VERSION ""

NS_ :

BS_:
BU_: AerodynamicControl AuxiliaryHeater1 AuxiliaryHeater2 AuxiliaryValveControl AxleDrive1 AxleDrive2 AxleSteering BodyController BrakesDriveAxle1 BrakesDriveAxle2 BrakesSteerAxle BrakesSystemController CabController1 CabController2 CabDisplay1 ChassisController1 ChassisController2 ClimateControl1 ClimateControl2 ClutchUnit CommunicationUnitCellular CommunicationUnitRadio CommunicationUnitSatellite CruiseControl ElectricalChargingSystem ElectricalSystem EnduranceBrakingSystem Engine1 Engine2 EngineValveControl ExhaustEmissionController FanDriveController FileServer FuelSystem HeadwayController HitchControl HydraulicPumpController IgnitionController1 IgnitionController2 InformationSystem1 InstrumentCluster LightingOperatorControl ManagementComputer Node_0 Node_1 Node_10 Node_11 Node_12 Node_129 Node_13 Node_130 Node_133 Node_14 Node_15 Node_16 Node_17 Node_18 Node_19 Node_2 Node_20 Node_21 Node_22 Node_23 Node_24 Node_248 Node_249 Node_25 Node_250 Node_251 Node_26 Node_27 Node_28 Node_29 Node_3 Node_30 Node_31 Node_32 Node_33 Node_34 Node_35 Node_36 Node_37 Node_38 Node_39 Node_4 Node_40 Node_41 Node_42 Node_43 Node_44 Node_45 Node_46 Node_47 Node_48 Node_49 Node_5 Node_50 Node_51 Node_52 Node_53 Node_54 Node_55 Node_56 Node_57 Node_58 Node_59 Node_6 Node_60 Node_61 Node_62 Node_63 Node_64 Node_65 Node_66 Node_67 Node_68 Node_69 Node_7 Node_70 Node_71 Node_72 Node_73 Node_74 Node_75 Node_76 Node_77 Node_78 Node_79 Node_8 Node_80 Node_9 OffBoardDiagnosticTool1 OffBoardDiagnosticTool2 OffVehicleGateway OilSensor OnBoardDataLogger OnBoardDiagnosticUnit ParkingBrakeController PneumaticSystemController PowerTakeOff PowerTakeOffFront PropulsionBatteryCharger RampControl RearAxleSteeringController RetarderDriveline RetarderEngine RetarderExhaustEngine1 RetarderExhaustEngine2 SeatControl2 SeatController1 ShiftConsolePrimary ShiftConsoleSecondary StarterSystem SteeringColumnUnit SteeringController SuspensionDriveAxle1 SuspensionDriveAxle2 SuspensionSteerAxle SuspensionSystemController1 SuspensionSystemController2 TirePressureController TractorTrailerBridge1 Transmission1 Transmission2 TransmissionDisplay1 TransmissionDisplay2 TripRecorder Turbocharger VehicleDynamicStability VehicleNavigation VehicleSecurity VirtualTerminal WaterPumpController

BO_ 2565865982 EBC1: 8 Vector__XXX
   SG_ EngAuxShutdownSwitch : 28|2@1+ (1,0) [0|3] "" Vector__XXX
   SG_ SrcAddrssOfCtrllngDvcFrBrkCntrl : 48|8@1+ (1,0) [0|255] "" Vector__XXX
   SG_ BrakePedalPos : 8|8@1+ (0.4,0) [0|100] "%" Vector__XXX
   SG_ TrctrMntdTrilerABSWarningSignal : 62|2@1+ (1,0) [0|3] "" Vector__XXX
   SG_ TrailerABSStatus : 60|2@1+ (1,0) [0|3] "" Vector__XXX
   SG_ HaltBrakeSwitch : 58|2@1+ (1,0) [0|3] "" Vector__XXX
   SG_ ATC_ASRInformationSignal : 46|2@1+ (1,0) [0|3] "" Vector__XXX
   SG_ ABS_EBSAmberWarningSignal : 44|2@1+ (1,0) [0|3] "" Vector__XXX
   SG_ EBSRedWarningSignal : 42|2@1+ (1,0) [0|3] "" Vector__XXX
   SG_ ABSFullyOperational : 40|2@1+ (1,0) [0|3] "" Vector__XXX
   SG_ EngRetarderSelection : 32|8@1+ (0.4,0) [0|100] "%" Vector__XXX
   SG_ RemoteAccelEnableSwitch : 30|2@1+ (1,0) [0|3] "" Vector__XXX
   SG_ EngDerateSwitch : 26|2@1+ (1,0) [0|3] "" Vector__XXX
   SG_ AccelInterlockSwitch : 24|2@1+ (1,0) [0|3] "" Vector__XXX
   SG_ TractionCtrlOverrideSwitch : 22|2@1+ (1,0) [0|3] "" Vector__XXX
   SG_ ASRHillHolderSwitch : 20|2@1+ (1,0) [0|3] "" Vector__XXX
   SG_ ASROffroadSwitch : 18|2@1+ (1,0) [0|3] "" Vector__XXX
   SG_ ABSOffroadSwitch : 16|2@1+ (1,0) [0|3] "" Vector__XXX
   SG_ EBSBrakeSwitch : 6|2@1+ (1,0) [0|3] "" Vector__XXX
   SG_ AntiLockBrakingActive : 4|2@1+ (1,0) [0|3] "" Vector__XXX
   SG_ ASRBrakeCtrlActive : 2|2@1+ (1,0) [0|3] "" Vector__XXX
   SG_ ASREngCtrlActive : 0|2@1+ (1,0) [0|3] "" Vector__XXX

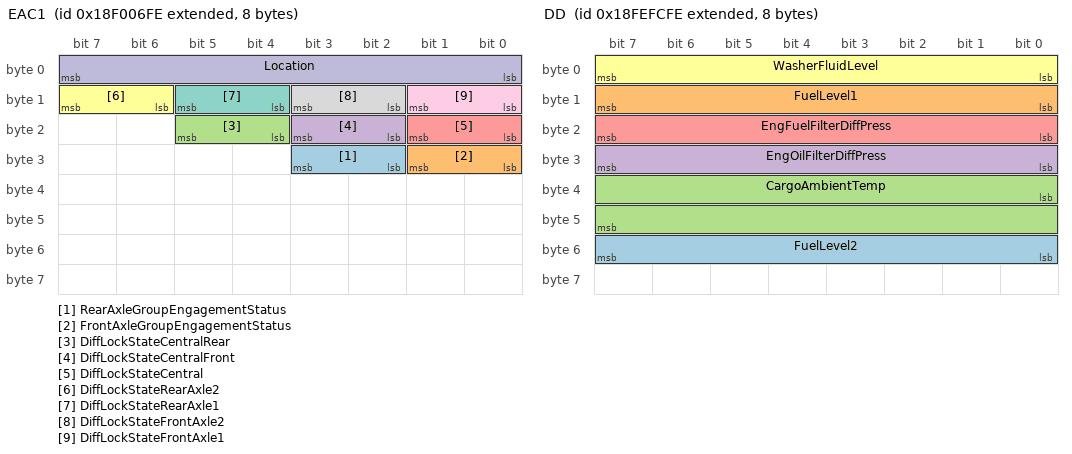
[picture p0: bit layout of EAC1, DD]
BO_ 2565867262 EAC1: 8 Vector__XXX
   SG_ RearAxleGroupEngagementStatus : 26|2@1+ (1,0) [0|3] "" Vector__XXX
   SG_ FrontAxleGroupEngagementStatus : 24|2@1+ (1,0) [0|3] "" Vector__XXX
   SG_ DiffLockStateCentralRear : 20|2@1+ (1,0) [0|3] "" Vector__XXX
   SG_ DiffLockStateCentralFront : 18|2@1+ (1,0) [0|3] "" Vector__XXX
   SG_ DiffLockStateCentral : 16|2@1+ (1,0) [0|3] "" Vector__XXX
   SG_ DiffLockStateRearAxle2 : 14|2@1+ (1,0) [0|3] "" Vector__XXX
   SG_ DiffLockStateRearAxle1 : 12|2@1+ (1,0) [0|3] "" Vector__XXX
   SG_ DiffLockStateFrontAxle2 : 10|2@1+ (1,0) [0|3] "" Vector__XXX
   SG_ DiffLockStateFrontAxle1 : 8|2@1+ (1,0) [0|3] "" Vector__XXX
   SG_ Location : 0|8@1+ (1,0) [0|255] "" Vector__XXX

BO_ 2566821118 EAC: 8 Vector__XXX
   SG_ SeaWaterPumpOutletPress : 16|8@1+ (2,0) [0|500] "kPa" Vector__XXX
   SG_ EngAuxCoolantTemp : 8|8@1+ (1,-40) [-40|210] "deg C" Vector__XXX
   SG_ EngAuxCoolantPress : 0|8@1+ (4,0) [0|1000] "kPa" Vector__XXX

BO_ 2566810622 DI: 8 Vector__XXX
   SG_ Driver2 : 8|8@1+ (1,0) [0|255] "" Vector__XXX
   SG_ Driver1 : 0|8@1+ (1,0) [0|255] "" Vector__XXX

BO_ 2566847742 DD: 8 Vector__XXX
   SG_ FuelLevel2 : 48|8@1+ (0.4,0) [0|100] "%" Vector__XXX
   SG_ FuelLevel1 : 8|8@1+ (0.4,0) [0|100] "%" Vector__XXX
   SG_ CargoAmbientTemp : 32|16@1+ (0.03125,-273) [-273|1734.97] "deg C" Vector__XXX
   SG_ EngOilFilterDiffPress : 24|8@1+ (0.5,0) [0|125] "kPa" Vector__XXX
   SG_ EngFuelFilterDiffPress : 16|8@1+ (2,0) [0|500] "kPa" Vector__XXX
   SG_ WasherFluidLevel : 0|8@1+ (0.4,0) [0|100] "%" Vector__XXX

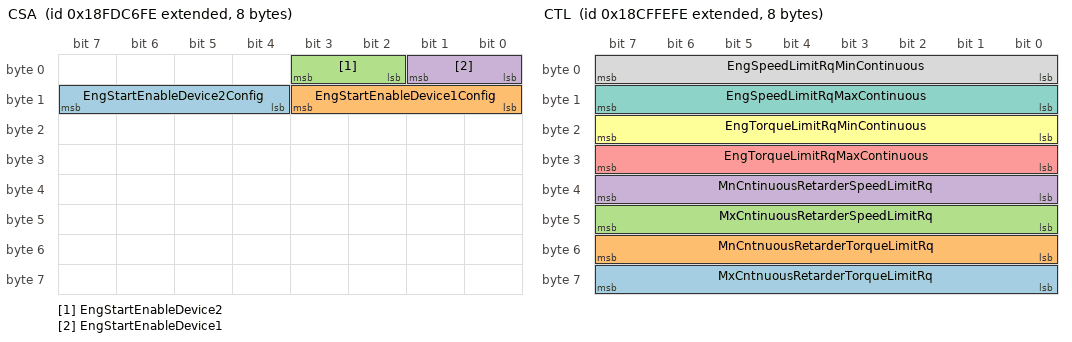
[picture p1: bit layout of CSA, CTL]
BO_ 2566768382 CSA: 8 Vector__XXX
   SG_ EngStartEnableDevice2Config : 12|4@1+ (1,0) [0|15] "" Vector__XXX
   SG_ EngStartEnableDevice1Config : 8|4@1+ (1,0) [0|15] "" Vector__XXX
   SG_ EngStartEnableDevice2 : 2|2@1+ (1,0) [0|3] "" Vector__XXX
   SG_ EngStartEnableDevice1 : 0|2@1+ (1,0) [0|3] "" Vector__XXX

BO_ 2566811902 CVW: 8 Vector__XXX
   SG_ PoweredVehicleWeight : 0|16@1+ (10,0) [0|642550] "kg" Vector__XXX
   SG_ GrossCombinationVehicleWeight : 16|16@1+ (10,0) [0|642550] "kg" Vector__XXX

BO_ 2563768062 CTL: 8 Vector__XXX
   SG_ MxCntnuousRetarderTorqueLimitRq : 56|8@1+ (1,-125) [-125|125] "%" Vector__XXX
   SG_ MnCntnuousRetarderTorqueLimitRq : 48|8@1+ (1,-125) [-125|125] "%" Vector__XXX
   SG_ MxCntinuousRetarderSpeedLimitRq : 40|8@1+ (32,0) [0|8000] "rpm" Vector__XXX
   SG_ MnCntinuousRetarderSpeedLimitRq : 32|8@1+ (32,0) [0|8000] "rpm" Vector__XXX
   SG_ EngTorqueLimitRqMaxContinuous : 24|8@1+ (1,-125) [-125|125] "%" Vector__XXX
   SG_ EngTorqueLimitRqMinContinuous : 16|8@1+ (1,-125) [-125|125] "%" Vector__XXX
   SG_ EngSpeedLimitRqMaxContinuous : 8|8@1+ (32,0) [0|8000] "rpm" Vector__XXX
   SG_ EngSpeedLimitRqMinContinuous : 0|8@1+ (32,0) [0|8000] "rpm" Vector__XXX

BO_ 2633924862 CT6: 8 Vector__XXX
   SG_ EngAverageCombustionTime : 16|16@1+ (0.01,0) [0|642.55] "ms" Vector__XXX
   SG_ EngDesiredCombustionTime : 0|16@1+ (0.01,0) [0|642.55] "ms" Vector__XXX

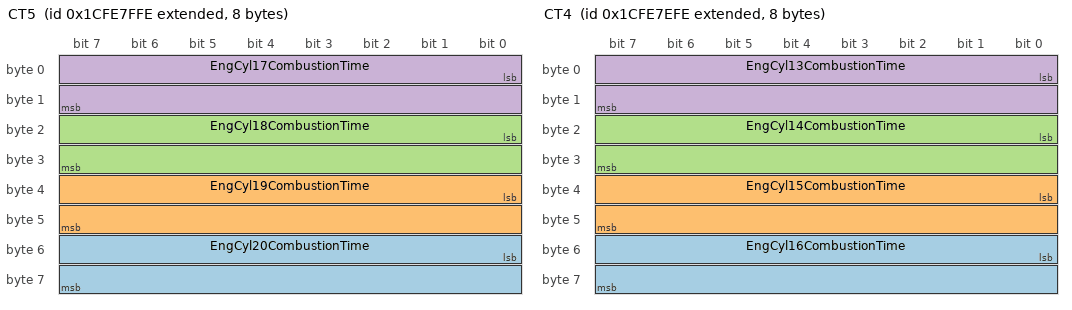
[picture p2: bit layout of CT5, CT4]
BO_ 2633924606 CT5: 8 Vector__XXX
   SG_ EngCyl20CombustionTime : 48|16@1+ (0.01,0) [0|642.55] "ms" Vector__XXX
   SG_ EngCyl19CombustionTime : 32|16@1+ (0.01,0) [0|642.55] "ms" Vector__XXX
   SG_ EngCyl18CombustionTime : 16|16@1+ (0.01,0) [0|642.55] "ms" Vector__XXX
   SG_ EngCyl17CombustionTime : 0|16@1+ (0.01,0) [0|642.55] "ms" Vector__XXX

BO_ 2633924350 CT4: 8 Vector__XXX
   SG_ EngCyl16CombustionTime : 48|16@1+ (0.01,0) [0|642.55] "ms" Vector__XXX
   SG_ EngCyl15CombustionTime : 32|16@1+ (0.01,0) [0|642.55] "ms" Vector__XXX
   SG_ EngCyl14CombustionTime : 16|16@1+ (0.01,0) [0|642.55] "ms" Vector__XXX
   SG_ EngCyl13CombustionTime : 0|16@1+ (0.01,0) [0|642.55] "ms" Vector__XXX

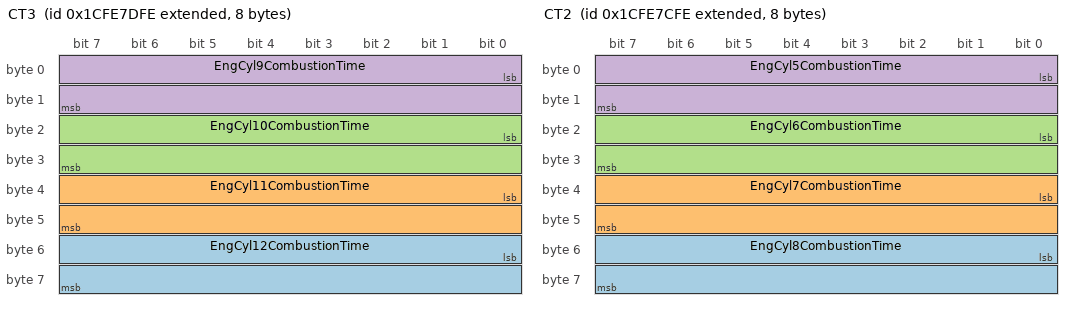
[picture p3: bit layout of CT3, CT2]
BO_ 2633924094 CT3: 8 Vector__XXX
   SG_ EngCyl12CombustionTime : 48|16@1+ (0.01,0) [0|642.55] "ms" Vector__XXX
   SG_ EngCyl11CombustionTime : 32|16@1+ (0.01,0) [0|642.55] "ms" Vector__XXX
   SG_ EngCyl10CombustionTime : 16|16@1+ (0.01,0) [0|642.55] "ms" Vector__XXX
   SG_ EngCyl9CombustionTime : 0|16@1+ (0.01,0) [0|642.55] "ms" Vector__XXX

BO_ 2633923838 CT2: 8 Vector__XXX
   SG_ EngCyl8CombustionTime : 48|16@1+ (0.01,0) [0|642.55] "ms" Vector__XXX
   SG_ EngCyl7CombustionTime : 32|16@1+ (0.01,0) [0|642.55] "ms" Vector__XXX
   SG_ EngCyl6CombustionTime : 16|16@1+ (0.01,0) [0|642.55] "ms" Vector__XXX
   SG_ EngCyl5CombustionTime : 0|16@1+ (0.01,0) [0|642.55] "ms" Vector__XXX

BO_ 2633923582 CT1: 8 Vector__XXX
   SG_ EngCyl4CombustionTime : 48|16@1+ (0.01,0) [0|642.55] "ms" Vector__XXX
   SG_ EngCyl3CombustionTime : 32|16@1+ (0.01,0) [0|642.55] "ms" Vector__XXX
   SG_ EngCyl2CombustionTime : 16|16@1+ (0.01,0) [0|642.55] "ms" Vector__XXX
   SG_ EngCyl1CombustionTime : 0|16@1+ (0.01,0) [0|642.55] "ms" Vector__XXX

BO_ 2633878014 CMI: 8 Vector__XXX
   SG_ TotalCountOfConfigChangesMade : 0|16@1+ (1,0) [0|64255] "counts" Vector__XXX

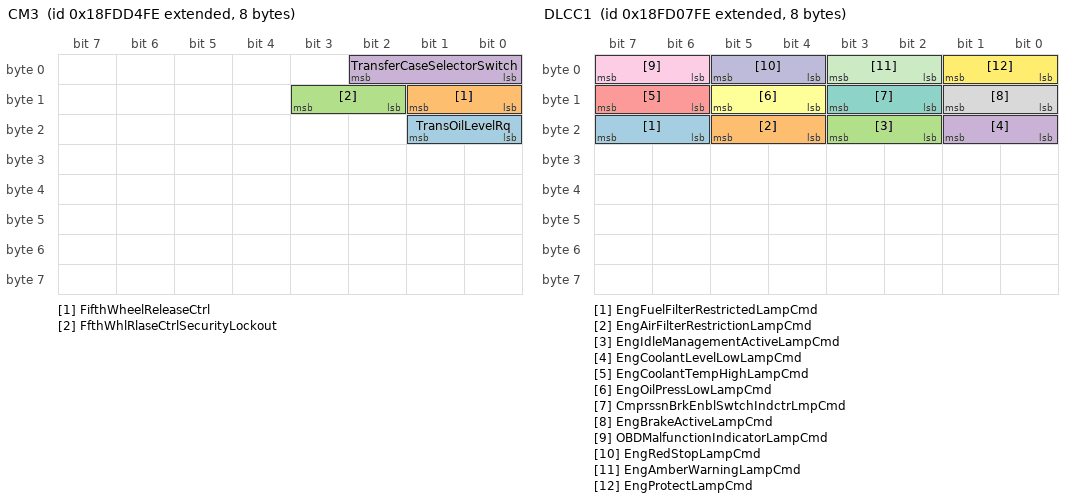
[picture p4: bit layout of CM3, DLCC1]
BO_ 2566771966 CM3: 8 Vector__XXX
   SG_ TransOilLevelRq : 16|2@1+ (1,0) [0|3] "" Vector__XXX
   SG_ FifthWheelReleaseCtrl : 8|2@1+ (1,0) [0|3] "" Vector__XXX
   SG_ FfthWhlRlaseCtrlSecurityLockout : 10|2@1+ (1,0) [0|3] "" Vector__XXX
   SG_ TransferCaseSelectorSwitch : 0|3@1+ (1,0) [0|7] "" Vector__XXX

BO_ 2564882174 CM1: 8 Vector__XXX
   SG_ DslPrtcltFltrRgnrtonForceSwitch : 42|2@1+ (1,0) [0|3] "" Vector__XXX
   SG_ DslPrtcltFltrRgnrtnInhbitSwitch : 40|2@1+ (1,0) [0|3] "" Vector__XXX
   SG_ SelectedMaxVehicleSpeedLimit : 56|8@1+ (1,0) [0|250] "" Vector__XXX
   SG_ RqCabZoneHeating : 54|2@1+ (1,0) [0|3] "" Vector__XXX
   SG_ RqEngZoneHeating : 52|2@1+ (1,0) [0|3] "" Vector__XXX
   SG_ AuxHeaterModeRq : 48|4@1+ (1,0) [0|15] "" Vector__XXX
   SG_ EngAutomaticStartEnableSwitch : 46|2@1+ (1,0) [0|3] "" Vector__XXX
   SG_ AtmaticGearShiftingEnableSwitch : 44|2@1+ (1,0) [0|3] "" Vector__XXX
   SG_ VhclLmtngSpdGvernorEnableSwitch : 38|2@1+ (1,0) [0|3] "" Vector__XXX
   SG_ VhclLmtngSpdGvrnrIncrmentSwitch : 36|2@1+ (1,0) [0|3] "" Vector__XXX
   SG_ VhclLmtngSpdGvrnrDcrementSwitch : 34|2@1+ (1,0) [0|3] "" Vector__XXX
   SG_ SeatBeltSwitch : 30|2@1+ (1,0) [0|3] "" Vector__XXX
   SG_ OperatorSeatDirectionSwitch : 28|2@1+ (1,0) [0|3] "" Vector__XXX
   SG_ BatteryMainSwitchHoldRq : 26|2@1+ (1,0) [0|3] "" Vector__XXX
   SG_ AuxHeaterCoolantPumpRq : 24|2@1+ (1,0) [0|3] "" Vector__XXX
   SG_ CabInteriorTempCmd : 8|16@1+ (0.03125,-273) [-273|1734.97] "deg C" Vector__XXX
   SG_ RqedPercentFanSpeed : 0|8@1+ (0.4,0) [0|100] "%" Vector__XXX

BO_ 2563833598 CL: 8 Vector__XXX
   SG_ IlluminationBrightnessPercent : 0|8@1+ (0.4,0) [0|100] "%" Vector__XXX

BO_ 2566843390 CI: 8 Vector__XXX
   SG_ UnitNumber : 24|8@1+ (1,0) [0|255] "" Vector__XXX
   SG_ SerialNumber : 16|8@1+ (1,0) [0|255] "" Vector__XXX
   SG_ Model : 8|8@1+ (1,0) [0|255] "" Vector__XXX
   SG_ Make : 0|8@1+ (1,0) [0|255] "" Vector__XXX

BO_ 2566844926 CCVS: 8 Vector__XXX
   SG_ ParkBrakeReleaseInhibitRq : 6|2@1+ (1,0) [0|3] "" Vector__XXX
   SG_ PTOGovernorState : 48|5@1+ (1,0) [0|31] "" Vector__XXX
   SG_ EngShutdownOverrideSwitch : 62|2@1+ (1,0) [0|3] "" Vector__XXX
   SG_ EngTestModeSwitch : 60|2@1+ (1,0) [0|3] "" Vector__XXX
   SG_ EngIdleDecrementSwitch : 58|2@1+ (1,0) [0|3] "" Vector__XXX
   SG_ EngIdleIncrementSwitch : 56|2@1+ (1,0) [0|3] "" Vector__XXX
   SG_ CruiseCtrlStates : 53|3@1+ (1,0) [0|7] "" Vector__XXX
   SG_ CruiseCtrlSetSpeed : 40|8@1+ (1,0) [0|250] "km/h" Vector__XXX
   SG_ CruiseCtrlAccelerateSwitch : 38|2@1+ (1,0) [0|3] "" Vector__XXX
   SG_ CruiseCtrlResumeSwitch : 36|2@1+ (1,0) [0|3] "" Vector__XXX
   SG_ CruiseCtrlCoastSwitch : 34|2@1+ (1,0) [0|3] "" Vector__XXX
   SG_ CruiseCtrlSetSwitch : 32|2@1+ (1,0) [0|3] "" Vector__XXX
   SG_ ClutchSwitch : 30|2@1+ (1,0) [0|3] "" Vector__XXX
   SG_ BrakeSwitch : 28|2@1+ (1,0) [0|3] "" Vector__XXX
   SG_ CruiseCtrlEnableSwitch : 26|2@1+ (1,0) [0|3] "" Vector__XXX
   SG_ CruiseCtrlActive : 24|2@1+ (1,0) [0|3] "" Vector__XXX
   SG_ WheelBasedVehicleSpeed : 8|16@1+ (0.00390625,0) [0|250.996] "km/h" Vector__XXX
   SG_ CruiseCtrlPauseSwitch : 4|2@1+ (1,0) [0|3] "" Vector__XXX
   SG_ ParkingBrakeSwitch : 2|2@1+ (1,0) [0|3] "" Vector__XXX
   SG_ TwoSpeedAxleSwitch : 0|2@1+ (1,0) [0|3] "" Vector__XXX

BO_ 2566843902 CCSS: 8 Vector__XXX
   SG_ CruiseCtrlLowSetLimitSpeed : 16|8@1+ (1,0) [0|250] "km/h" Vector__XXX
   SG_ CruiseCtrlHighSetLimitSpeed : 8|8@1+ (1,0) [0|250] "km/h" Vector__XXX
   SG_ MaxVehicleSpeedLimit : 0|8@1+ (1,0) [0|250] "km/h" Vector__XXX

BO_ 2566809598 CCC: 8 Vector__XXX
   SG_ AuxHeaterMaxOutputPower : 0|16@1+ (2,0) [0|128510] "W" Vector__XXX

BO_ 2633940222 CBI: 16 Vector__XXX
   SG_ TripServiceBrakeApps : 96|32@1+ (1,0) [0|4.22786e+09] "appl" Vector__XXX
   SG_ TripServiceBrakeDistance : 64|32@1+ (0.125,0) [0|5.26385e+08] "km" Vector__XXX
   SG_ TripCompressionBrakeDistance : 32|32@1+ (0.125,0) [0|5.26385e+08] "km" Vector__XXX
   SG_ TotalCompressionBrakeDistance : 0|32@1+ (0.125,0) [0|5.26385e+08] "km" Vector__XXX

BO_ 2566775294 CACI: 8 Vector__XXX
   SG_ CbA_CRfrgrntCmprssorOutletPress : 0|8@1+ (16,0) [0|4000] "kPa" Vector__XXX

BO_ 2566803710 BT1: 8 Vector__XXX
   SG_ Battery2Temp : 8|8@1+ (1,-40) [-40|210] "deg C" Vector__XXX
   SG_ Battery1Temp : 0|8@1+ (1,-40) [-40|210] "deg C" Vector__XXX

BO_ 2566719486 DLCC1: 8 Vector__XXX
   SG_ EngFuelFilterRestrictedLampCmd : 22|2@1+ (1,0) [0|3] "" Vector__XXX
   SG_ EngAirFilterRestrictionLampCmd : 20|2@1+ (1,0) [0|3] "" Vector__XXX
   SG_ EngIdleManagementActiveLampCmd : 18|2@1+ (1,0) [0|3] "" Vector__XXX
   SG_ EngCoolantLevelLowLampCmd : 16|2@1+ (1,0) [0|3] "" Vector__XXX
   SG_ EngCoolantTempHighLampCmd : 14|2@1+ (1,0) [0|3] "" Vector__XXX
   SG_ EngOilPressLowLampCmd : 12|2@1+ (1,0) [0|3] "" Vector__XXX
   SG_ CmprssnBrkEnblSwtchIndctrLmpCmd : 10|2@1+ (1,0) [0|3] "" Vector__XXX
   SG_ EngBrakeActiveLampCmd : 8|2@1+ (1,0) [0|3] "" Vector__XXX
   SG_ OBDMalfunctionIndicatorLampCmd : 6|2@1+ (1,0) [0|3] "" Vector__XXX
   SG_ EngRedStopLampCmd : 4|2@1+ (1,0) [0|3] "" Vector__XXX
   SG_ EngAmberWarningLampCmd : 2|2@1+ (1,0) [0|3] "" Vector__XXX
   SG_ EngProtectLampCmd : 0|2@1+ (1,0) [0|3] "" Vector__XXX

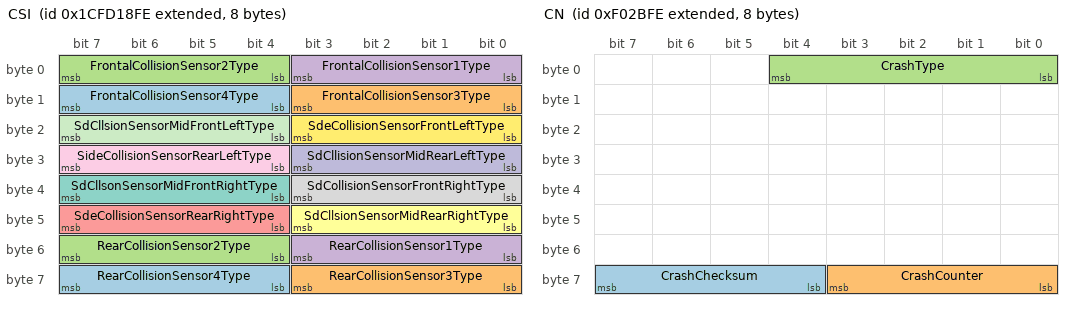
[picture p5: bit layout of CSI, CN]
BO_ 2633832702 CSI: 8 Vector__XXX
   SG_ RearCollisionSensor4Type : 60|4@1+ (1,0) [0|15] "" Vector__XXX
   SG_ RearCollisionSensor3Type : 56|4@1+ (1,0) [0|15] "" Vector__XXX
   SG_ RearCollisionSensor2Type : 52|4@1+ (1,0) [0|15] "" Vector__XXX
   SG_ RearCollisionSensor1Type : 48|4@1+ (1,0) [0|15] "" Vector__XXX
   SG_ SdeCollisionSensorRearRightType : 44|4@1+ (1,0) [0|15] "" Vector__XXX
   SG_ SdCllsionSensorMidRearRightType : 40|4@1+ (1,0) [0|15] "" Vector__XXX
   SG_ SdCllsonSensorMidFrontRightType : 36|4@1+ (1,0) [0|15] "" Vector__XXX
   SG_ SdCollisionSensorFrontRightType : 32|4@1+ (1,0) [0|15] "" Vector__XXX
   SG_ SideCollisionSensorRearLeftType : 28|4@1+ (1,0) [0|15] "" Vector__XXX
   SG_ SdCllisionSensorMidRearLeftType : 24|4@1+ (1,0) [0|15] "" Vector__XXX
   SG_ SdCllsionSensorMidFrontLeftType : 20|4@1+ (1,0) [0|15] "" Vector__XXX
   SG_ SdeCollisionSensorFrontLeftType : 16|4@1+ (1,0) [0|15] "" Vector__XXX
   SG_ FrontalCollisionSensor4Type : 12|4@1+ (1,0) [0|15] "" Vector__XXX
   SG_ FrontalCollisionSensor3Type : 8|4@1+ (1,0) [0|15] "" Vector__XXX
   SG_ FrontalCollisionSensor2Type : 4|4@1+ (1,0) [0|15] "" Vector__XXX
   SG_ FrontalCollisionSensor1Type : 0|4@1+ (1,0) [0|15] "" Vector__XXX

BO_ 2163223550 CN: 8 Vector__XXX
   SG_ CrashChecksum : 60|4@1+ (1,0) [0|15] "" Vector__XXX
   SG_ CrashCounter : 56|4@1+ (1,0) [0|15] "" Vector__XXX
   SG_ CrashType : 0|5@1+ (5,0) [0|0] "" Vector__XXX

BO_ 2566714878 CAC2P: 8 Vector__XXX
   SG_ EngChrgArClr2PrcoolerEfficiency : 32|8@1+ (0.4,0) [0|100] "%" Vector__XXX
   SG_ EngChrgArClr2PrcoolerOutletTemp : 16|16@1+ (0.03125,-273) [-273|1734.97] "deg C" Vector__XXX
   SG_ EngChrgArClr2PrcoolerIntakeTemp : 0|16@1+ (0.03125,-273) [-273|1734.97] "deg C" Vector__XXX

BO_ 2566714622 CAC2: 8 Vector__XXX
   SG_ EngChargeAirCooler2Efficiency : 48|8@1+ (0.4,0) [0|100] "%" Vector__XXX
   SG_ EngChrgAirCooler2AmbientAirTemp : 32|16@1+ (0.03125,-273) [-273|1734.97] "deg C" Vector__XXX
   SG_ EngChargeAirCooler2OutletTemp : 16|16@1+ (0.03125,-273) [-273|1734.97] "deg C" Vector__XXX
   SG_ EngChargeAirCooler2IntakeTemp : 0|16@1+ (0.03125,-273) [-273|1734.97] "deg C" Vector__XXX

BO_ 2566715390 CAC1P: 8 Vector__XXX
   SG_ EngChrgArClr1PrcoolerEfficiency : 32|8@1+ (0.4,0) [0|100] "%" Vector__XXX
   SG_ EngChrgArClr1PrcoolerOutletTemp : 16|16@1+ (0.03125,-273) [-273|1734.97] "deg C" Vector__XXX
   SG_ EngChrgArClr1PrcoolerIntakeTemp : 0|16@1+ (0.03125,-273) [-273|1734.97] "deg C" Vector__XXX

BO_ 2566715134 CAC1: 8 Vector__XXX
   SG_ EngChargeAirCooler1Efficiency : 32|8@1+ (0.4,0) [0|100] "%" Vector__XXX
   SG_ EngChrgAirCooler1AmbientAirTemp : 16|16@1+ (0.03125,-273) [-273|1734.97] "deg C" Vector__XXX
   SG_ EngChargeAirCooler1IntakeTemp : 0|16@1+ (0.03125,-273) [-273|1734.97] "deg C" Vector__XXX

BO_ 2365400830 BJM9: 8 Vector__XXX
   SG_ Joystick9Button9PressedStatus : 62|2@1+ (1,0) [0|3] "" Vector__XXX
   SG_ Joystick9Button10PressedStatus : 60|2@1+ (1,0) [0|3] "" Vector__XXX
   SG_ Joystick9Button11PressedStatus : 58|2@1+ (1,0) [0|3] "" Vector__XXX
   SG_ Joystick9Button12PressedStatus : 56|2@1+ (1,0) [0|3] "" Vector__XXX
   SG_ Joystick9Button5PressedStatus : 54|2@1+ (1,0) [0|3] "" Vector__XXX
   SG_ Joystick9Button6PressedStatus : 52|2@1+ (1,0) [0|3] "" Vector__XXX
   SG_ Joystick9Button7PressedStatus : 50|2@1+ (1,0) [0|3] "" Vector__XXX
   SG_ Joystick9Button8PressedStatus : 48|2@1+ (1,0) [0|3] "" Vector__XXX
   SG_ Joystick9Button1PressedStatus : 46|2@1+ (1,0) [0|3] "" Vector__XXX
   SG_ Joystick9Button2PressedStatus : 44|2@1+ (1,0) [0|3] "" Vector__XXX
   SG_ Joystick9Button3PressedStatus : 42|2@1+ (1,0) [0|3] "" Vector__XXX
   SG_ Joystick9Button4PressedStatus : 40|2@1+ (1,0) [0|3] "" Vector__XXX
   SG_ Joystick9XAxisDetentPosStatus : 38|2@1+ (1,0) [0|3] "" Vector__XXX
   SG_ Joystick9YAxisDetentPosStatus : 36|2@1+ (1,0) [0|3] "" Vector__XXX
   SG_ Joystick9YAxisPos : 22|10@1+ (0.1,0) [0|102] "%" Vector__XXX
   SG_ Jystck9YAxsLvrFrwrdPstvPsStatus : 20|2@1+ (1,0) [0|3] "" Vector__XXX
   SG_ Jystck9YAxsLvrBckNgtvePosStatus : 18|2@1+ (1,0) [0|3] "" Vector__XXX
   SG_ Joystick9YAxisNeutralPosStatus : 16|2@1+ (1,0) [0|3] "" Vector__XXX
   SG_ Joystick9XAxisPos : 6|10@1+ (0.1,0) [0|102] "%" Vector__XXX
   SG_ Jystck9XAxsLvrRghtPstvPosStatus : 4|2@1+ (1,0) [0|3] "" Vector__XXX
   SG_ Jystck9XAxsLvrLftNgtvePosStatus : 2|2@1+ (1,0) [0|3] "" Vector__XXX
   SG_ Joystick9XAxisNeutralPosStatus : 0|2@1+ (1,0) [0|3] "" Vector__XXX

BO_ 2365401342 BJM8: 8 Vector__XXX
   SG_ Joystick8Button9PressedStatus : 62|2@1+ (1,0) [0|3] "" Vector__XXX
   SG_ Joystick8Button10PressedStatus : 60|2@1+ (1,0) [0|3] "" Vector__XXX
   SG_ Joystick8Button11PressedStatus : 58|2@1+ (1,0) [0|3] "" Vector__XXX
   SG_ Joystick8Button12PressedStatus : 56|2@1+ (1,0) [0|3] "" Vector__XXX
   SG_ Joystick8Button5PressedStatus : 54|2@1+ (1,0) [0|3] "" Vector__XXX
   SG_ Joystick8Button6PressedStatus : 52|2@1+ (1,0) [0|3] "" Vector__XXX
   SG_ Joystick8Button7PressedStatus : 50|2@1+ (1,0) [0|3] "" Vector__XXX
   SG_ Joystick8Button8PressedStatus : 48|2@1+ (1,0) [0|3] "" Vector__XXX
   SG_ Joystick8Button1PressedStatus : 46|2@1+ (1,0) [0|3] "" Vector__XXX
   SG_ Joystick8Button2PressedStatus : 44|2@1+ (1,0) [0|3] "" Vector__XXX
   SG_ Joystick8Button3PressedStatus : 42|2@1+ (1,0) [0|3] "" Vector__XXX
   SG_ Joystick8Button4PressedStatus : 40|2@1+ (1,0) [0|3] "" Vector__XXX
   SG_ Joystick8XAxisDetentPosStatus : 38|2@1+ (1,0) [0|3] "" Vector__XXX
   SG_ Joystick8YAxisDetentPosStatus : 36|2@1+ (1,0) [0|3] "" Vector__XXX
   SG_ Joystick8YAxisPos : 22|10@1+ (0.1,0) [0|102] "%" Vector__XXX
   SG_ Jystck8YAxsLvrFrwrdPstvPsStatus : 20|2@1+ (1,0) [0|3] "" Vector__XXX
   SG_ Jystck8YAxsLvrBckNgtvePosStatus : 18|2@1+ (1,0) [0|3] "" Vector__XXX
   SG_ Joystick8YAxisNeutralPosStatus : 16|2@1+ (1,0) [0|3] "" Vector__XXX
   SG_ Joystick8XAxisPos : 6|10@1+ (0.1,0) [0|102] "%" Vector__XXX
   SG_ Jystck8XAxsLvrRghtPstvPosStatus : 4|2@1+ (1,0) [0|3] "" Vector__XXX
   SG_ Jystck8XAxsLvrLftNgtvePosStatus : 2|2@1+ (1,0) [0|3] "" Vector__XXX
   SG_ Joystick8XAxisNeutralPosStatus : 0|2@1+ (1,0) [0|3] "" Vector__XXX

BO_ 2365401854 BJM7: 8 Vector__XXX
   SG_ Joystick7Button9PressedStatus : 62|2@1+ (1,0) [0|3] "" Vector__XXX
   SG_ Joystick7Button10PressedStatus : 60|2@1+ (1,0) [0|3] "" Vector__XXX
   SG_ Joystick7Button11PressedStatus : 58|2@1+ (1,0) [0|3] "" Vector__XXX
   SG_ Joystick7Button12PressedStatus : 56|2@1+ (1,0) [0|3] "" Vector__XXX
   SG_ Joystick7Button5PressedStatus : 54|2@1+ (1,0) [0|3] "" Vector__XXX
   SG_ Joystick7Button6PressedStatus : 52|2@1+ (1,0) [0|3] "" Vector__XXX
   SG_ Joystick7Button7PressedStatus : 50|2@1+ (1,0) [0|3] "" Vector__XXX
   SG_ Joystick7Button8PressedStatus : 48|2@1+ (1,0) [0|3] "" Vector__XXX
   SG_ Joystick7Button1PressedStatus : 46|2@1+ (1,0) [0|3] "" Vector__XXX
   SG_ Joystick7Button2PressedStatus : 44|2@1+ (1,0) [0|3] "" Vector__XXX
   SG_ Joystick7Button3PressedStatus : 42|2@1+ (1,0) [0|3] "" Vector__XXX
   SG_ Joystick7Button4PressedStatus : 40|2@1+ (1,0) [0|3] "" Vector__XXX
   SG_ Joystick7XAxisDetentPosStatus : 38|2@1+ (1,0) [0|3] "" Vector__XXX
   SG_ Joystick7YAxisDetentPosStatus : 36|2@1+ (1,0) [0|3] "" Vector__XXX
   SG_ Joystick7YAxisPos : 22|10@1+ (0.1,0) [0|102] "%" Vector__XXX
   SG_ Jystck7YAxsLvrFrwrdPstvPsStatus : 20|2@1+ (1,0) [0|3] "" Vector__XXX
   SG_ Jystck7YAxsLvrBckNgtvePosStatus : 18|2@1+ (1,0) [0|3] "" Vector__XXX
   SG_ Joystick7YAxisNeutralPosStatus : 16|2@1+ (1,0) [0|3] "" Vector__XXX
   SG_ Joystick7XAxisPos : 6|10@1+ (0.1,0) [0|102] "%" Vector__XXX
   SG_ Jystck7XAxsLvrRghtPstvPosStatus : 4|2@1+ (1,0) [0|3] "" Vector__XXX
   SG_ Jystck7XAxsLvrLftNgtvePosStatus : 2|2@1+ (1,0) [0|3] "" Vector__XXX
   SG_ Joystick7XAxisNeutralPosStatus : 0|2@1+ (1,0) [0|3] "" Vector__XXX

BO_ 2365402366 BJM6: 8 Vector__XXX
   SG_ Joystick6Button9PressedStatus : 62|2@1+ (1,0) [0|3] "" Vector__XXX
   SG_ Joystick6Button10PressedStatus : 60|2@1+ (1,0) [0|3] "" Vector__XXX
   SG_ Joystick6Button11PressedStatus : 58|2@1+ (1,0) [0|3] "" Vector__XXX
   SG_ Joystick6Button12PressedStatus : 56|2@1+ (1,0) [0|3] "" Vector__XXX
   SG_ Joystick6Button5PressedStatus : 54|2@1+ (1,0) [0|3] "" Vector__XXX
   SG_ Joystick6Button6PressedStatus : 52|2@1+ (1,0) [0|3] "" Vector__XXX
   SG_ Joystick6Button7PressedStatus : 50|2@1+ (1,0) [0|3] "" Vector__XXX
   SG_ Joystick6Button8PressedStatus : 48|2@1+ (1,0) [0|3] "" Vector__XXX
   SG_ Joystick6Button1PressedStatus : 46|2@1+ (1,0) [0|3] "" Vector__XXX
   SG_ Joystick6Button2PressedStatus : 44|2@1+ (1,0) [0|3] "" Vector__XXX
   SG_ Joystick6Button3PressedStatus : 42|2@1+ (1,0) [0|3] "" Vector__XXX
   SG_ Joystick6Button4PressedStatus : 40|2@1+ (1,0) [0|3] "" Vector__XXX
   SG_ Joystick6XAxisDetentPosStatus : 38|2@1+ (1,0) [0|3] "" Vector__XXX
   SG_ Joystick6YAxisDetentPosStatus : 36|2@1+ (1,0) [0|3] "" Vector__XXX
   SG_ Joystick6YAxisPos : 22|10@1+ (0.1,0) [0|102] "%" Vector__XXX
   SG_ Jystck6YAxsLvrFrwrdPstvPsStatus : 20|2@1+ (1,0) [0|3] "" Vector__XXX
   SG_ Jystck6YAxsLvrBckNgtvePosStatus : 18|2@1+ (1,0) [0|3] "" Vector__XXX
   SG_ Joystick6YAxisNeutralPosStatus : 16|2@1+ (1,0) [0|3] "" Vector__XXX
   SG_ Joystick6XAxisPos : 6|10@1+ (0.1,0) [0|102] "%" Vector__XXX
   SG_ Jystck6XAxsLvrRghtPstvPosStatus : 4|2@1+ (1,0) [0|3] "" Vector__XXX
   SG_ Jystck6XAxsLvrLftNgtvePosStatus : 2|2@1+ (1,0) [0|3] "" Vector__XXX
   SG_ Joystick6XAxisNeutralPosStatus : 0|2@1+ (1,0) [0|3] "" Vector__XXX

BO_ 2365402878 BJM5: 8 Vector__XXX
   SG_ Joystick5Button9PressedStatus : 62|2@1+ (1,0) [0|3] "" Vector__XXX
   SG_ Joystick5Button10PressedStatus : 60|2@1+ (1,0) [0|3] "" Vector__XXX
   SG_ Joystick5Button11PressedStatus : 58|2@1+ (1,0) [0|3] "" Vector__XXX
   SG_ Joystick5Button12PressedStatus : 56|2@1+ (1,0) [0|3] "" Vector__XXX
   SG_ Joystick5Button5PressedStatus : 54|2@1+ (1,0) [0|3] "" Vector__XXX
   SG_ Joystick5Button6PressedStatus : 52|2@1+ (1,0) [0|3] "" Vector__XXX
   SG_ Joystick5Button7PressedStatus : 50|2@1+ (1,0) [0|3] "" Vector__XXX
   SG_ Joystick5Button8PressedStatus : 48|2@1+ (1,0) [0|3] "" Vector__XXX
   SG_ Joystick5Button1PressedStatus : 46|2@1+ (1,0) [0|3] "" Vector__XXX
   SG_ Joystick5Button2PressedStatus : 44|2@1+ (1,0) [0|3] "" Vector__XXX
   SG_ Joystick5Button3PressedStatus : 42|2@1+ (1,0) [0|3] "" Vector__XXX
   SG_ Joystick5Button4PressedStatus : 40|2@1+ (1,0) [0|3] "" Vector__XXX
   SG_ Joystick5XAxisDetentPosStatus : 38|2@1+ (1,0) [0|3] "" Vector__XXX
   SG_ Joystick5YAxisDetentPosStatus : 36|2@1+ (1,0) [0|3] "" Vector__XXX
   SG_ Joystick5YAxisPos : 22|10@1+ (0.1,0) [0|102] "%" Vector__XXX
   SG_ Jystck5YAxsLvrFrwrdPstvPsStatus : 20|2@1+ (1,0) [0|3] "" Vector__XXX
   SG_ Jystck5YAxsLvrBckNgtvePosStatus : 18|2@1+ (1,0) [0|3] "" Vector__XXX
   SG_ Joystick5YAxisNeutralPosStatus : 16|2@1+ (1,0) [0|3] "" Vector__XXX
   SG_ Joystick5XAxisPos : 6|10@1+ (0.1,0) [0|102] "%" Vector__XXX
   SG_ Jystck5XAxsLvrRghtPstvPosStatus : 4|2@1+ (1,0) [0|3] "" Vector__XXX
   SG_ Jystck5XAxsLvrLftNgtvePosStatus : 2|2@1+ (1,0) [0|3] "" Vector__XXX
   SG_ Joystick5XAxisNeutralPosStatus : 0|2@1+ (1,0) [0|3] "" Vector__XXX

BO_ 2365403390 BJM4: 8 Vector__XXX
   SG_ Joystick4Button9PressedStatus : 62|2@1+ (1,0) [0|3] "" Vector__XXX
   SG_ Joystick4Button10PressedStatus : 60|2@1+ (1,0) [0|3] "" Vector__XXX
   SG_ Joystick4Button11PressedStatus : 58|2@1+ (1,0) [0|3] "" Vector__XXX
   SG_ Joystick4Button12PressedStatus : 56|2@1+ (1,0) [0|3] "" Vector__XXX
   SG_ Joystick4Button5PressedStatus : 54|2@1+ (1,0) [0|3] "" Vector__XXX
   SG_ Joystick4Button6PressedStatus : 52|2@1+ (1,0) [0|3] "" Vector__XXX
   SG_ Joystick4Button7PressedStatus : 50|2@1+ (1,0) [0|3] "" Vector__XXX
   SG_ Joystick4Button8PressedStatus : 48|2@1+ (1,0) [0|3] "" Vector__XXX
   SG_ Joystick4Button1PressedStatus : 46|2@1+ (1,0) [0|3] "" Vector__XXX
   SG_ Joystick4Button2PressedStatus : 44|2@1+ (1,0) [0|3] "" Vector__XXX
   SG_ Joystick4Button3PressedStatus : 42|2@1+ (1,0) [0|3] "" Vector__XXX
   SG_ Joystick4Button4PressedStatus : 40|2@1+ (1,0) [0|3] "" Vector__XXX
   SG_ Joystick4XAxisDetentPosStatus : 38|2@1+ (1,0) [0|3] "" Vector__XXX
   SG_ Joystick4YAxisDetentPosStatus : 36|2@1+ (1,0) [0|3] "" Vector__XXX
   SG_ Joystick4YAxisPos : 22|10@1+ (0.1,0) [0|102] "%" Vector__XXX
   SG_ Jystck4YAxsLvrFrwrdPstvPsStatus : 20|2@1+ (1,0) [0|3] "" Vector__XXX
   SG_ Jystck4YAxsLvrBckNgtvePosStatus : 18|2@1+ (1,0) [0|3] "" Vector__XXX
   SG_ Joystick4YAxisNeutralPosStatus : 16|2@1+ (1,0) [0|3] "" Vector__XXX
   SG_ Joystick4XAxisPos : 6|10@1+ (0.1,0) [0|102] "%" Vector__XXX
   SG_ Jystck4XAxsLvrRghtPstvPosStatus : 4|2@1+ (1,0) [0|3] "" Vector__XXX
   SG_ Jystck4XAxsLvrLftNgtvePosStatus : 2|2@1+ (1,0) [0|3] "" Vector__XXX
   SG_ Joystick4XAxisNeutralPosStatus : 0|2@1+ (1,0) [0|3] "" Vector__XXX

BO_ 2365400318 BJM10: 8 Vector__XXX
   SG_ Joystick10Button9PressedStatus : 62|2@1+ (1,0) [0|3] "" Vector__XXX
   SG_ Joystick10Button10PressedStatus : 60|2@1+ (1,0) [0|3] "" Vector__XXX
   SG_ Joystick10Button11PressedStatus : 58|2@1+ (1,0) [0|3] "" Vector__XXX
   SG_ Joystick10Button12PressedStatus : 56|2@1+ (1,0) [0|3] "" Vector__XXX
   SG_ Joystick10Button5PressedStatus : 54|2@1+ (1,0) [0|3] "" Vector__XXX
   SG_ Joystick10Button6PressedStatus : 52|2@1+ (1,0) [0|3] "" Vector__XXX
   SG_ Joystick10Button7PressedStatus : 50|2@1+ (1,0) [0|3] "" Vector__XXX
   SG_ Joystick10Button8PressedStatus : 48|2@1+ (1,0) [0|3] "" Vector__XXX
   SG_ Joystick10Button1PressedStatus : 46|2@1+ (1,0) [0|3] "" Vector__XXX
   SG_ Joystick10Button2PressedStatus : 44|2@1+ (1,0) [0|3] "" Vector__XXX
   SG_ Joystick10Button3PressedStatus : 42|2@1+ (1,0) [0|3] "" Vector__XXX
   SG_ Joystick10Button4PressedStatus : 40|2@1+ (1,0) [0|3] "" Vector__XXX
   SG_ Joystick10XAxisDetentPosStatus : 38|2@1+ (1,0) [0|3] "" Vector__XXX
   SG_ Joystick10YAxisDetentPosStatus : 36|2@1+ (1,0) [0|3] "" Vector__XXX
   SG_ Joystick10YAxisPos : 22|10@1+ (0.1,0) [0|102] "%" Vector__XXX
   SG_ Jystck10YAxsLvrFrwrdPstvPsSttus : 20|2@1+ (1,0) [0|3] "" Vector__XXX
   SG_ Jystck10YAxsLvrBckNgtvPosStatus : 18|2@1+ (1,0) [0|3] "" Vector__XXX
   SG_ Joystick10YAxisNeutralPosStatus : 16|2@1+ (1,0) [0|3] "" Vector__XXX
   SG_ Joystick10XAxisPos : 6|10@1+ (0.1,0) [0|102] "%" Vector__XXX
   SG_ Jystck10XAxsLvrRghtPstvPsStatus : 4|2@1+ (1,0) [0|3] "" Vector__XXX
   SG_ Jystck10XAxsLvrLftNgtvPosStatus : 2|2@1+ (1,0) [0|3] "" Vector__XXX
   SG_ Joystick10XAxisNeutralPosStatus : 0|2@1+ (1,0) [0|3] "" Vector__XXX

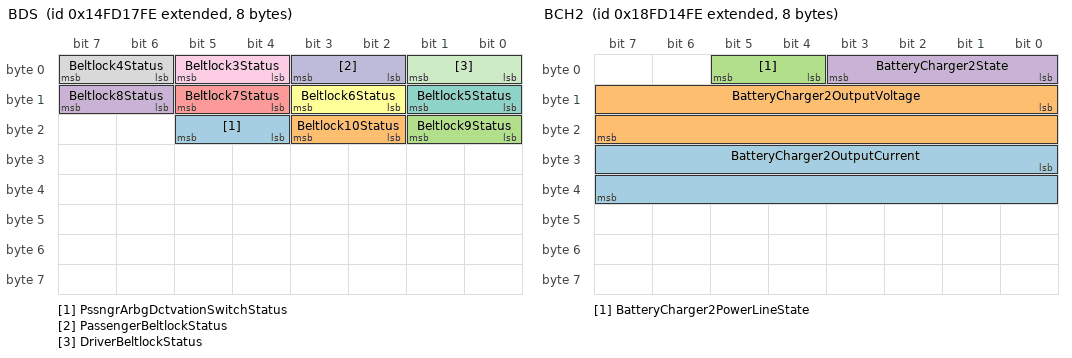
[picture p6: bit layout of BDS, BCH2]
BO_ 2499614718 BDS: 8 Vector__XXX
   SG_ PssngrArbgDctvationSwitchStatus : 20|2@1+ (1,0) [0|3] "" Vector__XXX
   SG_ Beltlock10Status : 18|2@1+ (1,0) [0|3] "" Vector__XXX
   SG_ Beltlock9Status : 16|2@1+ (1,0) [0|3] "" Vector__XXX
   SG_ Beltlock8Status : 14|2@1+ (1,0) [0|3] "" Vector__XXX
   SG_ Beltlock7Status : 12|2@1+ (1,0) [0|3] "" Vector__XXX
   SG_ Beltlock6Status : 10|2@1+ (1,0) [0|3] "" Vector__XXX
   SG_ Beltlock5Status : 8|2@1+ (1,0) [0|3] "" Vector__XXX
   SG_ Beltlock4Status : 6|2@1+ (1,0) [0|3] "" Vector__XXX
   SG_ Beltlock3Status : 4|2@1+ (1,0) [0|3] "" Vector__XXX
   SG_ PassengerBeltlockStatus : 2|2@1+ (1,0) [0|3] "" Vector__XXX
   SG_ DriverBeltlockStatus : 0|2@1+ (1,0) [0|3] "" Vector__XXX

BO_ 2566722814 BCH2: 8 Vector__XXX
   SG_ BatteryCharger2OutputCurrent : 24|16@1+ (0.05,-1600) [-1600|1612.75] "A" Vector__XXX
   SG_ BatteryCharger2OutputVoltage : 8|16@1+ (0.05,0) [0|3212.75] "V" Vector__XXX
   SG_ BatteryCharger2PowerLineState : 4|2@1+ (1,0) [0|3] "" Vector__XXX
   SG_ BatteryCharger2State : 0|4@1+ (1,0) [0|15] "" Vector__XXX

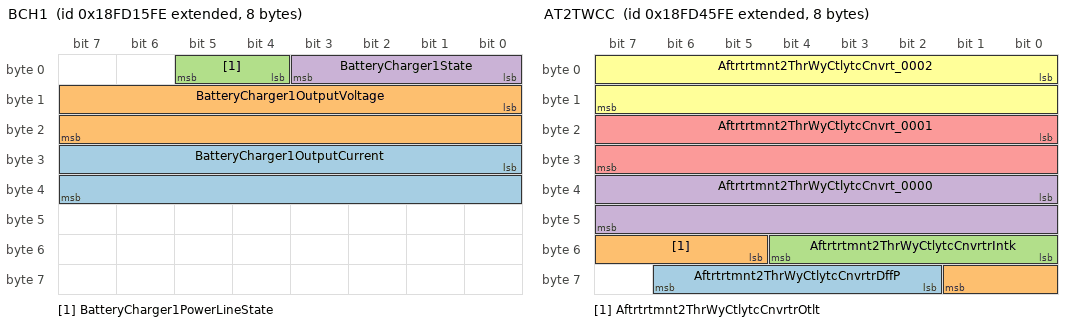
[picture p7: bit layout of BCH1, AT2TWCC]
BO_ 2566723070 BCH1: 8 Vector__XXX
   SG_ BatteryCharger1OutputCurrent : 24|16@1+ (0.05,-1600) [-1600|1612.75] "A" Vector__XXX
   SG_ BatteryCharger1OutputVoltage : 8|16@1+ (0.05,0) [0|3212.75] "V" Vector__XXX
   SG_ BatteryCharger1PowerLineState : 4|2@1+ (1,0) [0|3] "" Vector__XXX
   SG_ BatteryCharger1State : 0|4@1+ (1,0) [0|15] "" Vector__XXX

BO_ 2566725118 ATDT2: 8 Vector__XXX
   SG_ Aftrtrtmnt2ThrWyCtlystDffGsTemp : 16|16@1+ (0.03125,-273) [-273|1734.97] "deg C" Vector__XXX
   SG_ Aftrtrtmnt1ThrWyCtlystDffGsTemp : 0|16@1+ (0.03125,-273) [-273|1734.97] "deg C" Vector__XXX

BO_ 2566725374 ATDT1: 8 Vector__XXX
   SG_ Aftrtrtmnt2GsOxdtnCtlystDffGsTmp : 16|16@1+ (0.03125,-273) [-273|1734.97] "deg C" Vector__XXX
   SG_ Aftrtrtmnt1GsOxdtnCtlystDffGsTmp : 0|16@1+ (0.03125,-273) [-273|1734.97] "deg C" Vector__XXX

BO_ 2566712830 AT2WUDOC: 8 Vector__XXX
   SG_ Aftrtrtmnt2WrmUpDslOxdtnCtlystOt : 16|16@1+ (0.03125,-273) [-273|1734.97] "deg C" Vector__XXX
   SG_ Aftrtrtmnt2WrmUpDslOxdtnCtlystIn : 0|16@1+ (0.03125,-273) [-273|1734.97] "deg C" Vector__XXX

BO_ 2566735358 AT2TWCC: 8 Vector__XXX
   SG_ Aftrtrtmnt2ThrWyCtlytcCnvrtrDffP : 58|5@1+ (1,0) [0|31] "" Vector__XXX
   SG_ Aftrtrtmnt2ThrWyCtlytcCnvrtrOtlt : 53|5@1+ (1,0) [0|31] "" Vector__XXX
   SG_ Aftrtrtmnt2ThrWyCtlytcCnvrtrIntk : 48|5@1+ (1,0) [0|31] "" Vector__XXX
   SG_ Aftrtrtmnt2ThrWyCtlytcCnvrt_0000 : 32|16@1+ (0.1,0) [0|6425.5] "kPa" Vector__XXX
   SG_ Aftrtrtmnt2ThrWyCtlytcCnvrt_0001 : 16|16@1+ (0.03125,-273) [-273|1734.97] "deg C" Vector__XXX
   SG_ Aftrtrtmnt2ThrWyCtlytcCnvrt_0002 : 0|16@1+ (0.03125,-273) [-273|1734.97] "deg C" Vector__XXX

BO_ 2365393662 AT2OGC2: 8 Vector__XXX
   SG_ Aftrtrtmnt2OtltGsNOxSnsrNH3Crrct : 24|8@1+ (0.5,0) [0|125] "%" Vector__XXX
   SG_ Aftrtrtmnt2OtltGsNOxSnsrNO2Crrct : 16|8@1+ (0.5,0) [0|125] "%" Vector__XXX
   SG_ Aftrtrtmnt2OtltGsNOxSnsrCrrctnOf : 8|8@1+ (0.5,0) [0|125] "%/bar" Vector__XXX
   SG_ Aftrtrtmnt2OtltGsNOxSnsrCrr_0000 : 0|8@1+ (0.5,0) [0|125] "%/bar" Vector__XXX

BO_ 2365393918 AT2OGC1: 8 Vector__XXX
   SG_ Aftrtrtmnt2OtltGsNOxSnsrNwPrtDvt : 32|8@1+ (1,-125) [-125|125] "ppm" Vector__XXX
   SG_ Aftrtrtmnt2OtltGsNOxSnsrNwP_0000 : 16|16@1+ (0.1,-100) [-100|100] "%" Vector__XXX
   SG_ Aftrtrtmnt2OtltGsNOxSnsrHtrRtio : 0|16@1+ (0.001,0) [0|64.255] "" Vector__XXX

BO_ 2365394174 AT2IGC2: 8 Vector__XXX
   SG_ Aftrtrtmnt2IntkGsNOxSnsrNH3Crrct : 24|8@1+ (0.5,0) [0|125] "%" Vector__XXX
   SG_ Aftrtrtmnt2IntkGsNOxSnsrNO2Crrct : 16|8@1+ (0.5,0) [0|125] "%" Vector__XXX
   SG_ Aftrtrtmnt2IntkGsNOxSnsrCrrctnOf : 8|8@1+ (0.5,0) [0|125] "%/bar" Vector__XXX
   SG_ Aftrtrtmnt2IntkGsNOxSnsrCrr_0000 : 0|8@1+ (0.5,0) [0|125] "%/bar" Vector__XXX

BO_ 2365394430 AT2IGC1: 8 Vector__XXX
   SG_ Aftrtrtmnt2IntkGsNOxSnsrNwPrtDvt : 32|8@1+ (1,-125) [-125|125] "ppm" Vector__XXX
   SG_ Aftrtrtmnt2IntkGsNOxSnsrNwP_0000 : 16|16@1+ (0.1,-100) [-100|100] "%" Vector__XXX
   SG_ Aftrtrtmnt2IntkGsNOxSnsrHtrRtio : 0|16@1+ (0.001,0) [0|64.255] "" Vector__XXX

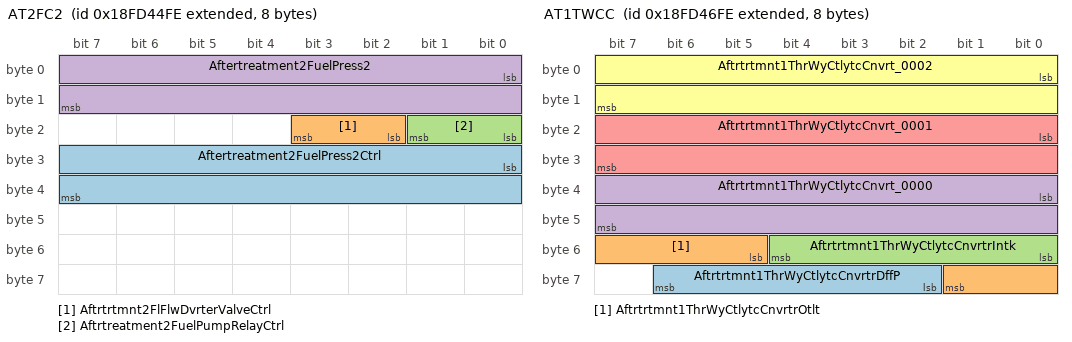
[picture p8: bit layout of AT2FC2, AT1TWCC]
BO_ 2566735102 AT2FC2: 8 Vector__XXX
   SG_ Aftertreatment2FuelPress2Ctrl : 24|16@1+ (0.0025,0) [0|160.637] "%" Vector__XXX
   SG_ Aftrtrtmnt2FlFlwDvrterValveCtrl : 18|2@1+ (1,0) [0|3] "" Vector__XXX
   SG_ Aftrtreatment2FuelPumpRelayCtrl : 16|2@1+ (1,0) [0|3] "" Vector__XXX
   SG_ Aftertreatment2FuelPress2 : 0|16@1+ (0.1,0) [0|6425.5] "kPa" Vector__XXX

BO_ 2157313790 AT2DPFSSC: 8 Vector__XXX
   SG_ Aftrtrtmnt2DslPrtcltFltrStStndrd : 16|16@1+ (0.0025,0) [0|160.637] "%" Vector__XXX
   SG_ Aftrtrtmnt2DslPrtcltFltrStMnClbO : 0|16@1+ (0.0025,0) [0|160.637] "%" Vector__XXX

BO_ 2566724350 AT1WUDOC: 8 Vector__XXX
   SG_ Aftrtrtmnt1WrmUpDslOxdtnCtlystOt : 16|16@1+ (0.03125,-273) [-273|1734.97] "deg C" Vector__XXX
   SG_ Aftrtrtmnt1WrmUpDslOxdtnCtlystIn : 0|16@1+ (0.03125,-273) [-273|1734.97] "deg C" Vector__XXX

BO_ 2566735614 AT1TWCC: 8 Vector__XXX
   SG_ Aftrtrtmnt1ThrWyCtlytcCnvrtrDffP : 58|5@1+ (1,0) [0|31] "" Vector__XXX
   SG_ Aftrtrtmnt1ThrWyCtlytcCnvrtrOtlt : 53|5@1+ (1,0) [0|31] "" Vector__XXX
   SG_ Aftrtrtmnt1ThrWyCtlytcCnvrtrIntk : 48|5@1+ (1,0) [0|31] "" Vector__XXX
   SG_ Aftrtrtmnt1ThrWyCtlytcCnvrt_0000 : 32|16@1+ (0.1,0) [0|6425.5] "kPa" Vector__XXX
   SG_ Aftrtrtmnt1ThrWyCtlytcCnvrt_0001 : 16|16@1+ (0.03125,-273) [-273|1734.97] "deg C" Vector__XXX
   SG_ Aftrtrtmnt1ThrWyCtlytcCnvrt_0002 : 0|16@1+ (0.03125,-273) [-273|1734.97] "deg C" Vector__XXX

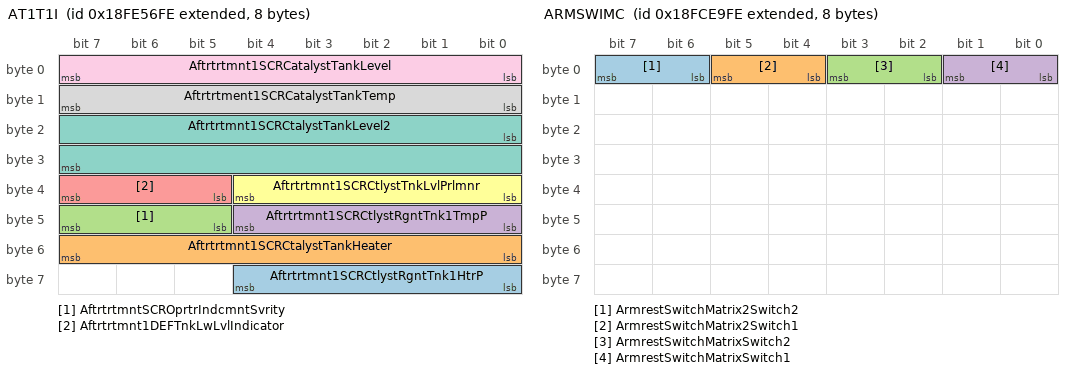
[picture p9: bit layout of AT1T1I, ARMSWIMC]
BO_ 2566805246 AT1T1I: 8 Vector__XXX
   SG_ Aftrtrtmnt1SCRCtlystRgntTnk1HtrP : 56|5@1+ (1,0) [0|31] "" Vector__XXX
   SG_ Aftrtrtmnt1SCRCtalystTankHeater : 48|8@1+ (0.4,0) [0|100] "%" Vector__XXX
   SG_ AftrtrtmntSCROprtrIndcmntSvrity : 45|3@1+ (1,0) [0|7] "" Vector__XXX
   SG_ Aftrtrtmnt1SCRCtlystRgntTnk1TmpP : 40|5@1+ (1,0) [0|31] "" Vector__XXX
   SG_ Aftrtrtmnt1DEFTnkLwLvlIndicator : 37|3@1+ (1,0) [0|7] "" Vector__XXX
   SG_ Aftrtrtmnt1SCRCtlystTnkLvlPrlmnr : 32|5@1+ (1,0) [0|31] "" Vector__XXX
   SG_ Aftrtrtmnt1SCRCtalystTankLevel2 : 16|16@1+ (0.1,0) [0|6425.5] "mm" Vector__XXX
   SG_ Aftrtrtment1SCRCatalystTankTemp : 8|8@1+ (1,-40) [-40|210] "deg C" Vector__XXX
   SG_ Aftrtrtmnt1SCRCatalystTankLevel : 0|8@1+ (0.4,0) [0|100] "%" Vector__XXX

BO_ 2365394686 AT1OGC2: 8 Vector__XXX
   SG_ Aftrtrtmnt1OtltGsNOxSnsrNH3Crrct : 24|8@1+ (0.5,0) [0|125] "%" Vector__XXX
   SG_ Aftrtrtmnt1OtltGsNOxSnsrNO2Crrct : 16|8@1+ (0.5,0) [0|125] "%" Vector__XXX
   SG_ Aftrtrtmnt1OtltGsNOxSnsrCrrctnOf : 8|8@1+ (0.5,0) [0|125] "%/bar" Vector__XXX
   SG_ Aftrtrtmnt1OtltGsNOxSnsrCrr_0000 : 0|8@1+ (0.5,0) [0|125] "%/bar" Vector__XXX

BO_ 2365394942 AT1OGC1: 8 Vector__XXX
   SG_ Aftrtrtmnt1OtltGsNOxSnsrNwPrtDvt : 32|8@1+ (1,-125) [-125|125] "ppm" Vector__XXX
   SG_ Aftrtrtmnt1OtltGsNOxSnsrNwP_0000 : 16|16@1+ (0.1,-100) [-100|100] "%" Vector__XXX
   SG_ Aftrtrtmnt1OtltGsNOxSnsrHtrRtio : 0|16@1+ (0.001,0) [0|64.255] "" Vector__XXX

BO_ 2365395198 AT1IGC2: 8 Vector__XXX
   SG_ Aftrtrtmnt1IntkGsNOxSnsrNH3Crrct : 24|8@1+ (0.5,0) [0|125] "%" Vector__XXX
   SG_ Aftrtrtmnt1IntkGsNOxSnsrNO2Crrct : 16|8@1+ (0.5,0) [0|125] "%" Vector__XXX
   SG_ Aftrtrtmnt1IntkGsNOxSnsrCrrctnOf : 8|8@1+ (0.5,0) [0|125] "%/bar" Vector__XXX
   SG_ Aftrtrtmnt1IntkGsNOxSnsrCrr_0000 : 0|8@1+ (0.5,0) [0|125] "%/bar" Vector__XXX

BO_ 2365395454 AT1IGC1: 8 Vector__XXX
   SG_ Aftrtrtmnt1IntkGsNOxSnsrNwPrtDvt : 32|8@1+ (1,-125) [-125|125] "ppm" Vector__XXX
   SG_ Aftrtrtmnt1IntkGsNOxSnsrNwP_0000 : 16|16@1+ (0.1,-100) [-100|100] "%" Vector__XXX
   SG_ Aftrtrtmnt1IntkGsNOxSnsrHtrRtio : 0|16@1+ (0.001,0) [0|64.255] "" Vector__XXX

BO_ 2157248254 AT1DPFSSC: 8 Vector__XXX
   SG_ Aftrtrtmnt1DslPrtcltFltrStStndrd : 16|16@1+ (0.0025,0) [0|160.637] "%" Vector__XXX
   SG_ Aftrtrtmnt1DslPrtcltFltrStMnClbO : 0|16@1+ (0.0025,0) [0|160.637] "%" Vector__XXX

BO_ 2566711806 ARMSWIMC: 8 Vector__XXX
   SG_ ArmrestSwitchMatrix2Switch2 : 6|2@1+ (1,0) [0|3] "" Vector__XXX
   SG_ ArmrestSwitchMatrix2Switch1 : 4|2@1+ (1,0) [0|3] "" Vector__XXX
   SG_ ArmrestSwitchMatrixSwitch2 : 2|2@1+ (1,0) [0|3] "" Vector__XXX
   SG_ ArmrestSwitchMatrixSwitch1 : 0|2@1+ (1,0) [0|3] "" Vector__XXX

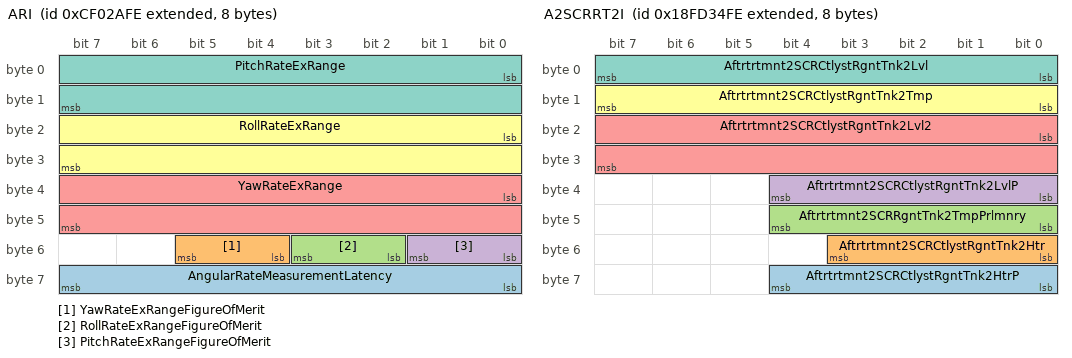
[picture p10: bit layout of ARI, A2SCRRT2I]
BO_ 2364549886 ARI: 8 Vector__XXX
   SG_ AngularRateMeasurementLatency : 56|8@1+ (0.5,0) [0|125] "ms" Vector__XXX
   SG_ YawRateExRangeFigureOfMerit : 52|2@1+ (1,0) [0|3] "" Vector__XXX
   SG_ RollRateExRangeFigureOfMerit : 50|2@1+ (1,0) [0|3] "" Vector__XXX
   SG_ PitchRateExRangeFigureOfMerit : 48|2@1+ (1,0) [0|3] "" Vector__XXX
   SG_ YawRateExRange : 32|16@1+ (0.0078125,-250) [-250|250.992] "deg/sec" Vector__XXX
   SG_ RollRateExRange : 16|16@1+ (0.0078125,-250) [-250|250.992] "deg/sec" Vector__XXX
   SG_ PitchRateExRange : 0|16@1+ (0.0078125,-250) [-250|250.992] "deg/sec" Vector__XXX

BO_ 2566712318 AFT2NAI: 8 Vector__XXX
   SG_ Aftrtrtmnt2NOxAdsrbrDSOxRgnrtnSt : 2|2@1+ (1,0) [0|3] "" Vector__XXX
   SG_ Aftrtrtmnt2NOxAdsrbrDNOxRgnrtnSt : 0|2@1+ (1,0) [0|3] "" Vector__XXX

BO_ 2566712574 AFT1NAI: 8 Vector__XXX
   SG_ Aftrtrtmnt1NOxAdsrbrDSOxRgnrtnSt : 2|2@1+ (1,0) [0|3] "" Vector__XXX
   SG_ Aftrtrtmnt1NOxAdsrbrDNOxRgnrtnSt : 0|2@1+ (1,0) [0|3] "" Vector__XXX

BO_ 2164078590 A2SCRSI: 8 Vector__XXX
   SG_ Aftrtrtmnt2SCRCtlystCnvrsnEffcnc : 32|8@1+ (0.4,0) [0|100] "%" Vector__XXX
   SG_ Aftrtrtmnt2SCRCmddCtlystRgntCnsm : 16|16@1+ (0.05,0) [0|3212.75] "L/h" Vector__XXX
   SG_ Aftrtrtmnt2SCRAvrgCtlystRgntCnsm : 0|16@1+ (0.05,0) [0|3212.75] "L/h" Vector__XXX

BO_ 2566731006 A2SCRRT2I: 8 Vector__XXX
   SG_ Aftrtrtmnt2SCRCtlystRgntTnk2HtrP : 56|5@1+ (1,0) [0|31] "" Vector__XXX
   SG_ Aftrtrtmnt2SCRCtlystRgntTnk2Htr : 48|4@1+ (1,0) [0|15] "" Vector__XXX
   SG_ Aftrtrtmnt2SCRRgntTnk2TmpPrlmnry : 40|5@1+ (1,0) [0|31] "" Vector__XXX
   SG_ Aftrtrtmnt2SCRCtlystRgntTnk2LvlP : 32|5@1+ (1,0) [0|31] "" Vector__XXX
   SG_ Aftrtrtmnt2SCRCtlystRgntTnk2Lvl2 : 16|16@1+ (0.1,0) [0|6425.5] "mm" Vector__XXX
   SG_ Aftrtrtmnt2SCRCtlystRgntTnk2Tmp : 8|8@1+ (1,-40) [-40|210] "deg C" Vector__XXX
   SG_ Aftrtrtmnt2SCRCtlystRgntTnk2Lvl : 0|8@1+ (0.4,0) [0|100] "%" Vector__XXX

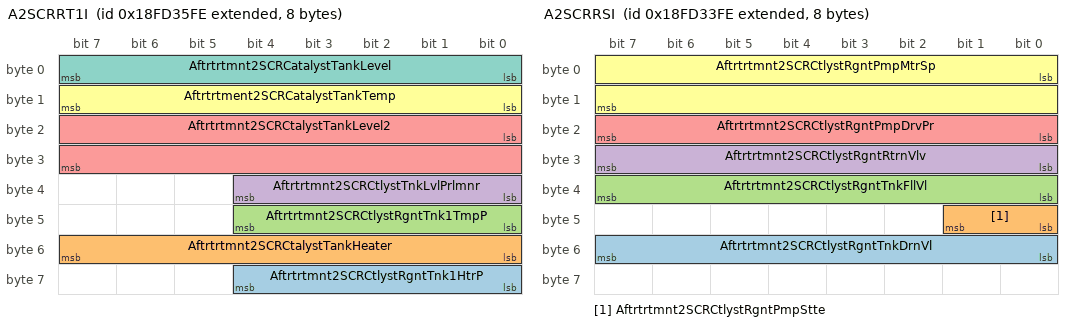
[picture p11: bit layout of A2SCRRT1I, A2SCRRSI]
BO_ 2566731262 A2SCRRT1I: 8 Vector__XXX
   SG_ Aftrtrtmnt2SCRCtlystRgntTnk1HtrP : 56|5@1+ (1,0) [0|31] "" Vector__XXX
   SG_ Aftrtrtmnt2SCRCtalystTankHeater : 48|8@1+ (0.4,0) [0|100] "%" Vector__XXX
   SG_ Aftrtrtmnt2SCRCtlystRgntTnk1TmpP : 40|5@1+ (1,0) [0|31] "" Vector__XXX
   SG_ Aftrtrtmnt2SCRCtlystTnkLvlPrlmnr : 32|5@1+ (1,0) [0|31] "" Vector__XXX
   SG_ Aftrtrtmnt2SCRCtalystTankLevel2 : 16|16@1+ (0.1,0) [0|6425.5] "mm" Vector__XXX
   SG_ Aftrtrtment2SCRCatalystTankTemp : 8|8@1+ (1,-40) [-40|210] "deg C" Vector__XXX
   SG_ Aftrtrtmnt2SCRCatalystTankLevel : 0|8@1+ (0.4,0) [0|100] "%" Vector__XXX

BO_ 2566730750 A2SCRRSI: 8 Vector__XXX
   SG_ Aftrtrtmnt2SCRCtlystRgntTnkDrnVl : 48|8@1+ (0.4,0) [0|100] "%" Vector__XXX
   SG_ Aftrtrtmnt2SCRCtlystRgntPmpStte : 40|2@1+ (1,0) [0|3] "" Vector__XXX
   SG_ Aftrtrtmnt2SCRCtlystRgntTnkFllVl : 32|8@1+ (0.4,0) [0|100] "%" Vector__XXX
   SG_ Aftrtrtmnt2SCRCtlystRgntRtrnVlv : 24|8@1+ (0.4,0) [0|100] "%" Vector__XXX
   SG_ Aftrtrtmnt2SCRCtlystRgntPmpDrvPr : 16|8@1+ (0.4,0) [0|100] "%" Vector__XXX
   SG_ Aftrtrtmnt2SCRCtlystRgntPmpMtrSp : 0|16@1+ (0.5,0) [0|32127.5] "rpm" Vector__XXX

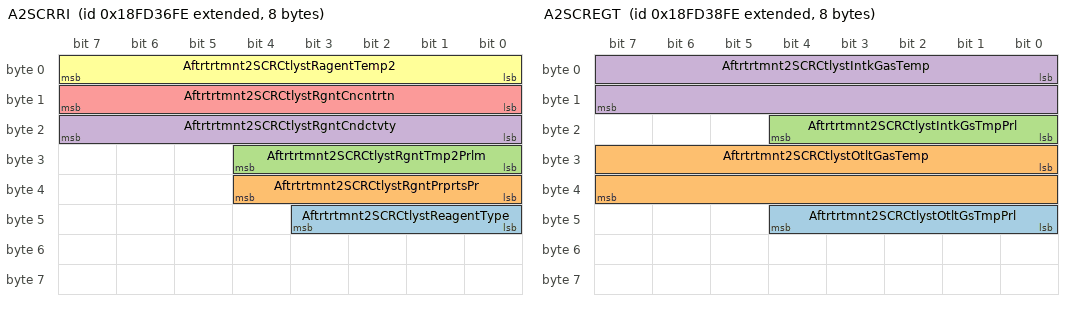
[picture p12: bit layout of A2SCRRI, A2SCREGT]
BO_ 2566731518 A2SCRRI: 8 Vector__XXX
   SG_ Aftrtrtmnt2SCRCtlystReagentType : 40|4@1+ (1,0) [0|15] "" Vector__XXX
   SG_ Aftrtrtmnt2SCRCtlystRgntPrprtsPr : 32|5@1+ (1,0) [0|31] "" Vector__XXX
   SG_ Aftrtrtmnt2SCRCtlystRgntTmp2Prlm : 24|5@1+ (1,0) [0|31] "" Vector__XXX
   SG_ Aftrtrtmnt2SCRCtlystRgntCndctvty : 16|8@1+ (5,0) [0|1250] "microSiemens/mm" Vector__XXX
   SG_ Aftrtrtmnt2SCRCtlystRgntCncntrtn : 8|8@1+ (0.25,0) [0|62.5] "%" Vector__XXX
   SG_ Aftrtrtmnt2SCRCtlystRagentTemp2 : 0|8@1+ (1,-40) [-40|210] "deg C" Vector__XXX

BO_ 2566732030 A2SCREGT: 8 Vector__XXX
   SG_ Aftrtrtmnt2SCRCtlystOtltGsTmpPrl : 40|5@1+ (1,0) [0|31] "" Vector__XXX
   SG_ Aftrtrtmnt2SCRCtlystOtltGasTemp : 24|16@1+ (0.03125,-273) [-273|1734.97] "deg C" Vector__XXX
   SG_ Aftrtrtmnt2SCRCtlystIntkGsTmpPrl : 16|5@1+ (1,0) [0|31] "" Vector__XXX
   SG_ Aftrtrtmnt2SCRCtlystIntkGasTemp : 0|16@1+ (0.03125,-273) [-273|1734.97] "deg C" Vector__XXX

BO_ 2566732286 A2SCREGP: 8 Vector__XXX
   SG_ Aftrtrtmnt2SCRCtlystExhstGsDffPr : 16|5@1+ (1,0) [0|31] "" Vector__XXX
   SG_ Aftrtrtmnt2SCRCtlystExhstGs_0000 : 0|16@1+ (0.1,0) [0|6425.5] "kPa" Vector__XXX

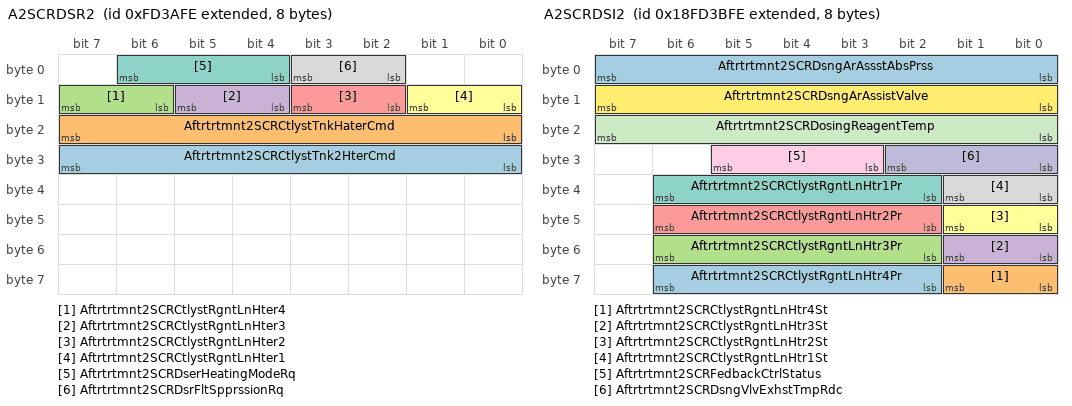
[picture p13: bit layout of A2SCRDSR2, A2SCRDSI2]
BO_ 2164079358 A2SCRDSR2: 8 Vector__XXX
   SG_ Aftrtrtmnt2SCRCtlystTnk2HterCmd : 24|8@1+ (0.4,0) [0|100] "%" Vector__XXX
   SG_ Aftrtrtmnt2SCRCtlystTnkHaterCmd : 16|8@1+ (0.4,0) [0|100] "%" Vector__XXX
   SG_ Aftrtrtmnt2SCRCtlystRgntLnHter4 : 14|2@1+ (1,0) [0|3] "" Vector__XXX
   SG_ Aftrtrtmnt2SCRCtlystRgntLnHter3 : 12|2@1+ (1,0) [0|3] "" Vector__XXX
   SG_ Aftrtrtmnt2SCRCtlystRgntLnHter2 : 10|2@1+ (1,0) [0|3] "" Vector__XXX
   SG_ Aftrtrtmnt2SCRCtlystRgntLnHter1 : 8|2@1+ (1,0) [0|3] "" Vector__XXX
   SG_ Aftrtrtmnt2SCRDserHeatingModeRq : 4|3@1+ (1,0) [0|7] "" Vector__XXX
   SG_ Aftrtrtmnt2SCRDsrFltSpprssionRq : 2|2@1+ (1,0) [0|3] "" Vector__XXX

BO_ 2364549118 A2SCRDSR1: 8 Vector__XXX
   SG_ Aftrtrtmnt2SCRRqdRgntQnttyFrIntg : 24|16@1+ (0.1,0) [0|6425.5] "g" Vector__XXX
   SG_ Aftrtratment2SCRSystemRqedState : 16|4@1+ (1,0) [0|15] "" Vector__XXX
   SG_ Aftrtrtmnt2SCRRqdDsngRgntQntity : 0|16@1+ (0.3,0) [0|19276.5] "g/h" Vector__XXX

BO_ 2566732798 A2SCRDSI2: 8 Vector__XXX
   SG_ Aftrtrtmnt2SCRCtlystRgntLnHtr4Pr : 58|5@1+ (1,0) [0|31] "" Vector__XXX
   SG_ Aftrtrtmnt2SCRCtlystRgntLnHtr4St : 56|2@1+ (1,0) [0|3] "" Vector__XXX
   SG_ Aftrtrtmnt2SCRCtlystRgntLnHtr3Pr : 50|5@1+ (1,0) [0|31] "" Vector__XXX
   SG_ Aftrtrtmnt2SCRCtlystRgntLnHtr3St : 48|2@1+ (1,0) [0|3] "" Vector__XXX
   SG_ Aftrtrtmnt2SCRCtlystRgntLnHtr2Pr : 42|5@1+ (1,0) [0|31] "" Vector__XXX
   SG_ Aftrtrtmnt2SCRCtlystRgntLnHtr2St : 40|2@1+ (1,0) [0|3] "" Vector__XXX
   SG_ Aftrtrtmnt2SCRCtlystRgntLnHtr1Pr : 34|5@1+ (1,0) [0|31] "" Vector__XXX
   SG_ Aftrtrtmnt2SCRCtlystRgntLnHtr1St : 32|2@1+ (1,0) [0|3] "" Vector__XXX
   SG_ Aftrtrtmnt2SCRFedbackCtrlStatus : 27|3@1+ (1,0) [0|7] "" Vector__XXX
   SG_ Aftrtrtmnt2SCRDsngVlvExhstTmpRdc : 24|3@1+ (1,0) [0|7] "" Vector__XXX
   SG_ Aftrtrtmnt2SCRDosingReagentTemp : 16|8@1+ (1,-40) [-40|210] "deg C" Vector__XXX
   SG_ Aftrtrtmnt2SCRDsngArAssistValve : 8|8@1+ (0.4,0) [0|100] "%" Vector__XXX
   SG_ Aftrtrtmnt2SCRDsngArAssstAbsPrss : 0|8@1+ (8,0) [0|2000] "kPa" Vector__XXX

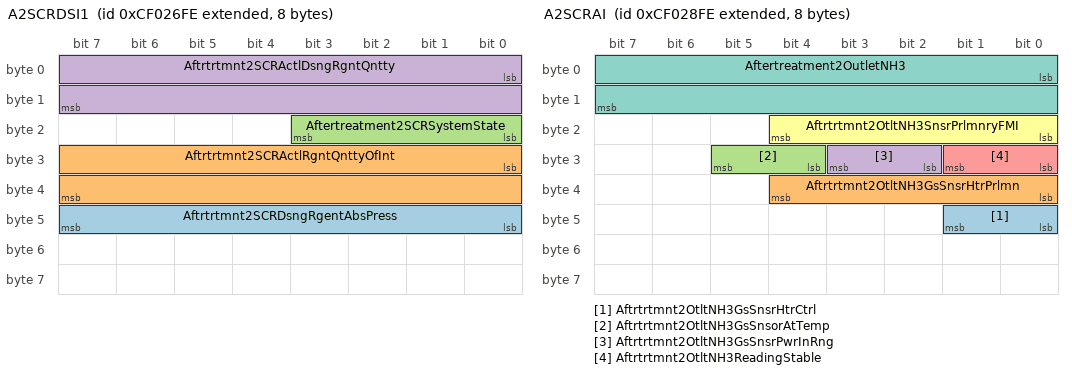
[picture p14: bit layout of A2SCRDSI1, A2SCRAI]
BO_ 2364548862 A2SCRDSI1: 8 Vector__XXX
   SG_ Aftrtrtmnt2SCRDsngRgentAbsPress : 40|8@1+ (8,0) [0|2000] "kPa" Vector__XXX
   SG_ Aftrtrtmnt2SCRActlRgntQnttyOfInt : 24|16@1+ (0.1,0) [0|6425.5] "g" Vector__XXX
   SG_ Aftertreatment2SCRSystemState : 16|4@1+ (1,0) [0|15] "" Vector__XXX
   SG_ Aftrtrtmnt2SCRActlDsngRgntQntty : 0|16@1+ (0.3,0) [0|19276.5] "g/h" Vector__XXX

BO_ 2364549374 A2SCRAI: 8 Vector__XXX
   SG_ Aftrtrtmnt2OtltNH3GsSnsrHtrCtrl : 40|2@1+ (1,0) [0|3] "" Vector__XXX
   SG_ Aftrtrtmnt2OtltNH3GsSnsrHtrPrlmn : 32|5@1+ (1,0) [0|31] "" Vector__XXX
   SG_ Aftrtrtmnt2OtltNH3GsSnsorAtTemp : 28|2@1+ (1,0) [0|3] "" Vector__XXX
   SG_ Aftrtrtmnt2OtltNH3GsSnsrPwrInRng : 26|2@1+ (1,0) [0|3] "" Vector__XXX
   SG_ Aftrtrtmnt2OtltNH3ReadingStable : 24|2@1+ (1,0) [0|3] "" Vector__XXX
   SG_ Aftrtrtmnt2OtltNH3SnsrPrlmnryFMI : 16|5@1+ (1,0) [0|31] "" Vector__XXX
   SG_ Aftertreatment2OutletNH3 : 0|16@1+ (0.3,0) [0|19276.5] "g/h" Vector__XXX

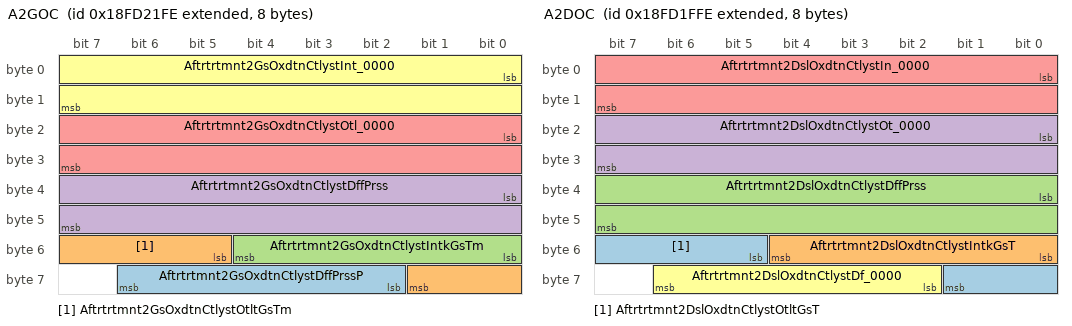
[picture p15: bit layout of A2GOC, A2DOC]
BO_ 2566726142 A2GOC: 8 Vector__XXX
   SG_ Aftrtrtmnt2GsOxdtnCtlystDffPrssP : 58|5@1+ (1,0) [0|31] "" Vector__XXX
   SG_ Aftrtrtmnt2GsOxdtnCtlystOtltGsTm : 53|5@1+ (1,0) [0|31] "" Vector__XXX
   SG_ Aftrtrtmnt2GsOxdtnCtlystIntkGsTm : 48|5@1+ (1,0) [0|31] "" Vector__XXX
   SG_ Aftrtrtmnt2GsOxdtnCtlystDffPrss : 32|16@1+ (0.1,0) [0|6425.5] "kPa" Vector__XXX
   SG_ Aftrtrtmnt2GsOxdtnCtlystOtl_0000 : 16|16@1+ (0.03125,-273) [-273|1734.97] "deg C" Vector__XXX
   SG_ Aftrtrtmnt2GsOxdtnCtlystInt_0000 : 0|16@1+ (0.03125,-273) [-273|1734.97] "deg C" Vector__XXX

BO_ 2566725630 A2DOC: 8 Vector__XXX
   SG_ Aftrtrtmnt2DslOxdtnCtlystOtltGsT : 53|5@1+ (1,0) [0|31] "" Vector__XXX
   SG_ Aftrtrtmnt2DslOxdtnCtlystIntkGsT : 48|5@1+ (1,0) [0|31] "" Vector__XXX
   SG_ Aftrtrtmnt2DslOxdtnCtlystDffPrss : 32|16@1+ (0.5,0) [0|32127.5] "kPa" Vector__XXX
   SG_ Aftrtrtmnt2DslOxdtnCtlystOt_0000 : 16|16@1+ (0.03125,-273) [-273|1734.97] "deg C" Vector__XXX
   SG_ Aftrtrtmnt2DslOxdtnCtlystIn_0000 : 0|16@1+ (0.03125,-273) [-273|1734.97] "deg C" Vector__XXX
   SG_ Aftrtrtmnt2DslOxdtnCtlystDf_0000 : 58|5@1+ (1,0) [0|31] "" Vector__XXX

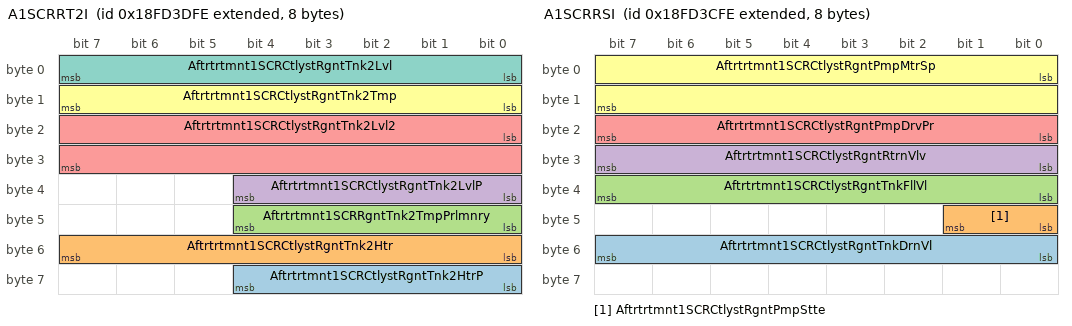
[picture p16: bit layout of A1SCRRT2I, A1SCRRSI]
BO_ 2566733310 A1SCRRT2I: 8 Vector__XXX
   SG_ Aftrtrtmnt1SCRCtlystRgntTnk2HtrP : 56|5@1+ (1,0) [0|31] "" Vector__XXX
   SG_ Aftrtrtmnt1SCRCtlystRgntTnk2Htr : 48|8@1+ (0.4,0) [0|100] "%" Vector__XXX
   SG_ Aftrtrtmnt1SCRRgntTnk2TmpPrlmnry : 40|5@1+ (1,0) [0|31] "" Vector__XXX
   SG_ Aftrtrtmnt1SCRCtlystRgntTnk2LvlP : 32|5@1+ (1,0) [0|31] "" Vector__XXX
   SG_ Aftrtrtmnt1SCRCtlystRgntTnk2Lvl2 : 16|16@1+ (0.1,0) [0|6425.5] "mm" Vector__XXX
   SG_ Aftrtrtmnt1SCRCtlystRgntTnk2Tmp : 8|8@1+ (1,-40) [-40|210] "deg C" Vector__XXX
   SG_ Aftrtrtmnt1SCRCtlystRgntTnk2Lvl : 0|8@1+ (0.4,0) [0|100] "%" Vector__XXX

BO_ 2566733054 A1SCRRSI: 8 Vector__XXX
   SG_ Aftrtrtmnt1SCRCtlystRgntTnkDrnVl : 48|8@1+ (0.4,0) [0|100] "%" Vector__XXX
   SG_ Aftrtrtmnt1SCRCtlystRgntPmpStte : 40|2@1+ (1,0) [0|3] "" Vector__XXX
   SG_ Aftrtrtmnt1SCRCtlystRgntTnkFllVl : 32|8@1+ (0.4,0) [0|100] "%" Vector__XXX
   SG_ Aftrtrtmnt1SCRCtlystRgntRtrnVlv : 24|8@1+ (0.4,0) [0|100] "%" Vector__XXX
   SG_ Aftrtrtmnt1SCRCtlystRgntPmpDrvPr : 16|8@1+ (0.4,0) [0|100] "%" Vector__XXX
   SG_ Aftrtrtmnt1SCRCtlystRgntPmpMtrSp : 0|16@1+ (0.5,0) [0|32127.5] "rpm" Vector__XXX

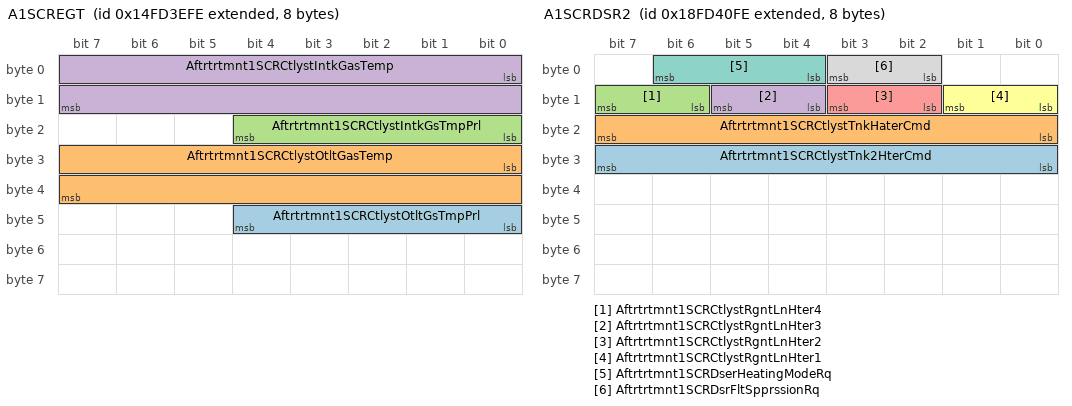
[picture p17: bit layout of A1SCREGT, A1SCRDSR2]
BO_ 2499624702 A1SCREGT: 8 Vector__XXX
   SG_ Aftrtrtmnt1SCRCtlystOtltGsTmpPrl : 40|5@1+ (1,0) [0|31] "" Vector__XXX
   SG_ Aftrtrtmnt1SCRCtlystOtltGasTemp : 24|16@1+ (0.03125,-273) [-273|1734.97] "deg C" Vector__XXX
   SG_ Aftrtrtmnt1SCRCtlystIntkGsTmpPrl : 16|5@1+ (1,0) [0|31] "" Vector__XXX
   SG_ Aftrtrtmnt1SCRCtlystIntkGasTemp : 0|16@1+ (0.03125,-273) [-273|1734.97] "deg C" Vector__XXX

BO_ 2566733822 A1SCREGP: 8 Vector__XXX
   SG_ Aftrtrtmnt1SCRCtlystExhstGsDffPr : 16|5@1+ (1,0) [0|31] "" Vector__XXX
   SG_ Aftrtrtmnt1SCRCtlystExhstGs_0000 : 0|16@1+ (0.1,0) [0|6425.5] "kPa" Vector__XXX

BO_ 2566734078 A1SCRDSR2: 8 Vector__XXX
   SG_ Aftrtrtmnt1SCRCtlystTnk2HterCmd : 24|8@1+ (0.4,0) [0|100] "%" Vector__XXX
   SG_ Aftrtrtmnt1SCRCtlystTnkHaterCmd : 16|8@1+ (0.4,0) [0|100] "%" Vector__XXX
   SG_ Aftrtrtmnt1SCRCtlystRgntLnHter4 : 14|2@1+ (1,0) [0|3] "" Vector__XXX
   SG_ Aftrtrtmnt1SCRCtlystRgntLnHter3 : 12|2@1+ (1,0) [0|3] "" Vector__XXX
   SG_ Aftrtrtmnt1SCRCtlystRgntLnHter2 : 10|2@1+ (1,0) [0|3] "" Vector__XXX
   SG_ Aftrtrtmnt1SCRCtlystRgntLnHter1 : 8|2@1+ (1,0) [0|3] "" Vector__XXX
   SG_ Aftrtrtmnt1SCRDserHeatingModeRq : 4|3@1+ (1,0) [0|7] "" Vector__XXX
   SG_ Aftrtrtmnt1SCRDsrFltSpprssionRq : 2|2@1+ (1,0) [0|3] "" Vector__XXX

BO_ 2364548350 A1SCRDSR1: 8 Vector__XXX
   SG_ Aftrtrtmnt1SCRRqdRgntQnttyFrIntg : 24|16@1+ (0.1,0) [0|6425.5] "g" Vector__XXX
   SG_ Aftrtratment1SCRSystemRqedState : 16|4@1+ (1,0) [0|15] "" Vector__XXX
   SG_ Aftrtrtmnt1SCRRqdDsngRgntQntity : 0|16@1+ (0.3,0) [0|19276.5] "g/h" Vector__XXX

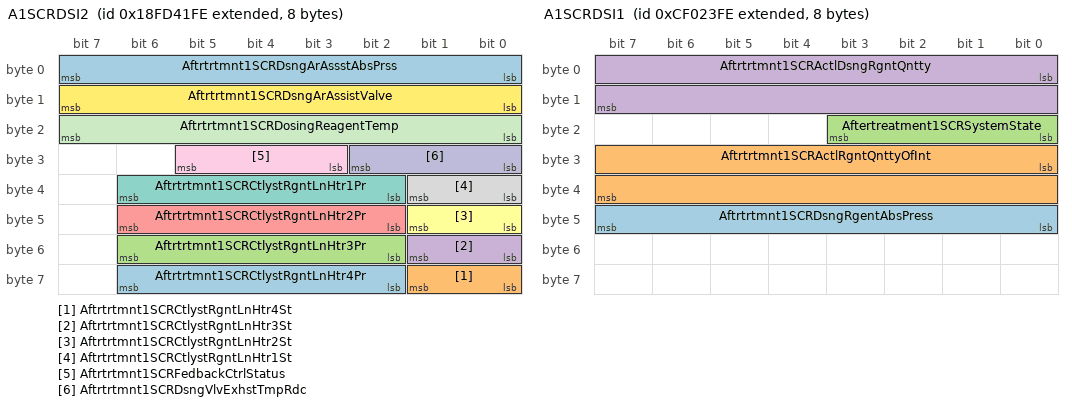
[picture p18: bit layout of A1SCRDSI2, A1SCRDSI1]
BO_ 2566734334 A1SCRDSI2: 8 Vector__XXX
   SG_ Aftrtrtmnt1SCRCtlystRgntLnHtr4Pr : 58|5@1+ (1,0) [0|31] "" Vector__XXX
   SG_ Aftrtrtmnt1SCRCtlystRgntLnHtr4St : 56|2@1+ (1,0) [0|3] "" Vector__XXX
   SG_ Aftrtrtmnt1SCRCtlystRgntLnHtr3Pr : 50|5@1+ (1,0) [0|31] "" Vector__XXX
   SG_ Aftrtrtmnt1SCRCtlystRgntLnHtr3St : 48|2@1+ (1,0) [0|3] "" Vector__XXX
   SG_ Aftrtrtmnt1SCRCtlystRgntLnHtr2Pr : 42|5@1+ (1,0) [0|31] "" Vector__XXX
   SG_ Aftrtrtmnt1SCRCtlystRgntLnHtr2St : 40|2@1+ (1,0) [0|3] "" Vector__XXX
   SG_ Aftrtrtmnt1SCRCtlystRgntLnHtr1Pr : 34|5@1+ (1,0) [0|31] "" Vector__XXX
   SG_ Aftrtrtmnt1SCRCtlystRgntLnHtr1St : 32|2@1+ (1,0) [0|3] "" Vector__XXX
   SG_ Aftrtrtmnt1SCRFedbackCtrlStatus : 27|3@1+ (1,0) [0|7] "" Vector__XXX
   SG_ Aftrtrtmnt1SCRDsngVlvExhstTmpRdc : 24|3@1+ (1,0) [0|7] "" Vector__XXX
   SG_ Aftrtrtmnt1SCRDosingReagentTemp : 16|8@1+ (1,-40) [-40|210] "deg C" Vector__XXX
   SG_ Aftrtrtmnt1SCRDsngArAssistValve : 8|8@1+ (0.4,0) [0|100] "%" Vector__XXX
   SG_ Aftrtrtmnt1SCRDsngArAssstAbsPrss : 0|8@1+ (8,0) [0|2000] "kPa" Vector__XXX

BO_ 2364548094 A1SCRDSI1: 8 Vector__XXX
   SG_ Aftrtrtmnt1SCRDsngRgentAbsPress : 40|8@1+ (8,0) [0|2000] "kPa" Vector__XXX
   SG_ Aftrtrtmnt1SCRActlRgntQnttyOfInt : 24|16@1+ (0.1,0) [0|6425.5] "g" Vector__XXX
   SG_ Aftertreatment1SCRSystemState : 16|4@1+ (1,0) [0|15] "" Vector__XXX
   SG_ Aftrtrtmnt1SCRActlDsngRgntQntty : 0|16@1+ (0.3,0) [0|19276.5] "g/h" Vector__XXX

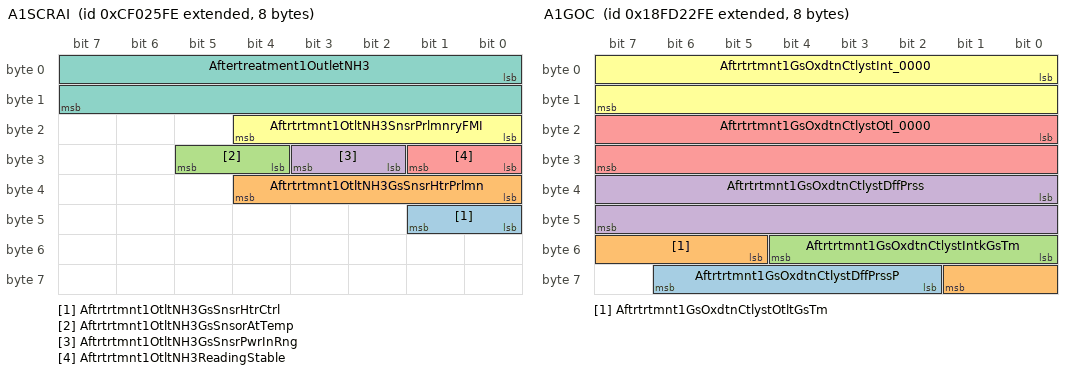
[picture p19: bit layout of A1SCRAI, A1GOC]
BO_ 2364548606 A1SCRAI: 8 Vector__XXX
   SG_ Aftrtrtmnt1OtltNH3GsSnsrHtrCtrl : 40|2@1+ (1,0) [0|3] "" Vector__XXX
   SG_ Aftrtrtmnt1OtltNH3GsSnsrHtrPrlmn : 32|5@1+ (1,0) [0|31] "" Vector__XXX
   SG_ Aftrtrtmnt1OtltNH3GsSnsorAtTemp : 28|2@1+ (1,0) [0|3] "" Vector__XXX
   SG_ Aftrtrtmnt1OtltNH3GsSnsrPwrInRng : 26|2@1+ (1,0) [0|3] "" Vector__XXX
   SG_ Aftrtrtmnt1OtltNH3ReadingStable : 24|2@1+ (1,0) [0|3] "" Vector__XXX
   SG_ Aftrtrtmnt1OtltNH3SnsrPrlmnryFMI : 16|5@1+ (1,0) [0|31] "" Vector__XXX
   SG_ Aftertreatment1OutletNH3 : 0|16@1+ (0.3,0) [0|19276.5] "g/h" Vector__XXX

BO_ 2566726398 A1GOC: 8 Vector__XXX
   SG_ Aftrtrtmnt1GsOxdtnCtlystDffPrssP : 58|5@1+ (1,0) [0|31] "" Vector__XXX
   SG_ Aftrtrtmnt1GsOxdtnCtlystOtltGsTm : 53|5@1+ (1,0) [0|31] "" Vector__XXX
   SG_ Aftrtrtmnt1GsOxdtnCtlystIntkGsTm : 48|5@1+ (1,0) [0|31] "" Vector__XXX
   SG_ Aftrtrtmnt1GsOxdtnCtlystDffPrss : 32|16@1+ (0.1,0) [0|6425.5] "kPa" Vector__XXX
   SG_ Aftrtrtmnt1GsOxdtnCtlystOtl_0000 : 16|16@1+ (0.03125,-273) [-273|1734.97] "deg C" Vector__XXX
   SG_ Aftrtrtmnt1GsOxdtnCtlystInt_0000 : 0|16@1+ (0.03125,-273) [-273|1734.97] "deg C" Vector__XXX

CM_ BO_ 2565865982 "Electronic Brake Controller 1";
CM_ SG_ 2565865982 EngAuxShutdownSwitch "Switch signal which requests that all engine fueling stop.";
CM_ SG_ 2565865982 SrcAddrssOfCtrllngDvcFrBrkCntrl "The source address of the SAE J1939 device currently controlling the brake system.";
CM_ SG_ 2565865982 BrakePedalPos "Ratio of brake pedal position to maximum pedal position.";
CM_ SG_ 2565865982 TrctrMntdTrilerABSWarningSignal "This parameter commands the tractor-mounted trailer ABS optical warning signal.";
CM_ SG_ 2565865982 TrailerABSStatus "State signal which indicates that ABS in the trailer is actively controlling the brakes.";
CM_ SG_ 2565865982 HaltBrakeSwitch "Switch signal which indicates the position of the halt brake switch.";
CM_ SG_ 2565865982 ATC_ASRInformationSignal "This parameter commands the ATC/ASR driver information signal, for example a dash lamp.";
CM_ SG_ 2565865982 ABS_EBSAmberWarningSignal "This parameter commands the ABS/EBS amber/yellow optical warning signal";
CM_ SG_ 2565865982 EBSRedWarningSignal "This parameter commands the EBS red optical warning signal";
CM_ SG_ 2565865982 ABSFullyOperational "Signal which indicates whether an ABS system is fully operational or whether its functionality is reduced by a defect or by";
CM_ SG_ 2565865982 EngRetarderSelection "The position of the operator controlled selector, expressed as a percentage and determined by the ratio of the current";
CM_ SG_ 2565865982 RemoteAccelEnableSwitch "Switch signal which indicates that the remote accelerator has been enabled and controls the engine.";
CM_ SG_ 2565865982 EngDerateSwitch "Switch signal used to activate the torque limiting feature of the engine.";
CM_ SG_ 2565865982 AccelInterlockSwitch "Switch signal used to disable the accelerator and remote accelerator inputs, causing the engine to return to idle.";
CM_ SG_ 2565865982 TractionCtrlOverrideSwitch "Switch signal which indicates the position of the traction control override switch.";
CM_ SG_ 2565865982 ASRHillHolderSwitch "Switch signal which indicates the position of the ASR [hill holder] switch.";
CM_ SG_ 2565865982 ASROffroadSwitch "Switch signal which indicates the position of the ASR off-road switch.";
CM_ SG_ 2565865982 ABSOffroadSwitch "Switch signal which indicates the position of the ABS off-road switch.";
CM_ SG_ 2565865982 EBSBrakeSwitch "Switch signal which indicates that the brake pedal is being pressed.";
CM_ SG_ 2565865982 AntiLockBrakingActive "State signal which indicates that the ABS is active.";
CM_ SG_ 2565865982 ASRBrakeCtrlActive "State signal which indicates that ASR brake control is active.";
CM_ SG_ 2565865982 ASREngCtrlActive "State signal which indicates that ASR engine control has been commanded to be active.";
CM_ BO_ 2565867262 "Electronic Axle Controller 1";
CM_ SG_ 2565867262 RearAxleGroupEngagementStatus "Rear axle group engagement status";
CM_ SG_ 2565867262 FrontAxleGroupEngagementStatus "Front axle group engagement status";
CM_ SG_ 2565867262 DiffLockStateCentralRear "State used which indicates the condition of the central rear differential lock.";
CM_ SG_ 2565867262 DiffLockStateCentralFront "State used which indicates the condition of the central front differential lock.";
CM_ SG_ 2565867262 DiffLockStateCentral "State used which indicates the condition of the central differential lock.";
CM_ SG_ 2565867262 DiffLockStateRearAxle2 "State used which indicates the condition of the rear axle 2 differential lock.";
CM_ SG_ 2565867262 DiffLockStateRearAxle1 "State used which indicates the condition of the rear axle 1 differential lock.";
CM_ SG_ 2565867262 DiffLockStateFrontAxle2 "State used which indicates the condition of the front axle 2 differential lock.";
CM_ SG_ 2565867262 DiffLockStateFrontAxle1 "State used which indicates the condition of the front axle 1 differential lock.";
CM_ SG_ 2565867262 Location "To identify to which of several similar devices (such as tires or fuel tanks) the information applies.";
CM_ BO_ 2566821118 "Engine Auxiliary Coolant";
CM_ SG_ 2566821118 SeaWaterPumpOutletPress "Gauge pressure of liquid found at outlet of sea water pump in sea water cooling system.";
CM_ SG_ 2566821118 EngAuxCoolantTemp "Temperature of coolant found in the intercooler which is located after the turbocharger.";
CM_ SG_ 2566821118 EngAuxCoolantPress "Gage pressure of coolant found in the intercooler which is located after the turbocharger.";
CM_ BO_ 2566810622 "Driver's Identification";
CM_ BO_ 2566847742 "Dash Display";
CM_ SG_ 2566847742 FuelLevel2 "Ratio of volume of fuel to the total volume of fuel in the second or right-side storage container.";
CM_ SG_ 2566847742 FuelLevel1 "Ratio of volume of fuel to the total volume of fuel storage container.";
CM_ SG_ 2566847742 CargoAmbientTemp "Temperature of air inside vehicle container used to accommodate cargo.";
CM_ SG_ 2566847742 EngOilFilterDiffPress "Change in engine oil pressure, measured across the filter, due to the filter and any accumulation of solid or semisolid";
CM_ SG_ 2566847742 EngFuelFilterDiffPress "Differential pressure measured across the fuel filter located between the fuel tank and the supply pump.";
CM_ SG_ 2566847742 WasherFluidLevel "Ratio of volume of liquid to total container volume of fluid reservoir in windshield wash system.";
CM_ BO_ 2566768382 "Cold Start Aids";
CM_ SG_ 2566768382 EngStartEnableDevice2Config "The start enable device installed for start enable device 2.";
CM_ SG_ 2566768382 EngStartEnableDevice1Config "The start enable device installed for start enable device 1.";
CM_ SG_ 2566768382 EngStartEnableDevice2 "Devices that assist an engine in starting, e.";
CM_ SG_ 2566768382 EngStartEnableDevice1 "Devices that assist an Engine in starting, e.";
CM_ BO_ 2566811902 "Combination Vehicle Weight";
CM_ SG_ 2566811902 PoweredVehicleWeight "Total mass imposed by the tires of the powered vehicle on the road surface.";
CM_ SG_ 2566811902 GrossCombinationVehicleWeight "The total weight of the truck and all attached trailers.";
CM_ BO_ 2563768062 "Continuous Torque & Speed Limit Request";
CM_ SG_ 2563768062 MxCntnuousRetarderTorqueLimitRq "Requested maximum continuous retarder torque (operating range: -125 to 0%)";
CM_ SG_ 2563768062 MnCntnuousRetarderTorqueLimitRq "Requested minimum continuous retarder torque (operating range: -125 to 0%)";
CM_ SG_ 2563768062 MxCntinuousRetarderSpeedLimitRq "Requested maximum continuous retarder speed";
CM_ SG_ 2563768062 MnCntinuousRetarderSpeedLimitRq "Requested minimum continuous retarder speed";
CM_ SG_ 2563768062 EngTorqueLimitRqMaxContinuous "Requested maximum continuous engine torque (operating range: 0 to 125%)";
CM_ SG_ 2563768062 EngTorqueLimitRqMinContinuous "Requested minimum continuous engine torque (operating range: 0 to 125%)";
CM_ SG_ 2563768062 EngSpeedLimitRqMaxContinuous "Requested maximum continuous engine speed";
CM_ SG_ 2563768062 EngSpeedLimitRqMinContinuous "Requested minimum continuous engine speed";
CM_ BO_ 2633924862 "Combustion Time 6";
CM_ SG_ 2633924862 EngAverageCombustionTime "The average combustion time of all cylinders of an engine.";
CM_ SG_ 2633924862 EngDesiredCombustionTime "The desired combustion time based upon engine load and speed lookup maps.";
CM_ BO_ 2633924606 "Combustion Time 5";
CM_ SG_ 2633924606 EngCyl20CombustionTime "The amount of time from when the ignition of the fuel is initiated to when the fuel is completely ignited (i.";
CM_ SG_ 2633924606 EngCyl19CombustionTime "The amount of time from when the ignition of the fuel is initiated to when the fuel is completely ignited (i.";
CM_ SG_ 2633924606 EngCyl18CombustionTime "The amount of time from when the ignition of the fuel is initiated to when the fuel is completely ignited (i.";
CM_ SG_ 2633924606 EngCyl17CombustionTime "The amount of time from when the ignition of the fuel is initiated to when the fuel is completely ignited (i.";
CM_ BO_ 2633924350 "Combustion Time 4";
CM_ SG_ 2633924350 EngCyl16CombustionTime "The amount of time from when the ignition of the fuel is initiated to when the fuel is completely ignited (i.";
CM_ SG_ 2633924350 EngCyl15CombustionTime "The amount of time from when the ignition of the fuel is initiated to when the fuel is completely ignited (i.";
CM_ SG_ 2633924350 EngCyl14CombustionTime "The amount of time from when the ignition of the fuel is initiated to when the fuel is completely ignited (i.";
CM_ SG_ 2633924350 EngCyl13CombustionTime "The amount of time from when the ignition of the fuel is initiated to when the fuel is completely ignited (i.";
CM_ BO_ 2633924094 "Combustion Time 3";
CM_ SG_ 2633924094 EngCyl12CombustionTime "The amount of time from when the ignition of the fuel is initiated to when the fuel is completely ignited (i.";
CM_ SG_ 2633924094 EngCyl11CombustionTime "The amount of time from when the ignition of the fuel is initiated to when the fuel is completely ignited (i.";
CM_ SG_ 2633924094 EngCyl10CombustionTime "The amount of time from when the ignition of the fuel is initiated to when the fuel is completely ignited (i.";
CM_ SG_ 2633924094 EngCyl9CombustionTime "The amount of time from when the ignition of the fuel is initiated to when the fuel is completely ignited (i.";
CM_ BO_ 2633923838 "Combustion Time 2";
CM_ SG_ 2633923838 EngCyl8CombustionTime "The amount of time from when the ignition of the fuel is initiated to when the fuel is completely ignited (i.";
CM_ SG_ 2633923838 EngCyl7CombustionTime "The amount of time from when the ignition of the fuel is initiated to when the fuel is completely ignited (i.";
CM_ SG_ 2633923838 EngCyl6CombustionTime "The amount of time from when the ignition of the fuel is initiated to when the fuel is completely ignited (i.";
CM_ SG_ 2633923838 EngCyl5CombustionTime "The amount of time from when the ignition of the fuel is initiated to when the fuel is completely ignited (i.";
CM_ BO_ 2633923582 "Combustion Time 1";
CM_ SG_ 2633923582 EngCyl4CombustionTime "The amount of time from when the ignition of the fuel is initiated to when the fuel is completely ignited (i.";
CM_ SG_ 2633923582 EngCyl3CombustionTime "The amount of time from when the ignition of the fuel is initiated to when the fuel is completely ignited (i.";
CM_ SG_ 2633923582 EngCyl2CombustionTime "The amount of time from when the ignition of the fuel is initiated to when the fuel is completely ignited (i.";
CM_ SG_ 2633923582 EngCyl1CombustionTime "The amount of time from when the ignition of the fuel is initiated to when the fuel is completely ignited (i.";
CM_ BO_ 2633878014 "Electronic Control Module Information";
CM_ SG_ 2633878014 TotalCountOfConfigChangesMade "Total number of times changes have been made to any of the configurable parameters.";
CM_ BO_ 2566771966 "Cab Message 3";
CM_ SG_ 2566771966 TransOilLevelRq "Conveys operator or vehicle system desire for a transmission oil level reading to be taken.";
CM_ SG_ 2566771966 FifthWheelReleaseCtrl "Operator input used to release the fifth wheel.";
CM_ SG_ 2566771966 FfthWhlRlaseCtrlSecurityLockout "Operator's fifth wheel release control interlock.";
CM_ SG_ 2566771966 TransferCaseSelectorSwitch "Operator switch to select the condition of the transfer case.";
CM_ BO_ 2564882174 "Cab Message 1";
CM_ SG_ 2564882174 DslPrtcltFltrRgnrtonForceSwitch "Indicates the state of a switch available to the operator that forces diesel particulate filter regeneration.";
CM_ SG_ 2564882174 DslPrtcltFltrRgnrtnInhbitSwitch "Indicates the state of a switch available to the operator that inhibits diesel particulate filter regeneration.";
CM_ SG_ 2564882174 SelectedMaxVehicleSpeedLimit "User selected maximum vehicle speed.";
CM_ SG_ 2564882174 RqCabZoneHeating "Request to activate cab zone heating.";
CM_ SG_ 2564882174 RqEngZoneHeating "Request to activate engine zone heating.";
CM_ SG_ 2564882174 AuxHeaterModeRq "Request to activate the auxiliary heater.";
CM_ SG_ 2564882174 EngAutomaticStartEnableSwitch "Switch signal which enables the idle management system to be enabled.";
CM_ SG_ 2564882174 AtmaticGearShiftingEnableSwitch "Indicates that automated gear shifting is enabled via a switch";
CM_ SG_ 2564882174 VhclLmtngSpdGvernorEnableSwitch "Switch signal which enables the Vehicle Limiting Speed Governor (VLSG) such that the vehicle speed may be either";
CM_ SG_ 2564882174 VhclLmtngSpdGvrnrIncrmentSwitch "Switch signal which increases the Vehicle Limiting Speed Governor (VLSG).";
CM_ SG_ 2564882174 VhclLmtngSpdGvrnrDcrementSwitch "Switch signal which decreases the Vehicle Limiting Speed Governor (VLSG).";
CM_ SG_ 2564882174 SeatBeltSwitch "State of switch used to determine if Seat Belt is buckled";
CM_ SG_ 2564882174 OperatorSeatDirectionSwitch "Senses whether the operator seat is in the forward driving position";
CM_ SG_ 2564882174 BatteryMainSwitchHoldRq "Request to hold the battery main switch.";
CM_ SG_ 2564882174 AuxHeaterCoolantPumpRq "Indicates whether to activate the auxiliary heater coolant water pump.";
CM_ SG_ 2564882174 CabInteriorTempCmd "Parameter used to command a certain cab interior temperature.";
CM_ SG_ 2564882174 RqedPercentFanSpeed "Fan speed as a ratio of the actual fan drive (current speed) to the fully engaged fan drive (maximum fan speed).";
CM_ BO_ 2563833598 "Cab Illumination Message";
CM_ SG_ 2563833598 IlluminationBrightnessPercent "Commanded backlight brightness level for all cab displays";
CM_ BO_ 2566843390 "Component Identification";
CM_ BO_ 2566844926 "Cruise Control/Vehicle Speed";
CM_ SG_ 2566844926 ParkBrakeReleaseInhibitRq "Park Brake Release Inhibit Request signals the desire that an applied park brake remain applied and limit the ability of the";
CM_ SG_ 2566844926 PTOGovernorState "This parameter is used to indicate the current state or mode of operation by the power takeoff (PTO) governor.";
CM_ SG_ 2566844926 EngShutdownOverrideSwitch "Switch signal which indicates the position of the engine shutdown override switch.";
CM_ SG_ 2566844926 EngTestModeSwitch "Switch signal which indicates the position of the engine test mode switch.";
CM_ SG_ 2566844926 EngIdleDecrementSwitch "Switch signal which indicates the position of the idle decrement switch.";
CM_ SG_ 2566844926 EngIdleIncrementSwitch "Switch signal which indicates the position of the idle increment switch.";
CM_ SG_ 2566844926 CruiseCtrlStates "This parameter is used to indicate the current state, or mode, of operation by the cruise control device.";
CM_ SG_ 2566844926 CruiseCtrlSetSpeed "Value of set (chosen) velocity of velocity control system.";
CM_ SG_ 2566844926 CruiseCtrlAccelerateSwitch "Switch signal of the cruise control activator which indicates that the activator is in the position [accelerate.";
CM_ SG_ 2566844926 CruiseCtrlResumeSwitch "Switch signal of the cruise control activator which indicates that the activator is in the position [resume.";
CM_ SG_ 2566844926 CruiseCtrlCoastSwitch "Switch signal of the cruise control activator which indicates that the activator is in the position [coast (decelerate).";
CM_ SG_ 2566844926 CruiseCtrlSetSwitch "Switch signal of the cruise control activator which indicates that the activator is in the position [set.";
CM_ SG_ 2566844926 ClutchSwitch "Switch signal which indicates that the clutch pedal is being pressed.";
CM_ SG_ 2566844926 BrakeSwitch "Switch signal which indicates that the driver operated brake foot pedal is being pressed.";
CM_ SG_ 2566844926 CruiseCtrlEnableSwitch "Switch signal which indicates that it is possible to manage the cruise control function.";
CM_ SG_ 2566844926 CruiseCtrlActive "Cruise control is switched on.";
CM_ SG_ 2566844926 WheelBasedVehicleSpeed "Speed of the vehicle as calculated from wheel or tailshaft speed.";
CM_ SG_ 2566844926 CruiseCtrlPauseSwitch "Switch signal which indicates the position of the Cruise Control Pause Switch used on Remote Cruise Control applications.";
CM_ SG_ 2566844926 ParkingBrakeSwitch "Switch signal which indicates when the parking brake is set.";
CM_ SG_ 2566844926 TwoSpeedAxleSwitch "Switch signal which indicates the current axle range.";
CM_ BO_ 2566843902 "Cruise Control/Vehicle Speed Setup";
CM_ SG_ 2566843902 CruiseCtrlLowSetLimitSpeed "Minimum vehicle velocity at which cruise can be set or minimum vehicle velocity for cruise operation before it will exit";
CM_ SG_ 2566843902 CruiseCtrlHighSetLimitSpeed "Maximum vehicle velocity at which cruise can be set.";
CM_ SG_ 2566843902 MaxVehicleSpeedLimit "Maximum vehicle velocity allowed.";
CM_ BO_ 2566809598 "Climate Control Configuration";
CM_ SG_ 2566809598 AuxHeaterMaxOutputPower "The maximum output power of the auxiliary heater.";
CM_ BO_ 2633940222 "Compression/Service Brake Information";
CM_ SG_ 2633940222 TripServiceBrakeApps "Total number of times the service brakes have been activated since the last trip reset.";
CM_ SG_ 2633940222 TripServiceBrakeDistance "Total distance over which the service brakes have been active since the last trip reset.";
CM_ SG_ 2633940222 TripCompressionBrakeDistance "Total distance over which the compression brakes have been active since the last trip reset.";
CM_ SG_ 2633940222 TotalCompressionBrakeDistance "Total distance over which the compression brakes have been active for the life of the engine.";
CM_ BO_ 2566775294 "Cab A/C Climate System Information";
CM_ SG_ 2566775294 CbA_CRfrgrntCmprssorOutletPress "This is the gage pressure at the compressor outlet in the cab air conditioning system.";
CM_ BO_ 2566803710 "Battery Temperature";
CM_ SG_ 2566803710 Battery2Temp "Temperature of the battery 2.";
CM_ SG_ 2566803710 Battery1Temp "Temperature of the battery 1.";
CM_ BO_ 2566719486 "Direct Lamp Control Command 1";
CM_ SG_ 2566719486 EngFuelFilterRestrictedLampCmd "Command signal directly controlling the Vehicle Fuel Filter Restricted Lamp.";
CM_ SG_ 2566719486 EngAirFilterRestrictionLampCmd "Command signal directly controlling the Engine Air Filter Restriction Lamp.";
CM_ SG_ 2566719486 EngIdleManagementActiveLampCmd "Command signal directly controlling the Engine Idle Management Active Lamp";
CM_ SG_ 2566719486 EngCoolantLevelLowLampCmd "Command signal directly controlling the Engine Coolant Level Low Lamp";
CM_ SG_ 2566719486 EngCoolantTempHighLampCmd "Command signal directly controlling the Engine Coolant Temperature High Lamp";
CM_ SG_ 2566719486 EngOilPressLowLampCmd "Command signal directly controlling the Engine Oil Pressure Low Lamp";
CM_ SG_ 2566719486 CmprssnBrkEnblSwtchIndctrLmpCmd "Command signal directly controlling Compression Brake Enable Switch Indicator Lamp.";
CM_ SG_ 2566719486 EngBrakeActiveLampCmd "Command signal directly controlling the Engine Brake Active Lamp";
CM_ SG_ 2566719486 OBDMalfunctionIndicatorLampCmd "Command signal directly controlling the OBD Malfunction Indicator Lamp";
CM_ SG_ 2566719486 EngRedStopLampCmd "Command signal directly controlling the Engine Red Stop Lamp";
CM_ SG_ 2566719486 EngAmberWarningLampCmd "Command signal directly controlling the Engine Amber Warning Lamp";
CM_ SG_ 2566719486 EngProtectLampCmd "Command signal directly controlling the Engine Protect Lamp";
CM_ BO_ 2633832702 "Collision Sensor Information";
CM_ SG_ 2633832702 RearCollisionSensor4Type "Type of Rear Collision Sensor 4.";
CM_ SG_ 2633832702 RearCollisionSensor3Type "Type of Rear Collision Sensor 3.";
CM_ SG_ 2633832702 RearCollisionSensor2Type "Type of Rear Collision Sensor 2.";
CM_ SG_ 2633832702 RearCollisionSensor1Type "Type of Rear Collision Sensor 1.";
CM_ SG_ 2633832702 SdeCollisionSensorRearRightType "Type of Side Collision Sensor Rear - Right.";
CM_ SG_ 2633832702 SdCllsionSensorMidRearRightType "Type of Side Collision Sensor Mid Rear - Right.";
CM_ SG_ 2633832702 SdCllsonSensorMidFrontRightType "Type of Side Collision Sensor Mid Front - Right.";
CM_ SG_ 2633832702 SdCollisionSensorFrontRightType "Type of Side Collision Sensor Front - Right.";
CM_ SG_ 2633832702 SideCollisionSensorRearLeftType "Type of Side Collision Sensor Rear - Left.";
CM_ SG_ 2633832702 SdCllisionSensorMidRearLeftType "Type of Side Collision Sensor Mid Rear - Left.";
CM_ SG_ 2633832702 SdCllsionSensorMidFrontLeftType "Type of Side Collision Sensor Mid Front - Left.";
CM_ SG_ 2633832702 SdeCollisionSensorFrontLeftType "Type of Side Collision Sensor Front - Left.";
CM_ SG_ 2633832702 FrontalCollisionSensor4Type "Type of Frontal Collision Sensor 4.";
CM_ SG_ 2633832702 FrontalCollisionSensor3Type "Type of Frontal Collision Sensor 3.";
CM_ SG_ 2633832702 FrontalCollisionSensor2Type "Type of Frontal Collision Sensor 2.";
CM_ SG_ 2633832702 FrontalCollisionSensor1Type "Type of Frontal Collision Sensor 1.";
CM_ BO_ 2163223550 "Crash Notification";
CM_ SG_ 2163223550 CrashChecksum "The Crash Checksum is used to verify the signal path from the airbag ECU to other devices in case of a crash.";
CM_ SG_ 2163223550 CrashCounter "The Crash Counter prevents other ECUs from reacting to a faulty transmission of the Crash Notification PGN and serves";
CM_ SG_ 2163223550 CrashType "Type of crash event.";
CM_ BO_ 2566714878 "Charge Air Cooler 2 Precooler";
CM_ SG_ 2566714878 EngChrgArClr2PrcoolerEfficiency "Engine charge air cooler 2 (CAC2) precooler efficiency is an indication of the precooler's ability to reduce the temperature";
CM_ SG_ 2566714878 EngChrgArClr2PrcoolerOutletTemp "Temperature of the combustion air measured at the charge air cooler 2 precooler outlet.";
CM_ SG_ 2566714878 EngChrgArClr2PrcoolerIntakeTemp "Temperature of the combustion air measured at the charge air cooler 2 precooler Intake.";
CM_ BO_ 2566714622 "Charge Air Cooler 2";
CM_ SG_ 2566714622 EngChargeAirCooler2Efficiency "Engine charge air cooler 2 (CAC2) is an indication of the CAC's ability to reduce the temperature of the combustion air";
CM_ SG_ 2566714622 EngChrgAirCooler2AmbientAirTemp "Temperature of the air surrounding charge air cooler 2.";
CM_ SG_ 2566714622 EngChargeAirCooler2OutletTemp "Temperature of combustion air after it exits from the Charge Air Cooler 2 but before any mixing of recirculated exhaust";
CM_ SG_ 2566714622 EngChargeAirCooler2IntakeTemp "Temperature of the combustion air measured at the charge air cooler 2 Intake.";
CM_ BO_ 2566715390 "Charge Air Cooler 1 Precooler";
CM_ SG_ 2566715390 EngChrgArClr1PrcoolerEfficiency "Engine charge air cooler 1 (CAC1) precooler efficiency is an indication of the precooler's ability to reduce the temperature";
CM_ SG_ 2566715390 EngChrgArClr1PrcoolerOutletTemp "Temperature of the combustion air measured at the charge air cooler 1 precooler outlet.";
CM_ SG_ 2566715390 EngChrgArClr1PrcoolerIntakeTemp "Temperature of the combustion air measured at the charge air cooler 1 precooler intake.";
CM_ BO_ 2566715134 "Charge Air Cooler 1";
CM_ SG_ 2566715134 EngChargeAirCooler1Efficiency "Engine charge air cooler 1(CAC1) efficiency is an indication of the CAC's ability to reduce the temperature of the";
CM_ SG_ 2566715134 EngChrgAirCooler1AmbientAirTemp "Temperature of the air surrounding charge air cooler 1.";
CM_ SG_ 2566715134 EngChargeAirCooler1IntakeTemp "Temperature of the combustion air measured at the CAC 1 Intake.";
CM_ BO_ 2365400830 "Basic Joystick Message 9";
CM_ SG_ 2365400830 Joystick9Button9PressedStatus "Reports when the joystick button has been pressed.";
CM_ SG_ 2365400830 Joystick9Button10PressedStatus "Reports when the joystick button has been pressed.";
CM_ SG_ 2365400830 Joystick9Button11PressedStatus "Reports when the joystick button has been pressed.";
CM_ SG_ 2365400830 Joystick9Button12PressedStatus "Reports when the joystick button has been pressed.";
CM_ SG_ 2365400830 Joystick9Button5PressedStatus "Reports when the joystick button has been pressed.";
CM_ SG_ 2365400830 Joystick9Button6PressedStatus "Reports when the joystick button has been pressed.";
CM_ SG_ 2365400830 Joystick9Button7PressedStatus "Reports when the joystick button has been pressed.";
CM_ SG_ 2365400830 Joystick9Button8PressedStatus "Reports when the joystick button has been pressed.";
CM_ SG_ 2365400830 Joystick9Button1PressedStatus "Reports when the joystick button has been pressed.";
CM_ SG_ 2365400830 Joystick9Button2PressedStatus "Reports when the joystick button has been pressed.";
CM_ SG_ 2365400830 Joystick9Button3PressedStatus "Reports when the joystick button has been pressed.";
CM_ SG_ 2365400830 Joystick9Button4PressedStatus "Reports when the joystick button has been pressed.";
CM_ SG_ 2365400830 Joystick9XAxisDetentPosStatus "Reports when the current joystick position is in the detent position for that axis of travel.";
CM_ SG_ 2365400830 Joystick9YAxisDetentPosStatus "Reports when the current joystick position is in the detent position for that axis of travel.";
CM_ SG_ 2365400830 Joystick9YAxisPos "The position of the joystick in the relative motion of travel from the neutral position.";
CM_ SG_ 2365400830 Jystck9YAxsLvrFrwrdPstvPsStatus "Reports when the current joystick position is on the positive travel side (forward, right, clockwise, up) relative to the";
CM_ SG_ 2365400830 Jystck9YAxsLvrBckNgtvePosStatus "Reports when the current joystick position is on the negative travel side (back, left, counterclockwise, down) relative to the";
CM_ SG_ 2365400830 Joystick9YAxisNeutralPosStatus "Reports when the current joystick position is in the neutral position for that axis of travel.";
CM_ SG_ 2365400830 Joystick9XAxisPos "The position of the joystick in the relative motion of travel from the neutral position.";
CM_ SG_ 2365400830 Jystck9XAxsLvrRghtPstvPosStatus "Reports when the current joystick position is on the positive travel side (forward, right, clockwise, up) relative to the";
CM_ SG_ 2365400830 Jystck9XAxsLvrLftNgtvePosStatus "Reports when the current joystick position is on the negative travel side (back, left, counterclockwise, down) relative to the";
CM_ SG_ 2365400830 Joystick9XAxisNeutralPosStatus "Reports when the current joystick position is in the neutral position for that axis of travel.";
CM_ BO_ 2365401342 "Basic Joystick Message 8";
CM_ SG_ 2365401342 Joystick8Button9PressedStatus "Reports when the joystick button has been pressed.";
CM_ SG_ 2365401342 Joystick8Button10PressedStatus "Reports when the joystick button has been pressed.";
CM_ SG_ 2365401342 Joystick8Button11PressedStatus "Reports when the joystick button has been pressed.";
CM_ SG_ 2365401342 Joystick8Button12PressedStatus "Reports when the joystick button has been pressed.";
CM_ SG_ 2365401342 Joystick8Button5PressedStatus "Reports when the joystick button has been pressed.";
CM_ SG_ 2365401342 Joystick8Button6PressedStatus "Reports when the joystick button has been pressed.";
CM_ SG_ 2365401342 Joystick8Button7PressedStatus "Reports when the joystick button has been pressed.";
CM_ SG_ 2365401342 Joystick8Button8PressedStatus "Reports when the joystick button has been pressed.";
CM_ SG_ 2365401342 Joystick8Button1PressedStatus "Reports when the joystick button has been pressed.";
CM_ SG_ 2365401342 Joystick8Button2PressedStatus "Reports when the joystick button has been pressed.";
CM_ SG_ 2365401342 Joystick8Button3PressedStatus "Reports when the joystick button has been pressed.";
CM_ SG_ 2365401342 Joystick8Button4PressedStatus "Reports when the joystick button has been pressed.";
CM_ SG_ 2365401342 Joystick8XAxisDetentPosStatus "Reports when the current joystick position is in the detent position for that axis of travel.";
CM_ SG_ 2365401342 Joystick8YAxisDetentPosStatus "Reports when the current joystick position is in the detent position for that axis of travel.";
CM_ SG_ 2365401342 Joystick8YAxisPos "The position of the joystick in the relative motion of travel from the neutral position.";
CM_ SG_ 2365401342 Jystck8YAxsLvrFrwrdPstvPsStatus "Reports when the current joystick position is on the positive travel side (forward, right, clockwise, up) relative to the";
CM_ SG_ 2365401342 Jystck8YAxsLvrBckNgtvePosStatus "Reports when the current joystick position is on the negative travel side (back, left, counterclockwise, down) relative to the";
CM_ SG_ 2365401342 Joystick8YAxisNeutralPosStatus "Reports when the current joystick position is in the neutral position for that axis of travel.";
CM_ SG_ 2365401342 Joystick8XAxisPos "The position of the joystick in the relative motion of travel from the neutral position.";
CM_ SG_ 2365401342 Jystck8XAxsLvrRghtPstvPosStatus "Reports when the current joystick position is on the positive travel side (forward, right, clockwise, up) relative to the";
CM_ SG_ 2365401342 Jystck8XAxsLvrLftNgtvePosStatus "Reports when the current joystick position is on the negative travel side (back, left, counterclockwise, down) relative to the";
CM_ SG_ 2365401342 Joystick8XAxisNeutralPosStatus "Reports when the current joystick position is in the neutral position for that axis of travel.";
CM_ BO_ 2365401854 "Basic Joystick Message 7";
CM_ SG_ 2365401854 Joystick7Button9PressedStatus "Reports when the joystick button has been pressed.";
CM_ SG_ 2365401854 Joystick7Button10PressedStatus "Reports when the joystick button has been pressed.";
CM_ SG_ 2365401854 Joystick7Button11PressedStatus "Reports when the joystick button has been pressed.";
CM_ SG_ 2365401854 Joystick7Button12PressedStatus "Reports when the joystick button has been pressed.";
CM_ SG_ 2365401854 Joystick7Button5PressedStatus "Reports when the joystick button has been pressed.";
CM_ SG_ 2365401854 Joystick7Button6PressedStatus "Reports when the joystick button has been pressed.";
CM_ SG_ 2365401854 Joystick7Button7PressedStatus "Reports when the joystick button has been pressed.";
CM_ SG_ 2365401854 Joystick7Button8PressedStatus "Reports when the joystick button has been pressed.";
CM_ SG_ 2365401854 Joystick7Button1PressedStatus "Reports when the joystick button has been pressed.";
CM_ SG_ 2365401854 Joystick7Button2PressedStatus "Reports when the joystick button has been pressed.";
CM_ SG_ 2365401854 Joystick7Button3PressedStatus "Reports when the joystick button has been pressed.";
CM_ SG_ 2365401854 Joystick7Button4PressedStatus "Reports when the joystick button has been pressed.";
CM_ SG_ 2365401854 Joystick7XAxisDetentPosStatus "Reports when the current joystick position is in the detent position for that axis of travel.";
CM_ SG_ 2365401854 Joystick7YAxisDetentPosStatus "Reports when the current joystick position is in the detent position for that axis of travel.";
CM_ SG_ 2365401854 Joystick7YAxisPos "The position of the joystick in the relative motion of travel from the neutral position.";
CM_ SG_ 2365401854 Jystck7YAxsLvrFrwrdPstvPsStatus "Reports when the current joystick position is on the positive travel side (forward, right, clockwise, up) relative to the";
CM_ SG_ 2365401854 Jystck7YAxsLvrBckNgtvePosStatus "Reports when the current joystick position is on the negative travel side (back, left, counterclockwise, down) relative to the";
CM_ SG_ 2365401854 Joystick7YAxisNeutralPosStatus "Reports when the current joystick position is in the neutral position for that axis of travel.";
CM_ SG_ 2365401854 Joystick7XAxisPos "The position of the joystick in the relative motion of travel from the neutral position.";
CM_ SG_ 2365401854 Jystck7XAxsLvrRghtPstvPosStatus "Reports when the current joystick position is on the positive travel side (forward, right, clockwise, up) relative to the";
CM_ SG_ 2365401854 Jystck7XAxsLvrLftNgtvePosStatus "Reports when the current joystick position is on the negative travel side (back, left, counterclockwise, down) relative to the";
CM_ SG_ 2365401854 Joystick7XAxisNeutralPosStatus "Reports when the current joystick position is in the neutral position for that axis of travel.";
CM_ BO_ 2365402366 "Basic Joystick Message 6";
CM_ SG_ 2365402366 Joystick6Button9PressedStatus "Reports when the joystick button has been pressed.";
CM_ SG_ 2365402366 Joystick6Button10PressedStatus "Reports when the joystick button has been pressed.";
CM_ SG_ 2365402366 Joystick6Button11PressedStatus "Reports when the joystick button has been pressed.";
CM_ SG_ 2365402366 Joystick6Button12PressedStatus "Reports when the joystick button has been pressed.";
CM_ SG_ 2365402366 Joystick6Button5PressedStatus "Reports when the joystick button has been pressed.";
CM_ SG_ 2365402366 Joystick6Button6PressedStatus "Reports when the joystick button has been pressed.";
CM_ SG_ 2365402366 Joystick6Button7PressedStatus "Reports when the joystick button has been pressed.";
CM_ SG_ 2365402366 Joystick6Button8PressedStatus "Reports when the joystick button has been pressed.";
CM_ SG_ 2365402366 Joystick6Button1PressedStatus "Reports when the joystick button has been pressed.";
CM_ SG_ 2365402366 Joystick6Button2PressedStatus "Reports when the joystick button has been pressed.";
CM_ SG_ 2365402366 Joystick6Button3PressedStatus "Reports when the joystick button has been pressed.";
CM_ SG_ 2365402366 Joystick6Button4PressedStatus "Reports when the joystick button has been pressed.";
CM_ SG_ 2365402366 Joystick6XAxisDetentPosStatus "Reports when the current joystick position is in the detent position for that axis of travel.";
CM_ SG_ 2365402366 Joystick6YAxisDetentPosStatus "Reports when the current joystick position is in the detent position for that axis of travel.";
CM_ SG_ 2365402366 Joystick6YAxisPos "The position of the joystick in the relative motion of travel from the neutral position.";
CM_ SG_ 2365402366 Jystck6YAxsLvrFrwrdPstvPsStatus "Reports when the current joystick position is on the positive travel side (forward, right, clockwise, up) relative to the";
CM_ SG_ 2365402366 Jystck6YAxsLvrBckNgtvePosStatus "Reports when the current joystick position is on the negative travel side (back, left, counterclockwise, down) relative to the";
CM_ SG_ 2365402366 Joystick6YAxisNeutralPosStatus "Reports when the current joystick position is in the neutral position for that axis of travel.";
CM_ SG_ 2365402366 Joystick6XAxisPos "The position of the joystick in the relative motion of travel from the neutral position.";
CM_ SG_ 2365402366 Jystck6XAxsLvrRghtPstvPosStatus "Reports when the current joystick position is on the positive travel side (forward, right, clockwise, up) relative to the";
CM_ SG_ 2365402366 Jystck6XAxsLvrLftNgtvePosStatus "Reports when the current joystick position is on the negative travel side (back, left, counterclockwise, down) relative to the";
CM_ SG_ 2365402366 Joystick6XAxisNeutralPosStatus "Reports when the current joystick position is in the neutral position for that axis of travel.";
CM_ BO_ 2365402878 "Basic Joystick Message 5";
CM_ SG_ 2365402878 Joystick5Button9PressedStatus "Reports when the joystick button has been pressed.";
CM_ SG_ 2365402878 Joystick5Button10PressedStatus "Reports when the joystick button has been pressed.";
CM_ SG_ 2365402878 Joystick5Button11PressedStatus "Reports when the joystick button has been pressed.";
CM_ SG_ 2365402878 Joystick5Button12PressedStatus "Reports when the joystick button has been pressed.";
CM_ SG_ 2365402878 Joystick5Button5PressedStatus "Reports when the joystick button has been pressed.";
CM_ SG_ 2365402878 Joystick5Button6PressedStatus "Reports when the joystick button has been pressed.";
CM_ SG_ 2365402878 Joystick5Button7PressedStatus "Reports when the joystick button has been pressed.";
CM_ SG_ 2365402878 Joystick5Button8PressedStatus "Reports when the joystick button has been pressed.";
CM_ SG_ 2365402878 Joystick5Button1PressedStatus "Reports when the joystick button has been pressed.";
CM_ SG_ 2365402878 Joystick5Button2PressedStatus "Reports when the joystick button has been pressed.";
CM_ SG_ 2365402878 Joystick5Button3PressedStatus "Reports when the joystick button has been pressed.";
CM_ SG_ 2365402878 Joystick5Button4PressedStatus "Reports when the joystick button has been pressed.";
CM_ SG_ 2365402878 Joystick5XAxisDetentPosStatus "Reports when the current joystick position is in the detent position for that axis of travel.";
CM_ SG_ 2365402878 Joystick5YAxisDetentPosStatus "Reports when the current joystick position is in the detent position for that axis of travel.";
CM_ SG_ 2365402878 Joystick5YAxisPos "The position of the joystick in the relative motion of travel from the neutral position.";
CM_ SG_ 2365402878 Jystck5YAxsLvrFrwrdPstvPsStatus "Reports when the current joystick position is on the positive travel side (forward, right, clockwise, up) relative to the";
CM_ SG_ 2365402878 Jystck5YAxsLvrBckNgtvePosStatus "Reports when the current joystick position is on the negative travel side (back, left, counterclockwise, down) relative to the";
CM_ SG_ 2365402878 Joystick5YAxisNeutralPosStatus "Reports when the current joystick position is in the neutral position for that axis of travel.";
CM_ SG_ 2365402878 Joystick5XAxisPos "The position of the joystick in the relative motion of travel from the neutral position.";
CM_ SG_ 2365402878 Jystck5XAxsLvrRghtPstvPosStatus "Reports when the current joystick position is on the positive travel side (forward, right, clockwise, up) relative to the";
CM_ SG_ 2365402878 Jystck5XAxsLvrLftNgtvePosStatus "Reports when the current joystick position is on the negative travel side (back, left, counterclockwise, down) relative to the";
CM_ SG_ 2365402878 Joystick5XAxisNeutralPosStatus "Reports when the current joystick position is in the neutral position for that axis of travel.";
CM_ BO_ 2365403390 "Basic Joystick Message 4";
CM_ SG_ 2365403390 Joystick4Button9PressedStatus "Reports when the joystick button has been pressed.";
CM_ SG_ 2365403390 Joystick4Button10PressedStatus "Reports when the joystick button has been pressed.";
CM_ SG_ 2365403390 Joystick4Button11PressedStatus "Reports when the joystick button has been pressed.";
CM_ SG_ 2365403390 Joystick4Button12PressedStatus "Reports when the joystick button has been pressed.";
CM_ SG_ 2365403390 Joystick4Button5PressedStatus "Reports when the joystick button has been pressed.";
CM_ SG_ 2365403390 Joystick4Button6PressedStatus "Reports when the joystick button has been pressed.";
CM_ SG_ 2365403390 Joystick4Button7PressedStatus "Reports when the joystick button has been pressed.";
CM_ SG_ 2365403390 Joystick4Button8PressedStatus "Reports when the joystick button has been pressed.";
CM_ SG_ 2365403390 Joystick4Button1PressedStatus "Reports when the joystick button has been pressed.";
CM_ SG_ 2365403390 Joystick4Button2PressedStatus "Reports when the joystick button has been pressed.";
CM_ SG_ 2365403390 Joystick4Button3PressedStatus "Reports when the joystick button has been pressed.";
CM_ SG_ 2365403390 Joystick4Button4PressedStatus "Reports when the joystick button has been pressed.";
CM_ SG_ 2365403390 Joystick4XAxisDetentPosStatus "Reports when the current joystick position is in the detent position for that axis of travel.";
CM_ SG_ 2365403390 Joystick4YAxisDetentPosStatus "Reports when the current joystick position is in the detent position for that axis of travel.";
CM_ SG_ 2365403390 Joystick4YAxisPos "The position of the joystick in the relative motion of travel from the neutral position.";
CM_ SG_ 2365403390 Jystck4YAxsLvrFrwrdPstvPsStatus "Reports when the current joystick position is on the positive travel side (forward, right, clockwise, up) relative to the";
CM_ SG_ 2365403390 Jystck4YAxsLvrBckNgtvePosStatus "Reports when the current joystick position is on the negative travel side (back, left, counterclockwise, down) relative to the";
CM_ SG_ 2365403390 Joystick4YAxisNeutralPosStatus "Reports when the current joystick position is in the neutral position for that axis of travel.";
CM_ SG_ 2365403390 Joystick4XAxisPos "The position of the joystick in the relative motion of travel from the neutral position.";
CM_ SG_ 2365403390 Jystck4XAxsLvrRghtPstvPosStatus "Reports when the current joystick position is on the positive travel side (forward, right, clockwise, up) relative to the";
CM_ SG_ 2365403390 Jystck4XAxsLvrLftNgtvePosStatus "Reports when the current joystick position is on the negative travel side (back, left, counterclockwise, down) relative to the";
CM_ SG_ 2365403390 Joystick4XAxisNeutralPosStatus "Reports when the current joystick position is in the neutral position for that axis of travel.";
CM_ BO_ 2365400318 "Basic Joystick Message 10";
CM_ SG_ 2365400318 Joystick10Button9PressedStatus "Reports when the joystick button has been pressed.";
CM_ SG_ 2365400318 Joystick10Button10PressedStatus "Reports when the joystick button has been pressed.";
CM_ SG_ 2365400318 Joystick10Button11PressedStatus "Reports when the joystick button has been pressed.";
CM_ SG_ 2365400318 Joystick10Button12PressedStatus "Reports when the joystick button has been pressed.";
CM_ SG_ 2365400318 Joystick10Button5PressedStatus "Reports when the joystick button has been pressed.";
CM_ SG_ 2365400318 Joystick10Button6PressedStatus "Reports when the joystick button has been pressed.";
CM_ SG_ 2365400318 Joystick10Button7PressedStatus "Reports when the joystick button has been pressed.";
CM_ SG_ 2365400318 Joystick10Button8PressedStatus "Reports when the joystick button has been pressed.";
CM_ SG_ 2365400318 Joystick10Button1PressedStatus "Reports when the joystick button has been pressed.";
CM_ SG_ 2365400318 Joystick10Button2PressedStatus "Reports when the joystick button has been pressed.";
CM_ SG_ 2365400318 Joystick10Button3PressedStatus "Reports when the joystick button has been pressed.";
CM_ SG_ 2365400318 Joystick10Button4PressedStatus "Reports when the joystick button has been pressed.";
CM_ SG_ 2365400318 Joystick10XAxisDetentPosStatus "Reports when the current joystick position is in the detent position for that axis of travel.";
CM_ SG_ 2365400318 Joystick10YAxisDetentPosStatus "Reports when the current joystick position is in the detent position for that axis of travel.";
CM_ SG_ 2365400318 Joystick10YAxisPos "The position of the joystick in the relative motion of travel from the neutral position.";
CM_ SG_ 2365400318 Jystck10YAxsLvrFrwrdPstvPsSttus "Reports when the current joystick position is on the positive travel side (forward, right, clockwise, up) relative to the";
CM_ SG_ 2365400318 Jystck10YAxsLvrBckNgtvPosStatus "Reports when the current joystick position is on the negative travel side (back, left, counterclockwise, down) relative to the";
CM_ SG_ 2365400318 Joystick10YAxisNeutralPosStatus "Reports when the current joystick position is in the neutral position for that axis of travel.";
CM_ SG_ 2365400318 Joystick10XAxisPos "The position of the joystick in the relative motion of travel from the neutral position.";
CM_ SG_ 2365400318 Jystck10XAxsLvrRghtPstvPsStatus "Reports when the current joystick position is on the positive travel side (forward, right, clockwise, up) relative to the";
CM_ SG_ 2365400318 Jystck10XAxsLvrLftNgtvPosStatus "Reports when the current joystick position is on the negative travel side (back, left, counterclockwise, down) relative to the";
CM_ SG_ 2365400318 Joystick10XAxisNeutralPosStatus "Reports when the current joystick position is in the neutral position for that axis of travel.";
CM_ BO_ 2499614718 "Beltlock and Airbag Deactivation Switch Information";
CM_ SG_ 2499614718 PssngrArbgDctvationSwitchStatus "State of switch used to deactivate Passenger Airbag manually.";
CM_ SG_ 2499614718 Beltlock10Status "State of switch used to determine if Beltlock 10 is buckled.";
CM_ SG_ 2499614718 Beltlock9Status "State of switch used to determine if Beltlock 9 is buckled.";
CM_ SG_ 2499614718 Beltlock8Status "State of switch used to determine if Beltlock 8 is buckled.";
CM_ SG_ 2499614718 Beltlock7Status "State of switch used to determine if Beltlock 7 is buckled.";
CM_ SG_ 2499614718 Beltlock6Status "State of switch used to determine if Beltlock 6 is buckled.";
CM_ SG_ 2499614718 Beltlock5Status "State of switch used to determine if Beltlock 5 is buckled.";
CM_ SG_ 2499614718 Beltlock4Status "State of switch used to determine if Beltlock 4 is buckled.";
CM_ SG_ 2499614718 Beltlock3Status "State of switch used to determine if Beltlock 3 is buckled.";
CM_ SG_ 2499614718 PassengerBeltlockStatus "State of switch used to determine if Passenger Beltlock is buckled.";
CM_ SG_ 2499614718 DriverBeltlockStatus "State of switch used to determine if Driver Beltlock is buckled.";
CM_ BO_ 2566722814 "Battery Charger 2";
CM_ SG_ 2566722814 BatteryCharger2OutputCurrent "Output current of the battery charger connected to the main battery.";
CM_ SG_ 2566722814 BatteryCharger2OutputVoltage "Output voltage measured on the battery terminals of the offline battery charger connected to the auxiliary battery.";
CM_ SG_ 2566722814 BatteryCharger2PowerLineState "A state of the battery charger connection to the power line for the charger connected to the auxiliary battery.";
CM_ SG_ 2566722814 BatteryCharger2State "A state of the offline battery charger connected to the auxiliary battery.";
CM_ BO_ 2566723070 "Battery Charger 1";
CM_ SG_ 2566723070 BatteryCharger1OutputCurrent "Output current of the battery charger connected to the main battery.";
CM_ SG_ 2566723070 BatteryCharger1OutputVoltage "Output voltage measured on the battery terminals of the battery charger connected to the main battery.";
CM_ SG_ 2566723070 BatteryCharger1PowerLineState "A state of the battery charger connection to the power line for the charger connected to the main battery.";
CM_ SG_ 2566723070 BatteryCharger1State "A state of the battery charger connected to the main battery.";
CM_ BO_ 2566725118 "Aftertreatment Differential Temperature 2";
CM_ SG_ 2566725118 Aftrtrtmnt2ThrWyCtlystDffGsTemp "The differential engine combustion byproducts gas temperature measured between the intake and outlet of the three way";
CM_ SG_ 2566725118 Aftrtrtmnt1ThrWyCtlystDffGsTemp "The differential engine combustion byproducts gas temperature measured between the intake and outlet of the three way";
CM_ BO_ 2566725374 "Aftertreatment Differential Temperature 1";
CM_ SG_ 2566725374 Aftrtrtmnt2GsOxdtnCtlystDffGsTmp "The differential engine combustion byproducts gas temperature measured between the intake and outlet of the gas";
CM_ SG_ 2566725374 Aftrtrtmnt1GsOxdtnCtlystDffGsTmp "The differential engine combustion byproducts gas temperature measured between the intake and outlet of the gas";
CM_ BO_ 2566712830 "Aftertreatment 2 Warm Up Diesel Oxidation Catalyst Information";
CM_ SG_ 2566712830 Aftrtrtmnt2WrmUpDslOxdtnCtlystOt "Temperature of engine combustion byproducts leaving the warm up Diesel Oxidation Catalyst in exhaust bank 2.";
CM_ SG_ 2566712830 Aftrtrtmnt2WrmUpDslOxdtnCtlystIn "Temperature of engine combustion byproducts entering the warm up Diesel Oxidation Catalyst in exhaust bank 2.";
CM_ BO_ 2566735358 "Aftertreatment 2 Three Way Catalytic Converter";
CM_ SG_ 2566735358 Aftrtrtmnt2ThrWyCtlytcCnvrtrDffP "Used to identify the applicable J1939-73 FMI detected in the Three Way Catalytic Converter differential pressure sensor";
CM_ SG_ 2566735358 Aftrtrtmnt2ThrWyCtlytcCnvrtrOtlt "Used to identify the applicable J1939-73 FMI detected in the Three Way Catalytic Converter outlet gas temperature";
CM_ SG_ 2566735358 Aftrtrtmnt2ThrWyCtlytcCnvrtrIntk "Used to identify the applicable J1939-73 FMI detected in the Three Way Catalytic Converter intake gas temperature";
CM_ SG_ 2566735358 Aftrtrtmnt2ThrWyCtlytcCnvrt_0000 "Exhaust differential pressure measured between the intake and exhaust of a Three Way Catalytic Converter in exhaust";
CM_ SG_ 2566735358 Aftrtrtmnt2ThrWyCtlytcCnvrt_0001 "Temperature of engine combustion byproducts leaving the Three Way Catalytic Converter in exhaust bank 2.";
CM_ SG_ 2566735358 Aftrtrtmnt2ThrWyCtlytcCnvrt_0002 "Temperature of engine combustion byproducts entering the Three Way Catalytic Converter in exhaust bank 2.";
CM_ BO_ 2365393662 "Aftertreatment 2 Outlet Gas NOx Sensor correction data 2";
CM_ SG_ 2365393662 Aftrtrtmnt2OtltGsNOxSnsrNH3Crrct "Correction of NH3 at the NOx-signal to correct (recalculate) sensor signal on the Engine ECU side.";
CM_ SG_ 2365393662 Aftrtrtmnt2OtltGsNOxSnsrNO2Crrct "Correction of NO2 at the NOx-signal to correct (recalculate) sensor signal on the Engine ECU side.";
CM_ SG_ 2365393662 Aftrtrtmnt2OtltGsNOxSnsrCrrctnOf "Correction of pressure NOx-signal to correct (recalculate) sensor signal on the Engine ECU side.";
CM_ SG_ 2365393662 Aftrtrtmnt2OtltGsNOxSnsrCrr_0000 "Correction of pressure Lambda-signal to correct (recalculate) sensor signal on the Engine ECU side.";
CM_ BO_ 2365393918 "Aftertreatment 2 Outlet Gas NOx Sensor correction data";
CM_ SG_ 2365393918 Aftrtrtmnt2OtltGsNOxSnsrNwPrtDvt "New part deviation NOx_Offset to correct (recalculate) sensor signal on the Engine ECU side.";
CM_ SG_ 2365393918 Aftrtrtmnt2OtltGsNOxSnsrNwP_0000 "New part deviation NOx_Gain to correct (recalculate) sensor signal on the Engine ECU side.";
CM_ SG_ 2365393918 Aftrtrtmnt2OtltGsNOxSnsrHtrRtio "Heater ratio to determine temperature at sensor tip.";
CM_ BO_ 2365394174 "Aftertreatment 2 Intake Gas NOx Sensor correction data 2";
CM_ SG_ 2365394174 Aftrtrtmnt2IntkGsNOxSnsrNH3Crrct "Correction of NH3 at the NOx-signal to correct (recalculate) sensor signal on the Engine ECU side.";
CM_ SG_ 2365394174 Aftrtrtmnt2IntkGsNOxSnsrNO2Crrct "Correction of NO2 at the NOx-signal to correct (recalculate) sensor signal on the Engine ECU side.";
CM_ SG_ 2365394174 Aftrtrtmnt2IntkGsNOxSnsrCrrctnOf "Correction of pressure NOx-signal to correct (recalculate) sensor signal on the Engine ECU side.";
CM_ SG_ 2365394174 Aftrtrtmnt2IntkGsNOxSnsrCrr_0000 "Correction of pressure Lambda-signal to correct (recalculate) sensor signal on the Engine ECU side.";
CM_ BO_ 2365394430 "Aftertreatment 2 Intake Gas NOx Sensor correction data";
CM_ SG_ 2365394430 Aftrtrtmnt2IntkGsNOxSnsrNwPrtDvt "New part deviation NOx_Offset to correct (recalculate) sensor signal on the Engine ECU side.";
CM_ SG_ 2365394430 Aftrtrtmnt2IntkGsNOxSnsrNwP_0000 "New part deviation NOx_Gain to correct (recalculate) sensor signal on the Engine ECU side.";
CM_ SG_ 2365394430 Aftrtrtmnt2IntkGsNOxSnsrHtrRtio "Heater ratio to determine temperature at sensor tip.";
CM_ BO_ 2566735102 "Aftertreatment 2 Fuel Control 2";
CM_ SG_ 2566735102 Aftertreatment2FuelPress2Ctrl "Indicates how the device is controlling the aftertreatment 2 fuel pressure 2 regulating control valve.";
CM_ SG_ 2566735102 Aftrtrtmnt2FlFlwDvrterValveCtrl "Indicates how the device is controlling the aftertreatment 2 fuel flow diverter valve.";
CM_ SG_ 2566735102 Aftrtreatment2FuelPumpRelayCtrl "Indicates how the device is controlling the aftertreatment 2 fuel pump relay.";
CM_ SG_ 2566735102 Aftertreatment2FuelPress2 "Second fuel pressure measurement for the aftertreatment 2 system.";
CM_ BO_ 2157313790 "Aftertreatment 2 Diesel Particulate Filter Soot Sensor Calibration";
CM_ SG_ 2157313790 Aftrtrtmnt2DslPrtcltFltrStStndrd "Calibration offset for the soot standard deviation for Aftertreatment 2 Diesel Particulate Filter soot sensor.";
CM_ SG_ 2157313790 Aftrtrtmnt2DslPrtcltFltrStMnClbO "Calibration offset for the soot Mean for Aftertreatment 2 Diesel Particulate Filter soot sensor.";
CM_ BO_ 2566724350 "Aftertreatment 1 Warm Up Diesel Oxidation Catalyst Information";
CM_ SG_ 2566724350 Aftrtrtmnt1WrmUpDslOxdtnCtlystOt "This is the temperature measured at the outlet of the warm up oxidation catalytic converter in exhaust bank 1.";
CM_ SG_ 2566724350 Aftrtrtmnt1WrmUpDslOxdtnCtlystIn "This is the temperature measured at the intake of the warm up oxidation catalytic converter in exhaust bank 1.";
CM_ BO_ 2566735614 "Aftertreatment 1 Three Way Catalytic Converter";
CM_ SG_ 2566735614 Aftrtrtmnt1ThrWyCtlytcCnvrtrDffP "Used to identify the applicable J1939-73 FMI detected in the Three Way Catalytic Converter differential pressure sensor";
CM_ SG_ 2566735614 Aftrtrtmnt1ThrWyCtlytcCnvrtrOtlt "Used to identify the applicable J1939-73 FMI detected in the Three Way Catalytic Converter outlet gas temperature";
CM_ SG_ 2566735614 Aftrtrtmnt1ThrWyCtlytcCnvrtrIntk "Used to identify the applicable J1939-73 FMI detected in the Three Way Catalytic Converter intake gas temperature";
CM_ SG_ 2566735614 Aftrtrtmnt1ThrWyCtlytcCnvrt_0000 "Exhaust differential pressure measured between the intake and exhaust of a Three Way Catalytic Converter in exhaust";
CM_ SG_ 2566735614 Aftrtrtmnt1ThrWyCtlytcCnvrt_0001 "Temperature of engine combustion byproducts leaving the Three Way Catalytic Converter in exhaust bank 1.";
CM_ SG_ 2566735614 Aftrtrtmnt1ThrWyCtlytcCnvrt_0002 "Temperature of engine combustion byproducts entering the Three Way Catalytic Converter in exhaust bank 1.";
CM_ BO_ 2566805246 "Aftertreatment 1 SCR Reagent Tank 1 Information";
CM_ SG_ 2566805246 Aftrtrtmnt1SCRCtlystRgntTnk1HtrP "Used to identify the applicable J1939-73 FMI detected in the SCR catalyst reagent tank 1 heater, by the manufacturer's";
CM_ SG_ 2566805246 Aftrtrtmnt1SCRCtalystTankHeater "Percentage of heating applied to the aftertreatment 1 catalyst tank heater.";
CM_ SG_ 2566805246 AftrtrtmntSCROprtrIndcmntSvrity "The severity of operator inducement for anomolies with the SCR system, such as tampering, low DEF quality, and DEF";
CM_ SG_ 2566805246 Aftrtrtmnt1SCRCtlystRgntTnk1TmpP "Used to identify the applicable J1939-73 FMI detected in the SCR catalyst reagent tank 1 temperature, by the";
CM_ SG_ 2566805246 Aftrtrtmnt1DEFTnkLwLvlIndicator "The desired illumination of the driver's warning indicator for diesel exhaust fluid (DEF) tank low level.";
CM_ SG_ 2566805246 Aftrtrtmnt1SCRCtlystTnkLvlPrlmnr "Used to identify the applicable J1939-73 FMI that applies to the most significant failure of the catalyst tank level sensor.";
CM_ SG_ 2566805246 Aftrtrtmnt1SCRCtalystTankLevel2 "The measure of the reagent level in the catalyst tank.";
CM_ SG_ 2566805246 Aftrtrtment1SCRCatalystTankTemp "Temperature of the reagent in the storage tank.";
CM_ SG_ 2566805246 Aftrtrtmnt1SCRCatalystTankLevel "A special catalyst uses a chemical reagent to reach legal requirement for NOX emissions.";
CM_ BO_ 2365394686 "Aftertreatment 1 Outlet Gas NOx Sensor correction data 2";
CM_ SG_ 2365394686 Aftrtrtmnt1OtltGsNOxSnsrNH3Crrct "Correction of NH3 at the NOx-signal to correct (recalculate) sensor signal on the Engine ECU side.";
CM_ SG_ 2365394686 Aftrtrtmnt1OtltGsNOxSnsrNO2Crrct "Correction of NO2 at the NOx-signal to correct (recalculate) sensor signal on the Engine ECU side.";
CM_ SG_ 2365394686 Aftrtrtmnt1OtltGsNOxSnsrCrrctnOf "Correction of pressure NOx-signal to correct (recalculate) sensor signal on the Engine ECU side.";
CM_ SG_ 2365394686 Aftrtrtmnt1OtltGsNOxSnsrCrr_0000 "Correction of pressure Lambda-signal to correct (recalculate) sensor signal on the Engine ECU side.";
CM_ BO_ 2365394942 "Aftertreatment 1 Outlet Gas NOx Sensor correction data";
CM_ SG_ 2365394942 Aftrtrtmnt1OtltGsNOxSnsrNwPrtDvt "New part deviation NOx_Offset to correct (recalculate) sensor signal on the Engine ECU side.";
CM_ SG_ 2365394942 Aftrtrtmnt1OtltGsNOxSnsrNwP_0000 "New part deviation NOx_Gain to correct (recalculate) sensor signal on the Engine ECU side.";
CM_ SG_ 2365394942 Aftrtrtmnt1OtltGsNOxSnsrHtrRtio "Heater ratio to determine temperature at sensor tip.";
CM_ BO_ 2365395198 "Aftertreatment 1 Intake Gas NOx Sensor correction data 2";
CM_ SG_ 2365395198 Aftrtrtmnt1IntkGsNOxSnsrNH3Crrct "Correction of NH3 at the NOx-signal to correct (recalculate) sensor signal on the Engine ECU side.";
CM_ SG_ 2365395198 Aftrtrtmnt1IntkGsNOxSnsrNO2Crrct "Correction of NO2 at the NOx-signal to correct (recalculate) sensor signal on the Engine ECU side.";
CM_ SG_ 2365395198 Aftrtrtmnt1IntkGsNOxSnsrCrrctnOf "Correction of pressure NOx-signal to correct (recalculate) sensor signal on the Engine ECU side.";
CM_ SG_ 2365395198 Aftrtrtmnt1IntkGsNOxSnsrCrr_0000 "Correction of pressure Lambda-signal to correct (recalculate) sensor signal on the Engine ECU side.";
CM_ BO_ 2365395454 "Aftertreatment 1 Intake Gas NOx Sensor correction data";
CM_ SG_ 2365395454 Aftrtrtmnt1IntkGsNOxSnsrNwPrtDvt "New part deviation NOx_Offset to correct (recalculate) sensor signal on the Engine ECU side.";
CM_ SG_ 2365395454 Aftrtrtmnt1IntkGsNOxSnsrNwP_0000 "New part deviation NOx_Gain to correct (recalculate) sensor signal on the Engine ECU side.";
CM_ SG_ 2365395454 Aftrtrtmnt1IntkGsNOxSnsrHtrRtio "Heater ratio to determine temperature at sensor tip.";
CM_ BO_ 2157248254 "Aftertreatment 1 Diesel Particulate Filter Soot Sensor Calibration";
CM_ SG_ 2157248254 Aftrtrtmnt1DslPrtcltFltrStStndrd "Calibration offset for the soot standard deviation for Aftertreatment 1 Diesel Particulate Filter soot sensor.";
CM_ SG_ 2157248254 Aftrtrtmnt1DslPrtcltFltrStMnClbO "Calibration offset for the soot Mean for Aftertreatment 1 Diesel Particulate Filter soot sensor.";
CM_ BO_ 2566711806 "Armrest Switch Matrix Commands";
CM_ SG_ 2566711806 ArmrestSwitchMatrix2Switch2 "Second switch input matrix for the second module located in the armrest";
CM_ SG_ 2566711806 ArmrestSwitchMatrix2Switch1 "Switch input matrix for the second module located in the armrest";
CM_ SG_ 2566711806 ArmrestSwitchMatrixSwitch2 "Second switch input matrix for the module located in the armrest";
CM_ SG_ 2566711806 ArmrestSwitchMatrixSwitch1 "Switch input matrix for the module located in the armrest";
CM_ BO_ 2364549886 "Angular Rate Information";
CM_ SG_ 2364549886 AngularRateMeasurementLatency "The estimated measurement latency of the measurement.";
CM_ SG_ 2364549886 YawRateExRangeFigureOfMerit "Figure of merit for yaw angle measurement.";
CM_ SG_ 2364549886 RollRateExRangeFigureOfMerit "Figure of merit for roll angle measurement.";
CM_ SG_ 2364549886 PitchRateExRangeFigureOfMerit "Figure of merit for pitch angle measurement.";
CM_ SG_ 2364549886 YawRateExRange "Yaw rate is the rate-of-change of the yaw angle over time.";
CM_ SG_ 2364549886 RollRateExRange "Roll rate is the rate-of-change of the roll angle over time.";
CM_ SG_ 2364549886 PitchRateExRange "Pitch rate is the rate-of-change of the pitch angle over time, where the pitch angle vector is in the direction of travel of the";
CM_ BO_ 2566712318 "Aftertreatment 2 NOx Adsorber Information";
CM_ SG_ 2566712318 Aftrtrtmnt2NOxAdsrbrDSOxRgnrtnSt "Indicates whether the NOx adsorber deSOx regeneration in the second aftertreatment system is active or inactive";
CM_ SG_ 2566712318 Aftrtrtmnt2NOxAdsrbrDNOxRgnrtnSt "Indicates whether the NOx adsorber deNOx regeneration in the second aftertreatment system is active or inactive";
CM_ BO_ 2566712574 "Aftertreatment 1 NOx Adsorber Information";
CM_ SG_ 2566712574 Aftrtrtmnt1NOxAdsrbrDSOxRgnrtnSt "Indicates whether the NOx adsorber deSOx regeneration in the first aftertreatment system is active or inactive";
CM_ SG_ 2566712574 Aftrtrtmnt1NOxAdsrbrDNOxRgnrtnSt "Indicates whether the NOx adsorber deNOx regeneration in the first aftertreatment system is active or inactive";
CM_ BO_ 2164078590 "Aftertreatment 2 SCR Service Information";
CM_ SG_ 2164078590 Aftrtrtmnt2SCRCtlystCnvrsnEffcnc "The SCR catalyst conversion efficiency percentage.";
CM_ SG_ 2164078590 Aftrtrtmnt2SCRCmddCtlystRgntCnsm "This parameter transmits the amount of reagent that the emissions control system has requested to be used, averaged";
CM_ SG_ 2164078590 Aftrtrtmnt2SCRAvrgCtlystRgntCnsm "Measured use of reagent by a Selective Catalytic Reduction system for exhaust emission control, averaged over the";
CM_ BO_ 2566731006 "Aftertreatment 2 SCR Reagant Tank 2 Information";
CM_ SG_ 2566731006 Aftrtrtmnt2SCRCtlystRgntTnk2HtrP "Used to identify the applicable J1939-73 FMI detected in the SCR catalyst reagent tank 2 heater, by the manufacturer's";
CM_ SG_ 2566731006 Aftrtrtmnt2SCRCtlystRgntTnk2Htr "The SCR catalyst reagent tank 2 heater percentage for aftertreatment system 1 (exhaust bank 1).";
CM_ SG_ 2566731006 Aftrtrtmnt2SCRRgntTnk2TmpPrlmnry "Used to identify the applicable J1939-73 FMI detected in the SCR catalyst reagent tank 2 temperature, by the";
CM_ SG_ 2566731006 Aftrtrtmnt2SCRCtlystRgntTnk2LvlP "Used to identify the applicable J1939-73 FMI detected in the SCR catalyst reagent tank 2 level, by the manufacturer's";
CM_ SG_ 2566731006 Aftrtrtmnt2SCRCtlystRgntTnk2Lvl2 "The SCR catalyst reagent tank 2 level height in mm for aftertreatment system 2 (exhaust bank 2).";
CM_ SG_ 2566731006 Aftrtrtmnt2SCRCtlystRgntTnk2Tmp "The SCR catalyst reagent tank 2 temperature for aftertreatment system 2 (exhaust bank 2).";
CM_ SG_ 2566731006 Aftrtrtmnt2SCRCtlystRgntTnk2Lvl "The SCR catalyst reagent tank 2 level percentage for aftertreatment system 2 (exhaust bank 2).";
CM_ BO_ 2566731262 "Aftertreatment 2 SCR Reagant Tank 1 Information";
CM_ SG_ 2566731262 Aftrtrtmnt2SCRCtlystRgntTnk1HtrP "Used to identify the applicable J1939-73 FMI detected in the SCR catalyst reagent tank 1 heater, by the manufacturer's";
CM_ SG_ 2566731262 Aftrtrtmnt2SCRCtalystTankHeater "Percentage of heating applied to the aftertreatment 2 catalyst tank heater.";
CM_ SG_ 2566731262 Aftrtrtmnt2SCRCtlystRgntTnk1TmpP "Used to identify the applicable J1939-73 FMI detected in the SCR catalyst reagent tank 1 temperature, by the";
CM_ SG_ 2566731262 Aftrtrtmnt2SCRCtlystTnkLvlPrlmnr "Used to identify the applicable J1939-73 FMI that applies to the most significant failure of the catalyst tank level sensor.";
CM_ SG_ 2566731262 Aftrtrtmnt2SCRCtalystTankLevel2 "The measure of the reagent level in the catalyst tank.";
CM_ SG_ 2566731262 Aftrtrtment2SCRCatalystTankTemp "Temperature of the reagent in the storage tank.";
CM_ SG_ 2566731262 Aftrtrtmnt2SCRCatalystTankLevel "A special catalyst uses chemical substance to reach legal requirement for NOX emissions.";
CM_ BO_ 2566730750 "Aftertreatment 2 SCR Reagent Supply Information";
CM_ SG_ 2566730750 Aftrtrtmnt2SCRCtlystRgntTnkDrnVl "Commanded percentage of maximum Aftertreatment 2 SCR Catalyst Reagent Tank Drain Valve opening.";
CM_ SG_ 2566730750 Aftrtrtmnt2SCRCtlystRgntPmpStte "State of aftertreatment 2 SCR Catalyst Reagent dosing pump.";
CM_ SG_ 2566730750 Aftrtrtmnt2SCRCtlystRgntTnkFllVl "Commanded percentage of maximum Aftertreatment 2 SCR Catalyst Reagent Tank Fill Valve opening.";
CM_ SG_ 2566730750 Aftrtrtmnt2SCRCtlystRgntRtrnVlv "Command to the valve which determines whether the reagent is delivered to the injector or is routed back to the reagent";
CM_ SG_ 2566730750 Aftrtrtmnt2SCRCtlystRgntPmpDrvPr "The percent (command) sent to the motor to control the speed of the reagent pump.";
CM_ SG_ 2566730750 Aftrtrtmnt2SCRCtlystRgntPmpMtrSp "Rotational speed of the motor driving a pump for reagent used in an aftertreatment system.";
CM_ BO_ 2566731518 "Aftertreatment 2 SCR Reagent Information";
CM_ SG_ 2566731518 Aftrtrtmnt2SCRCtlystReagentType "This parameter indicates what reagent is in the tank.";
CM_ SG_ 2566731518 Aftrtrtmnt2SCRCtlystRgntPrprtsPr "Used to identify the applicable J1939-73 FMI that applies to the most significant failure of the catalyst reagent properties";
CM_ SG_ 2566731518 Aftrtrtmnt2SCRCtlystRgntTmp2Prlm "Used to identify the applicable J1939-73 FMI that applies to the most significant failure of the catalyst temperature sensor.";
CM_ SG_ 2566731518 Aftrtrtmnt2SCRCtlystRgntCndctvty "A measure of the conductivity of the reagent or fluid at the sensor.";
CM_ SG_ 2566731518 Aftrtrtmnt2SCRCtlystRgntCncntrtn "A measure of the concentration of urea in water.";
CM_ SG_ 2566731518 Aftrtrtmnt2SCRCtlystRagentTemp2 "Temperature of the catalyst reagent at the device measuring reagent quality";
CM_ BO_ 2566732030 "Aftertreatment 2 SCR Exhaust Gas Temperature";
CM_ SG_ 2566732030 Aftrtrtmnt2SCRCtlystOtltGsTmpPrl "Used to identify the applicable J1939-73 FMI detected in the SCR catalyst outlet gas temperature sensor by the";
CM_ SG_ 2566732030 Aftrtrtmnt2SCRCtlystOtltGasTemp "Temperature of engine combustion byproducts leaving the SCR catalyst exhaust in exhaust bank 2.";
CM_ SG_ 2566732030 Aftrtrtmnt2SCRCtlystIntkGsTmpPrl "Used to identify the applicable J1939-73 FMI detected in the SCR catalyst intake gas temperature sensor by the";
CM_ SG_ 2566732030 Aftrtrtmnt2SCRCtlystIntkGasTemp "Temperature of engine combustion byproducts entering the SCR catalyst in exhaust bank 2.";
CM_ BO_ 2566732286 "Aftertreatment 2 SCR Exhaust Gas Pressures";
CM_ SG_ 2566732286 Aftrtrtmnt2SCRCtlystExhstGsDffPr "Used to identify the applicable J1939-73 FMI detected in the SCR catalyst differential pressure sensor by the";
CM_ SG_ 2566732286 Aftrtrtmnt2SCRCtlystExhstGs_0000 "Exhaust differential pressure measured between the intake and exhaust of a SCR catalyst in exhaust bank 2.";
CM_ BO_ 2164079358 "Aftertreatment 2 SCR Dosing System Requests 2";
CM_ SG_ 2164079358 Aftrtrtmnt2SCRCtlystTnk2HterCmd "This is the command for the Aftertreatment 2 SCR Catalyst Tank 2 Heater.";
CM_ SG_ 2164079358 Aftrtrtmnt2SCRCtlystTnkHaterCmd "Command for the Aftertreatment 2 SCR Catalyst Tank Heater.";
CM_ SG_ 2164079358 Aftrtrtmnt2SCRCtlystRgntLnHter4 "The SCR catalyst reagent line heater 4 request for aftertreatment system 2 (exhaust bank 2).";
CM_ SG_ 2164079358 Aftrtrtmnt2SCRCtlystRgntLnHter3 "The SCR catalyst reagent line heater 3 request for aftertreatment system 2 (exhaust bank 2).";
CM_ SG_ 2164079358 Aftrtrtmnt2SCRCtlystRgntLnHter2 "The SCR catalyst reagent line heater 2 request for aftertreatment system 2 (exhaust bank 2).";
CM_ SG_ 2164079358 Aftrtrtmnt2SCRCtlystRgntLnHter1 "The SCR catalyst reagent line heater 1 request for aftertreatment system 2 (exhaust bank 2).";
CM_ SG_ 2164079358 Aftrtrtmnt2SCRDserHeatingModeRq "Used if multiple heater modes are available in the Doser.";
CM_ SG_ 2164079358 Aftrtrtmnt2SCRDsrFltSpprssionRq "Used if external devices can warn of conditions that require suppression of potential faults in the doser due to";
CM_ BO_ 2364549118 "Aftertreatment 2 SCR Dosing System Requests 1";
CM_ SG_ 2364549118 Aftrtrtmnt2SCRRqdRgntQnttyFrIntg "Represents the command for the reducing agent quantity integrator in the dosing control unit";
CM_ SG_ 2364549118 Aftrtratment2SCRSystemRqedState "Requested state of SCR system for aftertreatment system 2 (exhaust bank 2).";
CM_ SG_ 2364549118 Aftrtrtmnt2SCRRqdDsngRgntQntity "Actual requested dosing quantity of catalyst reagent";
CM_ BO_ 2566732798 "Aftertreatment 2 SCR Dosing System Information 2";
CM_ SG_ 2566732798 Aftrtrtmnt2SCRCtlystRgntLnHtr4Pr "Used to identify the applicable J1939-73 FMI detected in the SCR catalyst reagent line heater 4, by the manufacturer's";
CM_ SG_ 2566732798 Aftrtrtmnt2SCRCtlystRgntLnHtr4St "The SCR catalyst reagent line heater 4 state for aftertreatment system 2 (exhaust bank 2).";
CM_ SG_ 2566732798 Aftrtrtmnt2SCRCtlystRgntLnHtr3Pr "Used to identify the applicable J1939-73 FMI detected in the SCR catalyst reagent line heater 3, by the manufacturer's";
CM_ SG_ 2566732798 Aftrtrtmnt2SCRCtlystRgntLnHtr3St "The SCR catalyst reagent line heater 3 state for aftertreatment system 2 (exhaust bank 2).";
CM_ SG_ 2566732798 Aftrtrtmnt2SCRCtlystRgntLnHtr2Pr "Used to identify the applicable J1939-73 FMI detected in the SCR catalyst reagent line heater 2, by the manufacturer's";
CM_ SG_ 2566732798 Aftrtrtmnt2SCRCtlystRgntLnHtr2St "The SCR catalyst reagent line heater 2 state for aftertreatment system 2 (exhaust bank 2).";
CM_ SG_ 2566732798 Aftrtrtmnt2SCRCtlystRgntLnHtr1Pr "Used to identify the applicable J1939-73 FMI detected in the SCR catalyst reagent line heater 1, by the manufacturer's";
CM_ SG_ 2566732798 Aftrtrtmnt2SCRCtlystRgntLnHtr1St "The SCR catalyst reagent line heater 1 state for aftertreatment system 2 (exhaust bank 2).";
CM_ SG_ 2566732798 Aftrtrtmnt2SCRFedbackCtrlStatus "The SCR feedback control status (open/closed loop) for aftertreatment system 2 (exhaust bank 2).";
CM_ SG_ 2566732798 Aftrtrtmnt2SCRDsngVlvExhstTmpRdc "Protection request for the dosing valve of the SCR-system to prevent overheating";
CM_ SG_ 2566732798 Aftrtrtmnt2SCRDosingReagentTemp "The SCR dosing reagent temperature (measured closest to dosing valve) for aftertreatment system 2 (exhaust bank 2).";
CM_ SG_ 2566732798 Aftrtrtmnt2SCRDsngArAssistValve "The position of the valve used to regulate the air supply of an air assist SCR dosing system for an engine.";
CM_ SG_ 2566732798 Aftrtrtmnt2SCRDsngArAssstAbsPrss "The SCR dosing system air assist absolute pressure for aftertreatment system 2 (exhaust bank 2).";
CM_ BO_ 2364548862 "Aftertreatment 2 SCR Dosing System Information 1";
CM_ SG_ 2364548862 Aftrtrtmnt2SCRDsngRgentAbsPress "The SCR dosing reagent absolute pressure (measured closest to dosing valve) for aftertreatment system 2 (exhaust bank";
CM_ SG_ 2364548862 Aftrtrtmnt2SCRActlRgntQnttyOfInt "The SCR requested reagent integrator total quantity for aftertreatment system 2 (exhaust bank 2).";
CM_ SG_ 2364548862 Aftertreatment2SCRSystemState "Actual state of SCR system";
CM_ SG_ 2364548862 Aftrtrtmnt2SCRActlDsngRgntQntty "Actual reducing agent quantity of SCR system.";
CM_ BO_ 2364549374 "Aftertreatment 2 SCR Ammonia Information";
CM_ SG_ 2364549374 Aftrtrtmnt2OtltNH3GsSnsrHtrCtrl "Indicates the heater status in the warm-up process.";
CM_ SG_ 2364549374 Aftrtrtmnt2OtltNH3GsSnsrHtrPrlmn "Used to identify the applicable J1939-73 FMI detected in the heater of the outlet NH3 exhaust gas sensor by the";
CM_ SG_ 2364549374 Aftrtrtmnt2OtltNH3GsSnsorAtTemp "Indicates that the heater element of the aftertreatment outlet NH3 gas sensor is within the manufacturer's specified range";
CM_ SG_ 2364549374 Aftrtrtmnt2OtltNH3GsSnsrPwrInRng "Indicates that the power supplied to the aftertreatment outlet NH3 gas sensor is within the manufacturer's specification in";
CM_ SG_ 2364549374 Aftrtrtmnt2OtltNH3ReadingStable "Indicates that the NH3 reading of the aftertreatment outlet NH3 sensor is stable as determined by the manufacturer's";
CM_ SG_ 2364549374 Aftrtrtmnt2OtltNH3SnsrPrlmnryFMI "Used to identify the applicable J1939-73 FMI detected in the aftertreatment outlet NH3 sensor by the manufacturer's";
CM_ SG_ 2364549374 Aftertreatment2OutletNH3 "The amount of NH3 in the exhaust exiting the aftertreatment system measured by a NH3 sensor at the aftertreatment";
CM_ BO_ 2566726142 "Aftertreatment 2 Gas Oxidation Catalyst";
CM_ SG_ 2566726142 Aftrtrtmnt2GsOxdtnCtlystDffPrssP "Used to identify the applicable J1939-73 FMI detected in the gas oxidation catalyst differential pressure sensor by the";
CM_ SG_ 2566726142 Aftrtrtmnt2GsOxdtnCtlystOtltGsTm "Used to identify the applicable J1939-73 FMI detected in the gas oxidation catalyst outlet gas temperature sensor by the";
CM_ SG_ 2566726142 Aftrtrtmnt2GsOxdtnCtlystIntkGsTm "Used to identify the applicable J1939-73 FMI detected in the gas oxidation catalyst intake gas temperature sensor by the";
CM_ SG_ 2566726142 Aftrtrtmnt2GsOxdtnCtlystDffPrss "Exhaust differential pressure measured between the intake and exhaust of the gas oxidation catalyst in exhaust bank 2.";
CM_ SG_ 2566726142 Aftrtrtmnt2GsOxdtnCtlystOtl_0000 "Temperature of engine combustion byproducts leaving the gas oxidation catalyst in exhaust bank 2.";
CM_ SG_ 2566726142 Aftrtrtmnt2GsOxdtnCtlystInt_0000 "Temperature of engine combustion byproducts entering the gas oxidation catalyst in exhaust bank 2.";
CM_ BO_ 2566725630 "Aftertreatment 2 Diesel Oxidation Catalyst";
CM_ SG_ 2566725630 Aftrtrtmnt2DslOxdtnCtlystOtltGsT "Used to identify the applicable J1939-73 FMI detected in the diesel oxidation catalyst outlet gas temperature sensor by";
CM_ SG_ 2566725630 Aftrtrtmnt2DslOxdtnCtlystIntkGsT "Used to identify the applicable J1939-73 FMI detected in the diesel oxidation catalyst intake gas temperature sensor by";
CM_ SG_ 2566725630 Aftrtrtmnt2DslOxdtnCtlystDffPrss "Exhaust differential pressure measured between the intake and exhaust of a diesel oxidation catalyst in exhaust bank 2.";
CM_ SG_ 2566725630 Aftrtrtmnt2DslOxdtnCtlystOt_0000 "Temperature of engine combustion byproducts leaving the diesel oxidation catalyst exhaust in exhaust bank 2.";
CM_ SG_ 2566725630 Aftrtrtmnt2DslOxdtnCtlystIn_0000 "Temperature of engine combustion byproducts entering the diesel oxidation catalyst in exhaust bank 2.";
CM_ SG_ 2566725630 Aftrtrtmnt2DslOxdtnCtlystDf_0000 "Used to identify the applicable J1939-73 FMI detected in the diesel oxidation catalyst differential pressure sensor by the";
CM_ BO_ 2566733310 "Aftertreatment 1 SCR Reagant Tank 2 Information";
CM_ SG_ 2566733310 Aftrtrtmnt1SCRCtlystRgntTnk2HtrP "Used to identify the applicable J1939-73 FMI detected in the SCR catalyst reagent tank 2 heater, by the manufacturer's";
CM_ SG_ 2566733310 Aftrtrtmnt1SCRCtlystRgntTnk2Htr "The SCR catalyst reagent tank 2 heater percentage for aftertreatment system 1 (exhaust bank 1).";
CM_ SG_ 2566733310 Aftrtrtmnt1SCRRgntTnk2TmpPrlmnry "Used to identify the applicable J1939-73 FMI detected in the SCR catalyst reagent tank 2 temperature, by the";
CM_ SG_ 2566733310 Aftrtrtmnt1SCRCtlystRgntTnk2LvlP "Used to identify the applicable J1939-73 FMI detected in the SCR catalyst reagent tank 2 level, by the manufacturer's";
CM_ SG_ 2566733310 Aftrtrtmnt1SCRCtlystRgntTnk2Lvl2 "The SCR catalyst reagent tank 2 level height in mm for aftertreatment system 1 (exhaust bank 1).";
CM_ SG_ 2566733310 Aftrtrtmnt1SCRCtlystRgntTnk2Tmp "The SCR catalyst reagent tank 2 temperature for aftertreatment system 1 (exhaust bank 1).";
CM_ SG_ 2566733310 Aftrtrtmnt1SCRCtlystRgntTnk2Lvl "The SCR catalyst reagent tank 2 level percentage for aftertreatment system 1 (exhaust bank 1).";
CM_ BO_ 2566733054 "Aftertreatment 1 SCR Reagent Supply Information";
CM_ SG_ 2566733054 Aftrtrtmnt1SCRCtlystRgntTnkDrnVl "Commanded percentage of maximum Aftertreatment 1 SCR Catalyst Reagent Tank Drain Valve opening.";
CM_ SG_ 2566733054 Aftrtrtmnt1SCRCtlystRgntPmpStte "State of aftertreatment 1 SCR Catalyst Reagent dosing pump.";
CM_ SG_ 2566733054 Aftrtrtmnt1SCRCtlystRgntTnkFllVl "Commanded percentage of maximum Aftertreatment 1 SCR Catalyst Reagent Tank Fill Valve opening.";
CM_ SG_ 2566733054 Aftrtrtmnt1SCRCtlystRgntRtrnVlv "Command to the valve which determines whether the reagent is delivered to the injector or is routed back to the reagent";
CM_ SG_ 2566733054 Aftrtrtmnt1SCRCtlystRgntPmpDrvPr "The percent (command) sent to the motor to control the speed of the reagent pump.";
CM_ SG_ 2566733054 Aftrtrtmnt1SCRCtlystRgntPmpMtrSp "Rotational speed of the motor driving a pump for reagent used in an aftertreatment system.";
CM_ BO_ 2499624702 "Aftertreatment 1 SCR Exhaust Gas Temperature";
CM_ SG_ 2499624702 Aftrtrtmnt1SCRCtlystOtltGsTmpPrl "Used to identify the applicable J1939-73 FMI detected in the SCR catalyst outlet gas temperature sensor by the";
CM_ SG_ 2499624702 Aftrtrtmnt1SCRCtlystOtltGasTemp "Temperature of engine combustion byproducts leaving the SCR catalyst exhaust in exhaust bank 1.";
CM_ SG_ 2499624702 Aftrtrtmnt1SCRCtlystIntkGsTmpPrl "Used to identify the applicable J1939-73 FMI detected in the SCR catalyst intake gas temperature sensor by the";
CM_ SG_ 2499624702 Aftrtrtmnt1SCRCtlystIntkGasTemp "Temperature of engine combustion byproducts entering the SCR catalyst in exhaust bank 1.";
CM_ BO_ 2566733822 "Aftertreatment 1 SCR Exhaust Gas Pressures";
CM_ SG_ 2566733822 Aftrtrtmnt1SCRCtlystExhstGsDffPr "Used to identify the applicable J1939-73 FMI detected in the SCR catalyst differential pressure sensor by the";
CM_ SG_ 2566733822 Aftrtrtmnt1SCRCtlystExhstGs_0000 "Exhaust differential pressure measured between the intake and exhaust of a SCR catalyst in exhaust bank 1.";
CM_ BO_ 2566734078 "Aftertreatment 1 SCR Dosing System Requests 2";
CM_ SG_ 2566734078 Aftrtrtmnt1SCRCtlystTnk2HterCmd "This is the command for the Aftertreatment 1 SCR Catalyst Tank 2 Heater.";
CM_ SG_ 2566734078 Aftrtrtmnt1SCRCtlystTnkHaterCmd "Command for the Aftertreatment 1 SCR Catalyst Tank Heater.";
CM_ SG_ 2566734078 Aftrtrtmnt1SCRCtlystRgntLnHter4 "The SCR catalyst reagent line heater 4 request for aftertreatment system 1 (exhaust bank 1).";
CM_ SG_ 2566734078 Aftrtrtmnt1SCRCtlystRgntLnHter3 "The SCR catalyst reagent line heater 3 request for aftertreatment system 1 (exhaust bank 1).";
CM_ SG_ 2566734078 Aftrtrtmnt1SCRCtlystRgntLnHter2 "The SCR catalyst reagent line heater 2 request for aftertreatment system 1 (exhaust bank 1).";
CM_ SG_ 2566734078 Aftrtrtmnt1SCRCtlystRgntLnHter1 "The SCR catalyst reagent line heater 1 request for aftertreatment system 1 (exhaust bank 1).";
CM_ SG_ 2566734078 Aftrtrtmnt1SCRDserHeatingModeRq "Used if multiple heater modes are available in the Doser.";
CM_ SG_ 2566734078 Aftrtrtmnt1SCRDsrFltSpprssionRq "Used if external devices can warn of conditions that require suppression of potential faults in the doser due to";
CM_ BO_ 2364548350 "Aftertreatment 1 SCR Dosing System Requests 1";
CM_ SG_ 2364548350 Aftrtrtmnt1SCRRqdRgntQnttyFrIntg "Represents the command for the reducing agent quantity integrator in the dosing control unit";
CM_ SG_ 2364548350 Aftrtratment1SCRSystemRqedState "Requested state of SCR system for aftertreatment system 1 (exhaust bank 1).";
CM_ SG_ 2364548350 Aftrtrtmnt1SCRRqdDsngRgntQntity "Actual requested dosing quantity of catalyst reagent";
CM_ BO_ 2566734334 "Aftertreatment 1 SCR Dosing System Information 2";
CM_ SG_ 2566734334 Aftrtrtmnt1SCRCtlystRgntLnHtr4Pr "Used to identify the applicable J1939-73 FMI detected in the SCR catalyst reagent line heater 4, by the manufacturer's";
CM_ SG_ 2566734334 Aftrtrtmnt1SCRCtlystRgntLnHtr4St "The SCR catalyst reagent line heater 4 state for aftertreatment system 1 (exhaust bank 1).";
CM_ SG_ 2566734334 Aftrtrtmnt1SCRCtlystRgntLnHtr3Pr "Used to identify the applicable J1939-73 FMI detected in the SCR catalyst reagent line heater 3, by the manufacturer's";
CM_ SG_ 2566734334 Aftrtrtmnt1SCRCtlystRgntLnHtr3St "The SCR catalyst reagent line heater 3 state for aftertreatment system 1 (exhaust bank 1).";
CM_ SG_ 2566734334 Aftrtrtmnt1SCRCtlystRgntLnHtr2Pr "Used to identify the applicable J1939-73 FMI detected in the SCR catalyst reagent line heater 2, by the manufacturer's";
CM_ SG_ 2566734334 Aftrtrtmnt1SCRCtlystRgntLnHtr2St "The SCR catalyst reagent line heater 2 state for aftertreatment system 1 (exhaust bank 1).";
CM_ SG_ 2566734334 Aftrtrtmnt1SCRCtlystRgntLnHtr1Pr "Used to identify the applicable J1939-73 FMI detected in the SCR catalyst reagent line heater 1, by the manufacturer's";
CM_ SG_ 2566734334 Aftrtrtmnt1SCRCtlystRgntLnHtr1St "The SCR catalyst reagent line heater 1 state for aftertreatment system 1 (exhaust bank 1).";
CM_ SG_ 2566734334 Aftrtrtmnt1SCRFedbackCtrlStatus "The SCR feedback control status (open/closed loop) for aftertreatment system 1 (exhaust bank 1).";
CM_ SG_ 2566734334 Aftrtrtmnt1SCRDsngVlvExhstTmpRdc "Protection request for the dosing valve of the SCR-system to prevent overheating";
CM_ SG_ 2566734334 Aftrtrtmnt1SCRDosingReagentTemp "The SCR dosing reagent temperature (measured closest to dosing valve) for aftertreatment system 1 (exhaust bank 1).";
CM_ SG_ 2566734334 Aftrtrtmnt1SCRDsngArAssistValve "The position of the valve used to regulate the air supply of an air assist SCR dosing system for an engine.";
CM_ SG_ 2566734334 Aftrtrtmnt1SCRDsngArAssstAbsPrss "The SCR dosing system air assist absolute pressure for aftertreatment system 1 (exhaust bank 1).";
CM_ BO_ 2364548094 "Aftertreatment 1 SCR Dosing System Information 1";
CM_ SG_ 2364548094 Aftrtrtmnt1SCRDsngRgentAbsPress "The SCR dosing reagent absolute pressure (measured closest to dosing valve) for aftertreatment system 1 (exhaust bank";
CM_ SG_ 2364548094 Aftrtrtmnt1SCRActlRgntQnttyOfInt "The SCR requested reagent integrator total quantity for aftertreatment system 1 (exhaust bank 1).";
CM_ SG_ 2364548094 Aftertreatment1SCRSystemState "Actual state of SCR system";
CM_ SG_ 2364548094 Aftrtrtmnt1SCRActlDsngRgntQntty "Actual reducing agent quantity of SCR-system";
CM_ BO_ 2364548606 "Aftertreatment 1 SCR Ammonia Information";
CM_ SG_ 2364548606 Aftrtrtmnt1OtltNH3GsSnsrHtrCtrl "Indicates the heater status in the warm-up process.";
CM_ SG_ 2364548606 Aftrtrtmnt1OtltNH3GsSnsrHtrPrlmn "Used to identify the applicable J1939-73 FMI detected in the heater of the outlet NH3 exhaust gas sensor by the";
CM_ SG_ 2364548606 Aftrtrtmnt1OtltNH3GsSnsorAtTemp "Indicates that the heater element of the aftertreatment outlet NH3 gas sensor is within the manufacturer's specified range";
CM_ SG_ 2364548606 Aftrtrtmnt1OtltNH3GsSnsrPwrInRng "Indicates that the power supplied to the aftertreatment outlet NH3 gas sensor is within the manufacturer's specification in";
CM_ SG_ 2364548606 Aftrtrtmnt1OtltNH3ReadingStable "Indicates that the NH3 reading of the aftertreatment outlet NH3 sensor is stable as determined by the manufacturer's";
CM_ SG_ 2364548606 Aftrtrtmnt1OtltNH3SnsrPrlmnryFMI "Used to identify the applicable J1939-73 FMI detected in the aftertreatment outlet NH3 sensor by the manufacturer's";
CM_ SG_ 2364548606 Aftertreatment1OutletNH3 "The amount of NH3 in the exhaust exiting the aftertreatment system measured by a NH3 sensor at the aftertreatment";
CM_ BO_ 2566726398 "Aftertreatment 1 Gas Oxidation Catalyst";
CM_ SG_ 2566726398 Aftrtrtmnt1GsOxdtnCtlystDffPrssP "Used to identify the applicable J1939-73 FMI detected in the gas oxidation catalyst differential pressure sensor by the";
CM_ SG_ 2566726398 Aftrtrtmnt1GsOxdtnCtlystOtltGsTm "Used to identify the applicable J1939-73 FMI detected in the gas oxidation catalyst outlet gas temperature sensor by the";
CM_ SG_ 2566726398 Aftrtrtmnt1GsOxdtnCtlystIntkGsTm "Used to identify the applicable J1939-73 FMI detected in the gas oxidation catalyst intake gas temperature sensor by the";
CM_ SG_ 2566726398 Aftrtrtmnt1GsOxdtnCtlystDffPrss "Exhaust differential pressure measured between the intake and exhaust of the gas oxidation catalyst in exhaust bank 1.";
CM_ SG_ 2566726398 Aftrtrtmnt1GsOxdtnCtlystOtl_0000 "Temperature of engine combustion byproducts leaving the gas oxidation catalyst in exhaust bank 1.";
CM_ SG_ 2566726398 Aftrtrtmnt1GsOxdtnCtlystInt_0000 "Temperature of engine combustion byproducts entering the gas oxidation catalyst in exhaust bank 1.";
BA_DEF_ SG_ "SigType" ENUM "Default","Range","RangeSigned","ASCII","Discrete","Control","ReferencePGN","DTC","StringDelimiter","StringLength","StringLengthControl";
BA_DEF_ SG_ "GenSigStartValue" INT 0 10000;
BA_DEF_ SG_ "GenSigSendType" ENUM "Default","Range","RangeSigned","ASCII","Discrete","Control","ReferencePGN","DTC","StringDelimiter","StringLength","StringLengthControl","Cyclic","OnWrite","reserved","OnChange","reserved","reserved","reserved","NoSigSendType";
BA_DEF_ SG_ "GenSigILSupport" ENUM "Default","Range","RangeSigned","ASCII","Discrete","Control","ReferencePGN","DTC","StringDelimiter","StringLength","StringLengthControl","Cyclic","OnWrite","reserved","OnChange","reserved","reserved","reserved","NoSigSendType","Yes","No";
BA_DEF_ SG_ "GenSigEVName" STRING ;
BA_DEF_ SG_ "SPN" INT 0 524287;
BA_DEF_ BO_ "GenMsgStartDelayTime" INT 0 100000;
BA_DEF_ BO_ "GenMsgILSupport" ENUM "Default","Range","RangeSigned","ASCII","Discrete","Control","ReferencePGN","DTC","StringDelimiter","StringLength","StringLengthControl","Cyclic","OnWrite","reserved","OnChange","reserved","reserved","reserved","NoSigSendType","Yes","No","Yes","No";
BA_DEF_ BO_ "GenMsgRequestable" INT 0 1;
BA_DEF_ BO_ "GenMsgSendType" ENUM "Default","Range","RangeSigned","ASCII","Discrete","Control","ReferencePGN","DTC","StringDelimiter","StringLength","StringLengthControl","Cyclic","OnWrite","reserved","OnChange","reserved","reserved","reserved","NoSigSendType","Yes","No","Yes","No","cyclic","reserved","cyclicIfActive","reserved","reserved","reserved","reserved","reserved","noMsgSendType";
BA_DEF_ BO_ "VFrameFormat" ENUM "Default","Range","RangeSigned","ASCII","Discrete","Control","ReferencePGN","DTC","StringDelimiter","StringLength","StringLengthControl","Cyclic","OnWrite","reserved","OnChange","reserved","reserved","reserved","NoSigSendType","Yes","No","Yes","No","cyclic","reserved","cyclicIfActive","reserved","reserved","reserved","reserved","reserved","noMsgSendType","StandardCAN","ExtendedCAN","reserved","J1939PG";
BA_DEF_ BO_ "GenMsgCycleTime" INT 0 3.6e+06;
BA_DEF_ SG_ "SystemSignalLongSymbol" STRING ;
BA_DEF_ BO_ "GenMsgBackgroundColor" STRING ;
BA_DEF_ BO_ "GenMsgForegroundColor" STRING ;
BA_DEF_ BO_ "matchingcriteria" INT 0 0;
BA_DEF_ BO_ "filterlabeling" INT 0 0;
BA_DEF_DEF_ "SigType" "Default";
BA_DEF_DEF_ "GenSigStartValue" 0;
BA_DEF_DEF_ "GenSigSendType" "NoSigSendType";
BA_DEF_DEF_ "GenSigILSupport" "Yes";
BA_DEF_DEF_ "GenSigEVName" "Env";
BA_DEF_DEF_ "SPN" 0;
BA_DEF_DEF_ "GenMsgStartDelayTime" 0;
BA_DEF_DEF_ "GenMsgILSupport" "Yes";
BA_DEF_DEF_ "GenMsgRequestable" 1;
BA_DEF_DEF_ "GenMsgSendType" "noMsgSendType";
BA_DEF_DEF_ "VFrameFormat" "J1939PG";
BA_DEF_DEF_ "GenMsgCycleTime" 0;
BA_DEF_DEF_ "SystemSignalLongSymbol" "";
BA_DEF_DEF_ "GenMsgBackgroundColor" "#ffffff";
BA_DEF_DEF_ "GenMsgForegroundColor" "#000000";
BA_DEF_DEF_ "matchingcriteria" 1;
BA_DEF_DEF_ "filterlabeling" 1;
BA_ "GenMsgCycleTime" BO_ 2565865982 100;
BA_ "GenMsgSendType" BO_ 2565865982 0;
BA_ "VFrameFormat" BO_ 2565865982 3;
BA_ "GenMsgCycleTime" BO_ 2565867262 500;
BA_ "GenMsgSendType" BO_ 2565867262 0;
BA_ "VFrameFormat" BO_ 2565867262 3;
BA_ "GenMsgCycleTime" BO_ 2566821118 500;
BA_ "GenMsgSendType" BO_ 2566821118 0;
BA_ "VFrameFormat" BO_ 2566821118 3;
BA_ "GenMsgSendType" BO_ 2566810622 8;
BA_ "VFrameFormat" BO_ 2566810622 3;
BA_ "GenMsgCycleTime" BO_ 2566847742 1000;
BA_ "GenMsgSendType" BO_ 2566847742 0;
BA_ "VFrameFormat" BO_ 2566847742 3;
BA_ "GenMsgSendType" BO_ 2566768382 8;
BA_ "VFrameFormat" BO_ 2566768382 3;
BA_ "GenMsgSendType" BO_ 2566811902 8;
BA_ "VFrameFormat" BO_ 2566811902 3;
BA_ "GenMsgCycleTime" BO_ 2563768062 5000;
BA_ "GenMsgSendType" BO_ 2563768062 0;
BA_ "VFrameFormat" BO_ 2563768062 3;
BA_ "GenMsgSendType" BO_ 2633924862 8;
BA_ "VFrameFormat" BO_ 2633924862 3;
BA_ "GenMsgSendType" BO_ 2633924606 8;
BA_ "VFrameFormat" BO_ 2633924606 3;
BA_ "GenMsgSendType" BO_ 2633924350 8;
BA_ "VFrameFormat" BO_ 2633924350 3;
BA_ "GenMsgSendType" BO_ 2633924094 8;
BA_ "VFrameFormat" BO_ 2633924094 3;
BA_ "GenMsgSendType" BO_ 2633923838 8;
BA_ "VFrameFormat" BO_ 2633923838 3;
BA_ "GenMsgSendType" BO_ 2633923582 8;
BA_ "VFrameFormat" BO_ 2633923582 3;
BA_ "GenMsgSendType" BO_ 2633878014 8;
BA_ "VFrameFormat" BO_ 2633878014 3;
BA_ "GenMsgSendType" BO_ 2566771966 8;
BA_ "VFrameFormat" BO_ 2566771966 3;
BA_ "GenMsgCycleTime" BO_ 2564882174 1000;
BA_ "GenMsgSendType" BO_ 2564882174 0;
BA_ "VFrameFormat" BO_ 2564882174 3;
BA_ "GenMsgSendType" BO_ 2563833598 8;
BA_ "VFrameFormat" BO_ 2563833598 3;
BA_ "GenMsgSendType" BO_ 2566843390 8;
BA_ "VFrameFormat" BO_ 2566843390 3;
BA_ "GenMsgCycleTime" BO_ 2566844926 100;
BA_ "GenMsgSendType" BO_ 2566844926 0;
BA_ "VFrameFormat" BO_ 2566844926 3;
BA_ "GenMsgSendType" BO_ 2566843902 8;
BA_ "VFrameFormat" BO_ 2566843902 3;
BA_ "GenMsgSendType" BO_ 2566809598 8;
BA_ "VFrameFormat" BO_ 2566809598 3;
BA_ "GenMsgSendType" BO_ 2633940222 8;
BA_ "VFrameFormat" BO_ 2633940222 3;
BA_ "GenMsgCycleTime" BO_ 2566775294 1000;
BA_ "GenMsgSendType" BO_ 2566775294 0;
BA_ "VFrameFormat" BO_ 2566775294 3;
BA_ "GenMsgCycleTime" BO_ 2566803710 1000;
BA_ "GenMsgSendType" BO_ 2566803710 0;
BA_ "VFrameFormat" BO_ 2566803710 3;
BA_ "VFrameFormat" BO_ 2566719486 3;
BA_ "VFrameFormat" BO_ 2633832702 3;
BA_ "VFrameFormat" BO_ 2163223550 3;
BA_ "GenMsgCycleTime" BO_ 2566714878 1000;
BA_ "GenMsgSendType" BO_ 2566714878 0;
BA_ "VFrameFormat" BO_ 2566714878 3;
BA_ "GenMsgCycleTime" BO_ 2566714622 1000;
BA_ "GenMsgSendType" BO_ 2566714622 0;
BA_ "VFrameFormat" BO_ 2566714622 3;
BA_ "GenMsgCycleTime" BO_ 2566715390 1000;
BA_ "GenMsgSendType" BO_ 2566715390 0;
BA_ "VFrameFormat" BO_ 2566715390 3;
BA_ "GenMsgCycleTime" BO_ 2566715134 1000;
BA_ "GenMsgSendType" BO_ 2566715134 0;
BA_ "VFrameFormat" BO_ 2566715134 3;
BA_ "VFrameFormat" BO_ 2365400830 3;
BA_ "VFrameFormat" BO_ 2365401342 3;
BA_ "VFrameFormat" BO_ 2365401854 3;
BA_ "VFrameFormat" BO_ 2365402366 3;
BA_ "VFrameFormat" BO_ 2365402878 3;
BA_ "VFrameFormat" BO_ 2365403390 3;
BA_ "VFrameFormat" BO_ 2365400318 3;
BA_ "GenMsgCycleTime" BO_ 2499614718 250;
BA_ "GenMsgSendType" BO_ 2499614718 0;
BA_ "VFrameFormat" BO_ 2499614718 3;
BA_ "GenMsgCycleTime" BO_ 2566722814 1000;
BA_ "GenMsgSendType" BO_ 2566722814 0;
BA_ "VFrameFormat" BO_ 2566722814 3;
BA_ "GenMsgCycleTime" BO_ 2566723070 1000;
BA_ "GenMsgSendType" BO_ 2566723070 0;
BA_ "VFrameFormat" BO_ 2566723070 3;
BA_ "VFrameFormat" BO_ 2566725118 3;
BA_ "VFrameFormat" BO_ 2566725374 3;
BA_ "GenMsgCycleTime" BO_ 2566712830 500;
BA_ "GenMsgSendType" BO_ 2566712830 0;
BA_ "VFrameFormat" BO_ 2566712830 3;
BA_ "SystemSignalLongSymbol" SG_ 2566712830 Aftrtrtmnt2WrmUpDslOxdtnCtlystOt "Aftrtrtmnt2WrmUpDslOxdtnCtlystOt";
BA_ "SystemSignalLongSymbol" SG_ 2566712830 Aftrtrtmnt2WrmUpDslOxdtnCtlystIn "Aftrtrtmnt2WrmUpDslOxdtnCtlystIn";
BA_ "GenMsgCycleTime" BO_ 2566735358 500;
BA_ "GenMsgSendType" BO_ 2566735358 0;
BA_ "VFrameFormat" BO_ 2566735358 3;
BA_ "SystemSignalLongSymbol" SG_ 2566735358 Aftrtrtmnt2ThrWyCtlytcCnvrtrDffP "Aftrtrtmnt2ThrWyCtlytcCnvrtrDffP";
BA_ "SystemSignalLongSymbol" SG_ 2566735358 Aftrtrtmnt2ThrWyCtlytcCnvrtrOtlt "Aftrtrtmnt2ThrWyCtlytcCnvrtrOtlt";
BA_ "SystemSignalLongSymbol" SG_ 2566735358 Aftrtrtmnt2ThrWyCtlytcCnvrtrIntk "Aftrtrtmnt2ThrWyCtlytcCnvrtrIntk";
BA_ "SystemSignalLongSymbol" SG_ 2566735358 Aftrtrtmnt2ThrWyCtlytcCnvrt_0000 "Aftrtrtmnt2ThrWyCtlytcCnvrt_0000";
BA_ "SystemSignalLongSymbol" SG_ 2566735358 Aftrtrtmnt2ThrWyCtlytcCnvrt_0001 "Aftrtrtmnt2ThrWyCtlytcCnvrt_0001";
BA_ "SystemSignalLongSymbol" SG_ 2566735358 Aftrtrtmnt2ThrWyCtlytcCnvrt_0002 "Aftrtrtmnt2ThrWyCtlytcCnvrt_0002";
BA_ "VFrameFormat" BO_ 2365393662 3;
BA_ "SystemSignalLongSymbol" SG_ 2365393662 Aftrtrtmnt2OtltGsNOxSnsrNH3Crrct "Aftrtrtmnt2OtltGsNOxSnsrNH3Crrct";
BA_ "SystemSignalLongSymbol" SG_ 2365393662 Aftrtrtmnt2OtltGsNOxSnsrNO2Crrct "Aftrtrtmnt2OtltGsNOxSnsrNO2Crrct";
BA_ "SystemSignalLongSymbol" SG_ 2365393662 Aftrtrtmnt2OtltGsNOxSnsrCrrctnOf "Aftrtrtmnt2OtltGsNOxSnsrCrrctnOf";
BA_ "SystemSignalLongSymbol" SG_ 2365393662 Aftrtrtmnt2OtltGsNOxSnsrCrr_0000 "Aftrtrtmnt2OtltGsNOxSnsrCrr_0000";
BA_ "VFrameFormat" BO_ 2365393918 3;
BA_ "SystemSignalLongSymbol" SG_ 2365393918 Aftrtrtmnt2OtltGsNOxSnsrNwPrtDvt "Aftrtrtmnt2OtltGsNOxSnsrNwPrtDvt";
BA_ "SystemSignalLongSymbol" SG_ 2365393918 Aftrtrtmnt2OtltGsNOxSnsrNwP_0000 "Aftrtrtmnt2OtltGsNOxSnsrNwP_0000";
BA_ "VFrameFormat" BO_ 2365394174 3;
BA_ "SystemSignalLongSymbol" SG_ 2365394174 Aftrtrtmnt2IntkGsNOxSnsrNH3Crrct "Aftrtrtmnt2IntkGsNOxSnsrNH3Crrct";
BA_ "SystemSignalLongSymbol" SG_ 2365394174 Aftrtrtmnt2IntkGsNOxSnsrNO2Crrct "Aftrtrtmnt2IntkGsNOxSnsrNO2Crrct";
BA_ "SystemSignalLongSymbol" SG_ 2365394174 Aftrtrtmnt2IntkGsNOxSnsrCrrctnOf "Aftrtrtmnt2IntkGsNOxSnsrCrrctnOf";
BA_ "SystemSignalLongSymbol" SG_ 2365394174 Aftrtrtmnt2IntkGsNOxSnsrCrr_0000 "Aftrtrtmnt2IntkGsNOxSnsrCrr_0000";
BA_ "VFrameFormat" BO_ 2365394430 3;
BA_ "SystemSignalLongSymbol" SG_ 2365394430 Aftrtrtmnt2IntkGsNOxSnsrNwPrtDvt "Aftrtrtmnt2IntkGsNOxSnsrNwPrtDvt";
BA_ "SystemSignalLongSymbol" SG_ 2365394430 Aftrtrtmnt2IntkGsNOxSnsrNwP_0000 "Aftrtrtmnt2IntkGsNOxSnsrNwP_0000";
BA_ "GenMsgCycleTime" BO_ 2566735102 500;
BA_ "GenMsgSendType" BO_ 2566735102 0;
BA_ "VFrameFormat" BO_ 2566735102 3;
BA_ "VFrameFormat" BO_ 2157313790 3;
BA_ "SystemSignalLongSymbol" SG_ 2157313790 Aftrtrtmnt2DslPrtcltFltrStStndrd "Aftrtrtmnt2DslPrtcltFltrStStndrd";
BA_ "SystemSignalLongSymbol" SG_ 2157313790 Aftrtrtmnt2DslPrtcltFltrStMnClbO "Aftrtrtmnt2DslPrtcltFltrStMnClbO";
BA_ "GenMsgCycleTime" BO_ 2566724350 500;
BA_ "GenMsgSendType" BO_ 2566724350 0;
BA_ "VFrameFormat" BO_ 2566724350 3;
BA_ "SystemSignalLongSymbol" SG_ 2566724350 Aftrtrtmnt1WrmUpDslOxdtnCtlystOt "Aftrtrtmnt1WrmUpDslOxdtnCtlystOt";
BA_ "SystemSignalLongSymbol" SG_ 2566724350 Aftrtrtmnt1WrmUpDslOxdtnCtlystIn "Aftrtrtmnt1WrmUpDslOxdtnCtlystIn";
BA_ "GenMsgCycleTime" BO_ 2566735614 500;
BA_ "GenMsgSendType" BO_ 2566735614 0;
BA_ "VFrameFormat" BO_ 2566735614 3;
BA_ "SystemSignalLongSymbol" SG_ 2566735614 Aftrtrtmnt1ThrWyCtlytcCnvrtrDffP "Aftrtrtmnt1ThrWyCtlytcCnvrtrDffP";
BA_ "SystemSignalLongSymbol" SG_ 2566735614 Aftrtrtmnt1ThrWyCtlytcCnvrtrOtlt "Aftrtrtmnt1ThrWyCtlytcCnvrtrOtlt";
BA_ "SystemSignalLongSymbol" SG_ 2566735614 Aftrtrtmnt1ThrWyCtlytcCnvrtrIntk "Aftrtrtmnt1ThrWyCtlytcCnvrtrIntk";
BA_ "SystemSignalLongSymbol" SG_ 2566735614 Aftrtrtmnt1ThrWyCtlytcCnvrt_0000 "Aftrtrtmnt1ThrWyCtlytcCnvrt_0000";
BA_ "SystemSignalLongSymbol" SG_ 2566735614 Aftrtrtmnt1ThrWyCtlytcCnvrt_0001 "Aftrtrtmnt1ThrWyCtlytcCnvrt_0001";
BA_ "SystemSignalLongSymbol" SG_ 2566735614 Aftrtrtmnt1ThrWyCtlytcCnvrt_0002 "Aftrtrtmnt1ThrWyCtlytcCnvrt_0002";
BA_ "GenMsgCycleTime" BO_ 2566805246 1000;
BA_ "GenMsgSendType" BO_ 2566805246 0;
BA_ "VFrameFormat" BO_ 2566805246 3;
BA_ "SystemSignalLongSymbol" SG_ 2566805246 Aftrtrtmnt1SCRCtlystRgntTnk1HtrP "Aftrtrtmnt1SCRCtlystRgntTnk1HtrP";
BA_ "SystemSignalLongSymbol" SG_ 2566805246 Aftrtrtmnt1SCRCtlystRgntTnk1TmpP "Aftrtrtmnt1SCRCtlystRgntTnk1TmpP";
BA_ "SystemSignalLongSymbol" SG_ 2566805246 Aftrtrtmnt1SCRCtlystTnkLvlPrlmnr "Aftrtrtmnt1SCRCtlystTnkLvlPrlmnr";
BA_ "VFrameFormat" BO_ 2365394686 3;
BA_ "SystemSignalLongSymbol" SG_ 2365394686 Aftrtrtmnt1OtltGsNOxSnsrNH3Crrct "Aftrtrtmnt1OtltGsNOxSnsrNH3Crrct";
BA_ "SystemSignalLongSymbol" SG_ 2365394686 Aftrtrtmnt1OtltGsNOxSnsrNO2Crrct "Aftrtrtmnt1OtltGsNOxSnsrNO2Crrct";
BA_ "SystemSignalLongSymbol" SG_ 2365394686 Aftrtrtmnt1OtltGsNOxSnsrCrrctnOf "Aftrtrtmnt1OtltGsNOxSnsrCrrctnOf";
BA_ "SystemSignalLongSymbol" SG_ 2365394686 Aftrtrtmnt1OtltGsNOxSnsrCrr_0000 "Aftrtrtmnt1OtltGsNOxSnsrCrr_0000";
BA_ "VFrameFormat" BO_ 2365394942 3;
BA_ "SystemSignalLongSymbol" SG_ 2365394942 Aftrtrtmnt1OtltGsNOxSnsrNwPrtDvt "Aftrtrtmnt1OtltGsNOxSnsrNwPrtDvt";
BA_ "SystemSignalLongSymbol" SG_ 2365394942 Aftrtrtmnt1OtltGsNOxSnsrNwP_0000 "Aftrtrtmnt1OtltGsNOxSnsrNwP_0000";
BA_ "VFrameFormat" BO_ 2365395198 3;
BA_ "SystemSignalLongSymbol" SG_ 2365395198 Aftrtrtmnt1IntkGsNOxSnsrNH3Crrct "Aftrtrtmnt1IntkGsNOxSnsrNH3Crrct";
BA_ "SystemSignalLongSymbol" SG_ 2365395198 Aftrtrtmnt1IntkGsNOxSnsrNO2Crrct "Aftrtrtmnt1IntkGsNOxSnsrNO2Crrct";
BA_ "SystemSignalLongSymbol" SG_ 2365395198 Aftrtrtmnt1IntkGsNOxSnsrCrrctnOf "Aftrtrtmnt1IntkGsNOxSnsrCrrctnOf";
BA_ "SystemSignalLongSymbol" SG_ 2365395198 Aftrtrtmnt1IntkGsNOxSnsrCrr_0000 "Aftrtrtmnt1IntkGsNOxSnsrCrr_0000";
BA_ "VFrameFormat" BO_ 2365395454 3;
BA_ "SystemSignalLongSymbol" SG_ 2365395454 Aftrtrtmnt1IntkGsNOxSnsrNwPrtDvt "Aftrtrtmnt1IntkGsNOxSnsrNwPrtDvt";
BA_ "SystemSignalLongSymbol" SG_ 2365395454 Aftrtrtmnt1IntkGsNOxSnsrNwP_0000 "Aftrtrtmnt1IntkGsNOxSnsrNwP_0000";
BA_ "VFrameFormat" BO_ 2157248254 3;
BA_ "SystemSignalLongSymbol" SG_ 2157248254 Aftrtrtmnt1DslPrtcltFltrStStndrd "Aftrtrtmnt1DslPrtcltFltrStStndrd";
BA_ "SystemSignalLongSymbol" SG_ 2157248254 Aftrtrtmnt1DslPrtcltFltrStMnClbO "Aftrtrtmnt1DslPrtcltFltrStMnClbO";
BA_ "GenMsgCycleTime" BO_ 2566711806 100;
BA_ "GenMsgSendType" BO_ 2566711806 0;
BA_ "VFrameFormat" BO_ 2566711806 3;
BA_ "GenMsgCycleTime" BO_ 2364549886 10;
BA_ "GenMsgSendType" BO_ 2364549886 0;
BA_ "VFrameFormat" BO_ 2364549886 3;
BA_ "GenMsgCycleTime" BO_ 2566712318 1000;
BA_ "GenMsgSendType" BO_ 2566712318 0;
BA_ "VFrameFormat" BO_ 2566712318 3;
BA_ "SystemSignalLongSymbol" SG_ 2566712318 Aftrtrtmnt2NOxAdsrbrDSOxRgnrtnSt "Aftrtrtmnt2NOxAdsrbrDSOxRgnrtnSt";
BA_ "SystemSignalLongSymbol" SG_ 2566712318 Aftrtrtmnt2NOxAdsrbrDNOxRgnrtnSt "Aftrtrtmnt2NOxAdsrbrDNOxRgnrtnSt";
BA_ "GenMsgCycleTime" BO_ 2566712574 1000;
BA_ "GenMsgSendType" BO_ 2566712574 0;
BA_ "VFrameFormat" BO_ 2566712574 3;
BA_ "SystemSignalLongSymbol" SG_ 2566712574 Aftrtrtmnt1NOxAdsrbrDSOxRgnrtnSt "Aftrtrtmnt1NOxAdsrbrDSOxRgnrtnSt";
BA_ "SystemSignalLongSymbol" SG_ 2566712574 Aftrtrtmnt1NOxAdsrbrDNOxRgnrtnSt "Aftrtrtmnt1NOxAdsrbrDNOxRgnrtnSt";
BA_ "VFrameFormat" BO_ 2164078590 3;
BA_ "SystemSignalLongSymbol" SG_ 2164078590 Aftrtrtmnt2SCRCtlystCnvrsnEffcnc "Aftrtrtmnt2SCRCtlystCnvrsnEffcnc";
BA_ "SystemSignalLongSymbol" SG_ 2164078590 Aftrtrtmnt2SCRCmddCtlystRgntCnsm "Aftrtrtmnt2SCRCmddCtlystRgntCnsm";
BA_ "SystemSignalLongSymbol" SG_ 2164078590 Aftrtrtmnt2SCRAvrgCtlystRgntCnsm "Aftrtrtmnt2SCRAvrgCtlystRgntCnsm";
BA_ "GenMsgCycleTime" BO_ 2566731006 1000;
BA_ "GenMsgSendType" BO_ 2566731006 0;
BA_ "VFrameFormat" BO_ 2566731006 3;
BA_ "SystemSignalLongSymbol" SG_ 2566731006 Aftrtrtmnt2SCRCtlystRgntTnk2HtrP "Aftrtrtmnt2SCRCtlystRgntTnk2HtrP";
BA_ "SystemSignalLongSymbol" SG_ 2566731006 Aftrtrtmnt2SCRRgntTnk2TmpPrlmnry "Aftrtrtmnt2SCRRgntTnk2TmpPrlmnry";
BA_ "SystemSignalLongSymbol" SG_ 2566731006 Aftrtrtmnt2SCRCtlystRgntTnk2LvlP "Aftrtrtmnt2SCRCtlystRgntTnk2LvlP";
BA_ "GenMsgCycleTime" BO_ 2566731262 1000;
BA_ "GenMsgSendType" BO_ 2566731262 0;
BA_ "VFrameFormat" BO_ 2566731262 3;
BA_ "SystemSignalLongSymbol" SG_ 2566731262 Aftrtrtmnt2SCRCtlystRgntTnk1HtrP "Aftrtrtmnt2SCRCtlystRgntTnk1HtrP";
BA_ "SystemSignalLongSymbol" SG_ 2566731262 Aftrtrtmnt2SCRCtlystRgntTnk1TmpP "Aftrtrtmnt2SCRCtlystRgntTnk1TmpP";
BA_ "SystemSignalLongSymbol" SG_ 2566731262 Aftrtrtmnt2SCRCtlystTnkLvlPrlmnr "Aftrtrtmnt2SCRCtlystTnkLvlPrlmnr";
BA_ "GenMsgCycleTime" BO_ 2566730750 1000;
BA_ "GenMsgSendType" BO_ 2566730750 0;
BA_ "VFrameFormat" BO_ 2566730750 3;
BA_ "SystemSignalLongSymbol" SG_ 2566730750 Aftrtrtmnt2SCRCtlystRgntTnkDrnVl "Aftrtrtmnt2SCRCtlystRgntTnkDrnVl";
BA_ "SystemSignalLongSymbol" SG_ 2566730750 Aftrtrtmnt2SCRCtlystRgntTnkFllVl "Aftrtrtmnt2SCRCtlystRgntTnkFllVl";
BA_ "SystemSignalLongSymbol" SG_ 2566730750 Aftrtrtmnt2SCRCtlystRgntPmpDrvPr "Aftrtrtmnt2SCRCtlystRgntPmpDrvPr";
BA_ "SystemSignalLongSymbol" SG_ 2566730750 Aftrtrtmnt2SCRCtlystRgntPmpMtrSp "Aftrtrtmnt2SCRCtlystRgntPmpMtrSp";
BA_ "GenMsgCycleTime" BO_ 2566731518 1000;
BA_ "GenMsgSendType" BO_ 2566731518 0;
BA_ "VFrameFormat" BO_ 2566731518 3;
BA_ "SystemSignalLongSymbol" SG_ 2566731518 Aftrtrtmnt2SCRCtlystRgntPrprtsPr "Aftrtrtmnt2SCRCtlystRgntPrprtsPr";
BA_ "SystemSignalLongSymbol" SG_ 2566731518 Aftrtrtmnt2SCRCtlystRgntTmp2Prlm "Aftrtrtmnt2SCRCtlystRgntTmp2Prlm";
BA_ "GenMsgCycleTime" BO_ 2566732030 500;
BA_ "GenMsgSendType" BO_ 2566732030 0;
BA_ "VFrameFormat" BO_ 2566732030 3;
BA_ "SystemSignalLongSymbol" SG_ 2566732030 Aftrtrtmnt2SCRCtlystOtltGsTmpPrl "Aftrtrtmnt2SCRCtlystOtltGsTmpPrl";
BA_ "SystemSignalLongSymbol" SG_ 2566732030 Aftrtrtmnt2SCRCtlystIntkGsTmpPrl "Aftrtrtmnt2SCRCtlystIntkGsTmpPrl";
BA_ "GenMsgCycleTime" BO_ 2566732286 500;
BA_ "GenMsgSendType" BO_ 2566732286 0;
BA_ "VFrameFormat" BO_ 2566732286 3;
BA_ "SystemSignalLongSymbol" SG_ 2566732286 Aftrtrtmnt2SCRCtlystExhstGsDffPr "Aftrtrtmnt2SCRCtlystExhstGsDffPr";
BA_ "SystemSignalLongSymbol" SG_ 2566732286 Aftrtrtmnt2SCRCtlystExhstGs_0000 "Aftrtrtmnt2SCRCtlystExhstGs_0000";
BA_ "GenMsgCycleTime" BO_ 2164079358 500;
BA_ "GenMsgSendType" BO_ 2164079358 0;
BA_ "VFrameFormat" BO_ 2164079358 3;
BA_ "GenMsgCycleTime" BO_ 2364549118 50;
BA_ "GenMsgSendType" BO_ 2364549118 0;
BA_ "VFrameFormat" BO_ 2364549118 3;
BA_ "SystemSignalLongSymbol" SG_ 2364549118 Aftrtrtmnt2SCRRqdRgntQnttyFrIntg "Aftrtrtmnt2SCRRqdRgntQnttyFrIntg";
BA_ "GenMsgCycleTime" BO_ 2566732798 500;
BA_ "GenMsgSendType" BO_ 2566732798 0;
BA_ "VFrameFormat" BO_ 2566732798 3;
BA_ "SystemSignalLongSymbol" SG_ 2566732798 Aftrtrtmnt2SCRCtlystRgntLnHtr4Pr "Aftrtrtmnt2SCRCtlystRgntLnHtr4Pr";
BA_ "SystemSignalLongSymbol" SG_ 2566732798 Aftrtrtmnt2SCRCtlystRgntLnHtr4St "Aftrtrtmnt2SCRCtlystRgntLnHtr4St";
BA_ "SystemSignalLongSymbol" SG_ 2566732798 Aftrtrtmnt2SCRCtlystRgntLnHtr3Pr "Aftrtrtmnt2SCRCtlystRgntLnHtr3Pr";
BA_ "SystemSignalLongSymbol" SG_ 2566732798 Aftrtrtmnt2SCRCtlystRgntLnHtr3St "Aftrtrtmnt2SCRCtlystRgntLnHtr3St";
BA_ "SystemSignalLongSymbol" SG_ 2566732798 Aftrtrtmnt2SCRCtlystRgntLnHtr2Pr "Aftrtrtmnt2SCRCtlystRgntLnHtr2Pr";
BA_ "SystemSignalLongSymbol" SG_ 2566732798 Aftrtrtmnt2SCRCtlystRgntLnHtr2St "Aftrtrtmnt2SCRCtlystRgntLnHtr2St";
BA_ "SystemSignalLongSymbol" SG_ 2566732798 Aftrtrtmnt2SCRCtlystRgntLnHtr1Pr "Aftrtrtmnt2SCRCtlystRgntLnHtr1Pr";
BA_ "SystemSignalLongSymbol" SG_ 2566732798 Aftrtrtmnt2SCRCtlystRgntLnHtr1St "Aftrtrtmnt2SCRCtlystRgntLnHtr1St";
BA_ "SystemSignalLongSymbol" SG_ 2566732798 Aftrtrtmnt2SCRDsngVlvExhstTmpRdc "Aftrtrtmnt2SCRDsngVlvExhstTmpRdc";
BA_ "GenMsgCycleTime" BO_ 2364548862 50;
BA_ "GenMsgSendType" BO_ 2364548862 0;
BA_ "VFrameFormat" BO_ 2364548862 3;
BA_ "SystemSignalLongSymbol" SG_ 2364548862 Aftrtrtmnt2SCRActlRgntQnttyOfInt "Aftrtrtmnt2SCRActlRgntQnttyOfInt";
BA_ "GenMsgCycleTime" BO_ 2364549374 50;
BA_ "GenMsgSendType" BO_ 2364549374 0;
BA_ "VFrameFormat" BO_ 2364549374 3;
BA_ "SystemSignalLongSymbol" SG_ 2364549374 Aftrtrtmnt2OtltNH3GsSnsrHtrPrlmn "Aftrtrtmnt2OtltNH3GsSnsrHtrPrlmn";
BA_ "GenMsgCycleTime" BO_ 2566726142 500;
BA_ "GenMsgSendType" BO_ 2566726142 0;
BA_ "VFrameFormat" BO_ 2566726142 3;
BA_ "SystemSignalLongSymbol" SG_ 2566726142 Aftrtrtmnt2GsOxdtnCtlystDffPrssP "Aftrtrtmnt2GsOxdtnCtlystDffPrssP";
BA_ "SystemSignalLongSymbol" SG_ 2566726142 Aftrtrtmnt2GsOxdtnCtlystOtltGsTm "Aftrtrtmnt2GsOxdtnCtlystOtltGsTm";
BA_ "SystemSignalLongSymbol" SG_ 2566726142 Aftrtrtmnt2GsOxdtnCtlystIntkGsTm "Aftrtrtmnt2GsOxdtnCtlystIntkGsTm";
BA_ "SystemSignalLongSymbol" SG_ 2566726142 Aftrtrtmnt2GsOxdtnCtlystOtl_0000 "Aftrtrtmnt2GsOxdtnCtlystOtl_0000";
BA_ "SystemSignalLongSymbol" SG_ 2566726142 Aftrtrtmnt2GsOxdtnCtlystInt_0000 "Aftrtrtmnt2GsOxdtnCtlystInt_0000";
BA_ "GenMsgCycleTime" BO_ 2566725630 500;
BA_ "GenMsgSendType" BO_ 2566725630 0;
BA_ "VFrameFormat" BO_ 2566725630 3;
BA_ "SystemSignalLongSymbol" SG_ 2566725630 Aftrtrtmnt2DslOxdtnCtlystOtltGsT "Aftrtrtmnt2DslOxdtnCtlystOtltGsT";
BA_ "SystemSignalLongSymbol" SG_ 2566725630 Aftrtrtmnt2DslOxdtnCtlystIntkGsT "Aftrtrtmnt2DslOxdtnCtlystIntkGsT";
BA_ "SystemSignalLongSymbol" SG_ 2566725630 Aftrtrtmnt2DslOxdtnCtlystOt_0000 "Aftrtrtmnt2DslOxdtnCtlystOt_0000";
BA_ "SystemSignalLongSymbol" SG_ 2566725630 Aftrtrtmnt2DslOxdtnCtlystIn_0000 "Aftrtrtmnt2DslOxdtnCtlystIn_0000";
BA_ "SystemSignalLongSymbol" SG_ 2566725630 Aftrtrtmnt2DslOxdtnCtlystDf_0000 "Aftrtrtmnt2DslOxdtnCtlystDf_0000";
BA_ "GenMsgCycleTime" BO_ 2566733310 1000;
BA_ "GenMsgSendType" BO_ 2566733310 0;
BA_ "VFrameFormat" BO_ 2566733310 3;
BA_ "SystemSignalLongSymbol" SG_ 2566733310 Aftrtrtmnt1SCRCtlystRgntTnk2HtrP "Aftrtrtmnt1SCRCtlystRgntTnk2HtrP";
BA_ "SystemSignalLongSymbol" SG_ 2566733310 Aftrtrtmnt1SCRRgntTnk2TmpPrlmnry "Aftrtrtmnt1SCRRgntTnk2TmpPrlmnry";
BA_ "SystemSignalLongSymbol" SG_ 2566733310 Aftrtrtmnt1SCRCtlystRgntTnk2LvlP "Aftrtrtmnt1SCRCtlystRgntTnk2LvlP";
BA_ "GenMsgCycleTime" BO_ 2566733054 1000;
BA_ "GenMsgSendType" BO_ 2566733054 0;
BA_ "VFrameFormat" BO_ 2566733054 3;
BA_ "SystemSignalLongSymbol" SG_ 2566733054 Aftrtrtmnt1SCRCtlystRgntTnkDrnVl "Aftrtrtmnt1SCRCtlystRgntTnkDrnVl";
BA_ "SystemSignalLongSymbol" SG_ 2566733054 Aftrtrtmnt1SCRCtlystRgntTnkFllVl "Aftrtrtmnt1SCRCtlystRgntTnkFllVl";
BA_ "SystemSignalLongSymbol" SG_ 2566733054 Aftrtrtmnt1SCRCtlystRgntPmpDrvPr "Aftrtrtmnt1SCRCtlystRgntPmpDrvPr";
BA_ "SystemSignalLongSymbol" SG_ 2566733054 Aftrtrtmnt1SCRCtlystRgntPmpMtrSp "Aftrtrtmnt1SCRCtlystRgntPmpMtrSp";
BA_ "GenMsgCycleTime" BO_ 2499624702 500;
BA_ "GenMsgSendType" BO_ 2499624702 0;
BA_ "VFrameFormat" BO_ 2499624702 3;
BA_ "SystemSignalLongSymbol" SG_ 2499624702 Aftrtrtmnt1SCRCtlystOtltGsTmpPrl "Aftrtrtmnt1SCRCtlystOtltGsTmpPrl";
BA_ "SystemSignalLongSymbol" SG_ 2499624702 Aftrtrtmnt1SCRCtlystIntkGsTmpPrl "Aftrtrtmnt1SCRCtlystIntkGsTmpPrl";
BA_ "GenMsgCycleTime" BO_ 2566733822 500;
BA_ "GenMsgSendType" BO_ 2566733822 0;
BA_ "VFrameFormat" BO_ 2566733822 3;
BA_ "SystemSignalLongSymbol" SG_ 2566733822 Aftrtrtmnt1SCRCtlystExhstGsDffPr "Aftrtrtmnt1SCRCtlystExhstGsDffPr";
BA_ "SystemSignalLongSymbol" SG_ 2566733822 Aftrtrtmnt1SCRCtlystExhstGs_0000 "Aftrtrtmnt1SCRCtlystExhstGs_0000";
BA_ "GenMsgCycleTime" BO_ 2566734078 500;
BA_ "GenMsgSendType" BO_ 2566734078 0;
BA_ "VFrameFormat" BO_ 2566734078 3;
BA_ "GenMsgCycleTime" BO_ 2364548350 50;
BA_ "GenMsgSendType" BO_ 2364548350 0;
BA_ "VFrameFormat" BO_ 2364548350 3;
BA_ "SystemSignalLongSymbol" SG_ 2364548350 Aftrtrtmnt1SCRRqdRgntQnttyFrIntg "Aftrtrtmnt1SCRRqdRgntQnttyFrIntg";
BA_ "GenMsgCycleTime" BO_ 2566734334 500;
BA_ "GenMsgSendType" BO_ 2566734334 0;
BA_ "VFrameFormat" BO_ 2566734334 3;
BA_ "SystemSignalLongSymbol" SG_ 2566734334 Aftrtrtmnt1SCRCtlystRgntLnHtr4Pr "Aftrtrtmnt1SCRCtlystRgntLnHtr4Pr";
BA_ "SystemSignalLongSymbol" SG_ 2566734334 Aftrtrtmnt1SCRCtlystRgntLnHtr4St "Aftrtrtmnt1SCRCtlystRgntLnHtr4St";
BA_ "SystemSignalLongSymbol" SG_ 2566734334 Aftrtrtmnt1SCRCtlystRgntLnHtr3Pr "Aftrtrtmnt1SCRCtlystRgntLnHtr3Pr";
BA_ "SystemSignalLongSymbol" SG_ 2566734334 Aftrtrtmnt1SCRCtlystRgntLnHtr3St "Aftrtrtmnt1SCRCtlystRgntLnHtr3St";
BA_ "SystemSignalLongSymbol" SG_ 2566734334 Aftrtrtmnt1SCRCtlystRgntLnHtr2Pr "Aftrtrtmnt1SCRCtlystRgntLnHtr2Pr";
BA_ "SystemSignalLongSymbol" SG_ 2566734334 Aftrtrtmnt1SCRCtlystRgntLnHtr2St "Aftrtrtmnt1SCRCtlystRgntLnHtr2St";
BA_ "SystemSignalLongSymbol" SG_ 2566734334 Aftrtrtmnt1SCRCtlystRgntLnHtr1Pr "Aftrtrtmnt1SCRCtlystRgntLnHtr1Pr";
BA_ "SystemSignalLongSymbol" SG_ 2566734334 Aftrtrtmnt1SCRCtlystRgntLnHtr1St "Aftrtrtmnt1SCRCtlystRgntLnHtr1St";
BA_ "SystemSignalLongSymbol" SG_ 2566734334 Aftrtrtmnt1SCRDsngVlvExhstTmpRdc "Aftrtrtmnt1SCRDsngVlvExhstTmpRdc";
BA_ "GenMsgCycleTime" BO_ 2364548094 50;
BA_ "GenMsgSendType" BO_ 2364548094 0;
BA_ "VFrameFormat" BO_ 2364548094 3;
BA_ "SystemSignalLongSymbol" SG_ 2364548094 Aftrtrtmnt1SCRActlRgntQnttyOfInt "Aftrtrtmnt1SCRActlRgntQnttyOfInt";
BA_ "GenMsgCycleTime" BO_ 2364548606 50;
BA_ "GenMsgSendType" BO_ 2364548606 0;
BA_ "VFrameFormat" BO_ 2364548606 3;
BA_ "SystemSignalLongSymbol" SG_ 2364548606 Aftrtrtmnt1OtltNH3GsSnsrHtrPrlmn "Aftrtrtmnt1OtltNH3GsSnsrHtrPrlmn";
BA_ "GenMsgCycleTime" BO_ 2566726398 500;
BA_ "GenMsgSendType" BO_ 2566726398 0;
BA_ "VFrameFormat" BO_ 2566726398 3;
BA_ "SystemSignalLongSymbol" SG_ 2566726398 Aftrtrtmnt1GsOxdtnCtlystDffPrssP "Aftrtrtmnt1GsOxdtnCtlystDffPrssP";
BA_ "SystemSignalLongSymbol" SG_ 2566726398 Aftrtrtmnt1GsOxdtnCtlystOtltGsTm "Aftrtrtmnt1GsOxdtnCtlystOtltGsTm";
BA_ "SystemSignalLongSymbol" SG_ 2566726398 Aftrtrtmnt1GsOxdtnCtlystIntkGsTm "Aftrtrtmnt1GsOxdtnCtlystIntkGsTm";
BA_ "SystemSignalLongSymbol" SG_ 2566726398 Aftrtrtmnt1GsOxdtnCtlystOtl_0000 "Aftrtrtmnt1GsOxdtnCtlystOtl_0000";
BA_ "SystemSignalLongSymbol" SG_ 2566726398 Aftrtrtmnt1GsOxdtnCtlystInt_0000 "Aftrtrtmnt1GsOxdtnCtlystInt_0000";
VAL_ 2565865982 EngAuxShutdownSwitch 3 "NotAvailable" 2 "Error" 1 "On" 0 "Off";
VAL_ 2565865982 TrctrMntdTrilerABSWarningSignal 3 "TakeNoAction" 2 "Reserved" 1 "On" 0 "Off";
VAL_ 2565865982 TrailerABSStatus 3 "NotAvailableOrNotSupported" 2 "Reserved" 1 "TrailerABSActive" 0 "InformationAvailableButNotActive";
VAL_ 2565865982 HaltBrakeSwitch 3 "NotAvailable" 2 "Error" 1 "HaltBrakeSwitchActive" 0 "HaltBrakeSwitchPassive";
VAL_ 2565865982 ATC_ASRInformationSignal 3 "TakeNoAction" 2 "Reserved" 1 "On" 0 "Off";
VAL_ 2565865982 ABS_EBSAmberWarningSignal 3 "TakeNoAction" 2 "Reserved" 1 "On" 0 "Off";
VAL_ 2565865982 EBSRedWarningSignal 3 "TakeNoAction" 2 "Reserved" 1 "On" 0 "Off";
VAL_ 2565865982 ABSFullyOperational 3 "NotAvailable" 2 "Reserved" 1 "FullyOperational" 0 "NotFullyOperational";
VAL_ 2565865982 RemoteAccelEnableSwitch 3 "NotAvailable" 2 "Error" 1 "On" 0 "Off";
VAL_ 2565865982 EngDerateSwitch 3 "NotAvailable" 2 "Error" 1 "On" 0 "Off";
VAL_ 2565865982 AccelInterlockSwitch 3 "NotAvailable" 2 "Error" 1 "On" 0 "Off";
VAL_ 2565865982 TractionCtrlOverrideSwitch 3 "NotAvailableNotInstalled" 2 "Error" 1 "On" 0 "Off";
VAL_ 2565865982 ASRHillHolderSwitch 3 "NotAvailable" 2 "Error" 1 "ASRHillHolderSwitchActive" 0 "ASRHillHolderSwitchPassive";
VAL_ 2565865982 ASROffroadSwitch 2 "Error" 1 "ASROffroadSwitchActive" 0 "ASROffroadSwitchPassive" 3 "NotAvailable";
VAL_ 2565865982 ABSOffroadSwitch 3 "NotAvailable" 2 "Error" 1 "ABSOffroadSwitchActive" 0 "ABSOffroadSwitchPassive";
VAL_ 2565865982 EBSBrakeSwitch 3 "NotAvailable" 2 "Error" 1 "BrakePedalIsBeingPressed" 0 "BrakePedalIsNotBeingPressed";
VAL_ 2565865982 AntiLockBrakingActive 3 "NotAvailable" 2 "Reserved" 1 "ABSActive" 0 "ABSPassiveButInstalled";
VAL_ 2565865982 ASRBrakeCtrlActive 3 "NotAvailable" 2 "Reserved" 1 "ASRBrakeCtrlActive" 0 "ASRBrakeCtrlPassiveButInstalled";
VAL_ 2565865982 ASREngCtrlActive 3 "NotAvailable" 2 "Reserved" 1 "ASREngCtrlActive" 0 "ASREngCtrlPassiveButInstalled";
VAL_ 2565867262 RearAxleGroupEngagementStatus 3 "notAvailable" 2 "error" 1 "rearAxleGroupEngaged" 0 "rearAxleGroupDisengaged";
VAL_ 2565867262 FrontAxleGroupEngagementStatus 3 "notAvailable" 2 "error" 1 "frontAxleGroupEngaged" 0 "frontAxleGroupDisengaged";
VAL_ 2565867262 DiffLockStateCentralRear 3 "NotAvailable" 2 "Error" 1 "DiffLockEngaged" 0 "DiffLockDisengaged";
VAL_ 2565867262 DiffLockStateCentralFront 3 "NotAvailable" 2 "Error" 1 "DiffLockEngaged" 0 "DiffLockDisengaged";
VAL_ 2565867262 DiffLockStateCentral 3 "NotAvailable" 2 "Error" 1 "DiffLockEngaged" 0 "DiffLockDisengaged";
VAL_ 2565867262 DiffLockStateRearAxle2 3 "NotAvailable" 2 "Error" 1 "DiffLockEngaged" 0 "DiffLockDisengaged";
VAL_ 2565867262 DiffLockStateRearAxle1 3 "NotAvailable" 2 "Error" 1 "DiffLockEngaged" 0 "DiffLockDisengaged";
VAL_ 2565867262 DiffLockStateFrontAxle2 3 "NotAvailable" 2 "Error" 1 "DiffLockEngaged" 0 "DiffLockDisengaged";
VAL_ 2565867262 DiffLockStateFrontAxle1 3 "NotAvailable" 2 "Error" 1 "DiffLockEngaged" 0 "DiffLockDisengaged";
VAL_ 2566768382 EngStartEnableDevice2Config 15 "NotAvailable" 5 "1110Reserved" 4 "ElctricIntakeAirHeaterInstalled" 3 "EtherInjectionInstalled" 2 "FuelledStartInstalled" 1 "GlowPlugsInstalled" 0 "NoStartEnableDevice2Installed";
VAL_ 2566768382 EngStartEnableDevice1Config 15 "NotAvailable" 5 "1110Reserved" 4 "ElctricIntakeAirHeaterInstalled" 3 "EtherInjectionInstalled" 2 "FuelledStartInstalled" 1 "GlowPlugsInstalled" 0 "NoStartEnableDevice1Installed";
VAL_ 2566768382 EngStartEnableDevice2 3 "NotAvailable" 2 "Reserved" 1 "StartEnableON" 0 "StartEnableOFF";
VAL_ 2566768382 EngStartEnableDevice1 3 "NotAvailable" 2 "Reserved" 1 "StartEnableON" 0 "StartEnableOFF";
VAL_ 2566771966 TransOilLevelRq 3 "DontCare_TakeNoAction" 2 "Reserved" 1 "TransOilLevelReadingDesired" 0 "NoTransOilLevelReadingDesired";
VAL_ 2566771966 FifthWheelReleaseCtrl 3 "NotAvailable" 2 "Error" 1 "CplrUnlckdTrlrCnBUnhtchdHitched" 0 "CouplerLocked";
VAL_ 2566771966 FfthWhlRlaseCtrlSecurityLockout 3 "NotAvailable" 2 "Error" 1 "FifthWheelReleaseEnabled" 0 "FifthWheelReleaseDisabled";
VAL_ 2566771966 TransferCaseSelectorSwitch 7 "NotAvailable" 5 "ReservedForSAEAssignment" 4 "4WheelLow" 0 "2WheelHigh" 6 "ErrorIndicator" 3 "2WheelLow" 2 "Neutral" 1 "4WheelHigh";
VAL_ 2564882174 DslPrtcltFltrRgnrtonForceSwitch 3 "notAvailable" 2 "error" 1 "active" 0 "notActive";
VAL_ 2564882174 DslPrtcltFltrRgnrtnInhbitSwitch 3 "notAvailable" 2 "error" 1 "active" 0 "notActive";
VAL_ 2564882174 SelectedMaxVehicleSpeedLimit 0 "sUsdTIndctThtAMxVhclSpdIsNtSlct";
VAL_ 2564882174 RqCabZoneHeating 3 "DontCare_TakeNoAction" 2 "Reserved" 1 "HeatCabZone" 0 "DoNotCabEngZone";
VAL_ 2564882174 RqEngZoneHeating 3 "DontCare_TakeNoAction" 2 "Reserved" 1 "HeatEngZone" 0 "DoNotHeatEngZone";
VAL_ 2564882174 AuxHeaterModeRq 15 "DontCare_TakeNoAction" 14 "Reserved" 4 "1101NotDefined" 3 "NormalMode" 2 "EconomyMode" 1 "OffDTADRPrErpnRgltnsFrTrnsprtOf" 0 "DeactivateAuxHeater";
VAL_ 2564882174 EngAutomaticStartEnableSwitch 3 "NotAvailable" 2 "Error" 1 "SwitchInOnState" 0 "SwitchInOffState";
VAL_ 2564882174 AtmaticGearShiftingEnableSwitch 3 "NotAvailable" 2 "Error" 1 "AutomatedGearShiftingIsEnabled" 0 "AutomatedGearShiftingIsDisabled";
VAL_ 2564882174 VhclLmtngSpdGvernorEnableSwitch 3 "NotAvailable" 2 "Error" 1 "SwitchedEnabled" 0 "SwitchDisabled";
VAL_ 2564882174 VhclLmtngSpdGvrnrIncrmentSwitch 3 "NotAvailable" 2 "Error" 1 "SwitchInOnStateIncrease" 0 "SwitchInOffState";
VAL_ 2564882174 VhclLmtngSpdGvrnrDcrementSwitch 3 "NotAvailable" 2 "Error" 1 "SwitchInOnStateDecrease" 0 "SwitchInOffState";
VAL_ 2564882174 SeatBeltSwitch 3 "NotAvailable" 2 "ErrrSwtchStteCannotBeDetermined" 1 "OKSeatBeltIsBuckled" 0 "NOTBuckled";
VAL_ 2564882174 OperatorSeatDirectionSwitch 3 "NotAvailable" 2 "Error" 1 "OperatorSeatIsFacingForward" 0 "OperatorSeatNotFacingForward";
VAL_ 2564882174 BatteryMainSwitchHoldRq 3 "DontCare_TakeNoAction" 2 "undefined" 1 "HoldBatteryMainSwitch" 0 "ReleaseBatteryMainSwitch";
VAL_ 2564882174 AuxHeaterCoolantPumpRq 3 "DontCare_TakeNoAction" 2 "Reserved" 1 "ActivateWaterPump" 0 "DeactivateWaterPump";
VAL_ 2566844926 ParkBrakeReleaseInhibitRq 3 "Unavailable" 2 "SAEReserved" 1 "ParkBrakeReleaseInhibitRqed" 0 "ParkBrakeReleaseInhibitNotRqed";
VAL_ 2566844926 PTOGovernorState 31 "NotAvailable" 20 "11110NotDefined" 19 "PTOSetSpeedMemory2" 18 "PTOSetSpeedMemory1" 17 "PreprogrammedSetSpeed8" 16 "PreprogrammedSetSpeed7" 15 "PreprogrammedSetSpeed6" 14 "PreprogrammedSetSpeed5" 13 "PreprogrammedSetSpeed4" 12 "PreprogrammedSetSpeed3" 11 "PreprogrammedSetSpeed2" 10 "PreprogrammedSetSpeed1" 9 "AccelOverride" 8 "Accelerate" 7 "Resume" 6 "Decelerate_Coast" 5 "Set" 4 "RemoteStandby" 3 "Standby" 2 "RemoteHold" 1 "Hold" 0 "Off_Disabled";
VAL_ 2566844926 EngShutdownOverrideSwitch 3 "NotAvailable" 2 "Error" 1 "On" 0 "Off";
VAL_ 2566844926 EngTestModeSwitch 3 "NotAvailable" 2 "Error" 1 "On" 0 "Off";
VAL_ 2566844926 EngIdleDecrementSwitch 3 "NotAvailable" 2 "Error" 1 "On" 0 "Off";
VAL_ 2566844926 EngIdleIncrementSwitch 3 "NotAvailable" 2 "Error" 1 "On" 0 "Off";
VAL_ 2566844926 CruiseCtrlStates 7 "NotAvailable" 6 "AccelOverride" 5 "Set" 4 "Resume" 3 "Decelerate" 2 "Accelerate" 1 "Hold" 0 "Off_Disabled";
VAL_ 2566844926 CruiseCtrlAccelerateSwitch 3 "NotAvailable" 2 "Error" 1 "CrsCtrlActivatorInPosAccelerate" 0 "CrsCtrlActvtrNotInPosAccelerate";
VAL_ 2566844926 CruiseCtrlResumeSwitch 3 "NotAvailable" 2 "Error" 1 "CruiseCtrlActivatorInPosResume" 0 "CrseCtrlActivatorNotInPosResume";
VAL_ 2566844926 CruiseCtrlCoastSwitch 3 "NotAvailable" 2 "Error" 1 "CruiseCtrlActivatorInPosCoast" 0 "CriseCtrlActivatorNotInPosCoast";
VAL_ 2566844926 CruiseCtrlSetSwitch 3 "NotAvailable" 2 "Error" 1 "CruiseCtrlActivatorInPosSet" 0 "CruiseCtrlActivatorNotInPosSet";
VAL_ 2566844926 ClutchSwitch 3 "NotAvailable" 2 "Error" 1 "ClutchPedalDepressed" 0 "ClutchPedalReleased";
VAL_ 2566844926 BrakeSwitch 3 "NotAvailable" 2 "Error" 1 "BrakePedalDepressed" 0 "BrakePedalReleased";
VAL_ 2566844926 CruiseCtrlEnableSwitch 3 "NotAvailable" 2 "Error" 1 "CruiseCtrlEnabled" 0 "CruiseCtrlDisabled";
VAL_ 2566844926 CruiseCtrlActive 3 "NotAvailable" 2 "Error" 1 "CruiseCtrlSwitchedOn" 0 "CruiseCtrlSwitchedOff";
VAL_ 2566844926 CruiseCtrlPauseSwitch 3 "TakeNoAction" 2 "ErrorIndicator" 1 "On" 0 "Off";
VAL_ 2566844926 ParkingBrakeSwitch 3 "NotAvailable" 2 "Error" 1 "ParkingBrakeSet" 0 "ParkingBrakeNotSet";
VAL_ 2566844926 TwoSpeedAxleSwitch 3 "NotAvailable" 2 "Error" 1 "HighSpeedRange" 0 "LowSpeedRange";
VAL_ 2566719486 EngFuelFilterRestrictedLampCmd 3 "NotAvailable" 2 "Flash" 1 "LampOn" 0 "LampOff";
VAL_ 2566719486 EngAirFilterRestrictionLampCmd 3 "NotAvailable" 2 "Reserved" 1 "LampOn" 0 "LampOff";
VAL_ 2566719486 EngIdleManagementActiveLampCmd 3 "NotAvailable" 2 "Reserved" 1 "LampOn" 0 "LampOff";
VAL_ 2566719486 EngCoolantLevelLowLampCmd 3 "NotAvailable" 2 "Reserved" 1 "LampOn" 0 "LampOff";
VAL_ 2566719486 EngCoolantTempHighLampCmd 3 "NotAvailable" 2 "Reserved" 1 "LampOn" 0 "LampOff";
VAL_ 2566719486 EngOilPressLowLampCmd 3 "NotAvailable" 2 "Reserved" 1 "LampOn" 0 "LampOff";
VAL_ 2566719486 CmprssnBrkEnblSwtchIndctrLmpCmd 3 "NotAvailable" 2 "Reserved" 1 "LampON" 0 "LampOFF";
VAL_ 2566719486 EngBrakeActiveLampCmd 3 "NotAvailable" 2 "Reserved" 1 "LampOn" 0 "LampOff";
VAL_ 2566719486 OBDMalfunctionIndicatorLampCmd 3 "NotAvailable" 2 "Reserved" 1 "LampOn" 0 "LampOff";
VAL_ 2566719486 EngRedStopLampCmd 3 "NotAvailable" 2 "Reserved" 1 "LampOn" 0 "LampOff";
VAL_ 2566719486 EngAmberWarningLampCmd 3 "NotAvailable" 2 "Reserved" 1 "LampOn" 0 "LampOff";
VAL_ 2566719486 EngProtectLampCmd 3 "NotAvailable" 2 "Reserved" 1 "LampOn" 0 "LampOff";
VAL_ 2633832702 RearCollisionSensor4Type 15 "NotAvailable" 14 "ErrrTypOfSnsrCannotBeDetermined" 8 "1101Reserved" 7 "OpticalSensor" 6 "LidarSensor" 5 "RadarSensor" 4 "FiberopticSensor" 3 "SonicSensor" 2 "RollrateSensor" 1 "PressSensor" 0 "AccelerationSensor";
VAL_ 2633832702 RearCollisionSensor3Type 15 "NotAvailable" 14 "ErrrTypOfSnsrCannotBeDetermined" 8 "1101Reserved" 7 "OpticalSensor" 6 "LidarSensor" 5 "RadarSensor" 4 "FiberopticSensor" 3 "SonicSensor" 2 "RollrateSensor" 1 "PressSensor" 0 "AccelerationSensor";
VAL_ 2633832702 RearCollisionSensor2Type 15 "NotAvailable" 14 "ErrrTypOfSnsrCannotBeDetermined" 8 "1101Reserved" 7 "OpticalSensor" 6 "LidarSensor" 5 "RadarSensor" 4 "FiberopticSensor" 3 "SonicSensor" 2 "RollrateSensor" 1 "PressSensor" 0 "AccelerationSensor";
VAL_ 2633832702 RearCollisionSensor1Type 15 "NotAvailable" 14 "ErrrTypOfSnsrCannotBeDetermined" 8 "1101Reserved" 7 "OpticalSensor" 6 "LidarSensor" 5 "RadarSensor" 4 "FiberopticSensor" 3 "SonicSensor" 2 "RollrateSensor" 1 "PressSensor" 0 "AccelerationSensor";
VAL_ 2633832702 SdeCollisionSensorRearRightType 15 "NotAvailable" 14 "ErrrTypOfSnsrCannotBeDetermined" 8 "1101Reserved" 7 "OpticalSensor" 6 "LidarSensor" 5 "RadarSensor" 4 "FiberopticSensor" 3 "SonicSensor" 2 "RollrateSensor" 1 "PressSensor" 0 "AccelerationSensor";
VAL_ 2633832702 SdCllsionSensorMidRearRightType 15 "NotAvailable" 14 "ErrrTypOfSnsrCannotBeDetermined" 8 "1101Reserved" 7 "OpticalSensor" 6 "LidarSensor" 5 "RadarSensor" 4 "FiberopticSensor" 3 "SonicSensor" 2 "RollrateSensor" 1 "PressSensor" 0 "AccelerationSensor";
VAL_ 2633832702 SdCllsonSensorMidFrontRightType 15 "NotAvailable" 14 "ErrrTypOfSnsrCannotBeDetermined" 8 "1101Reserved" 7 "OpticalSensor" 6 "LidarSensor" 5 "RadarSensor" 4 "FiberopticSensor" 3 "SonicSensor" 2 "RollrateSensor" 1 "PressSensor" 0 "AccelerationSensor";
VAL_ 2633832702 SdCollisionSensorFrontRightType 15 "NotAvailable" 14 "ErrrTypOfSnsrCannotBeDetermined" 8 "1101Reserved" 7 "OpticalSensor" 6 "LidarSensor" 5 "RadarSensor" 4 "FiberopticSensor" 3 "SonicSensor" 2 "RollrateSensor" 1 "PressSensor" 0 "AccelerationSensor";
VAL_ 2633832702 SideCollisionSensorRearLeftType 15 "NotAvailable" 14 "ErrrTypOfSnsrCannotBeDetermined" 8 "1101Reserved" 7 "OpticalSensor" 6 "LidarSensor" 5 "RadarSensor" 4 "FiberopticSensor" 3 "SonicSensor" 2 "RollrateSensor" 1 "PressSensor" 0 "AccelerationSensor";
VAL_ 2633832702 SdCllisionSensorMidRearLeftType 15 "NotAvailable" 14 "ErrrTypOfSnsrCannotBeDetermined" 8 "1101Reserved" 7 "OpticalSensor" 6 "LidarSensor" 5 "RadarSensor" 4 "FiberopticSensor" 3 "SonicSensor" 2 "RollrateSensor" 1 "PressSensor" 0 "AccelerationSensor";
VAL_ 2633832702 SdCllsionSensorMidFrontLeftType 15 "NotAvailable" 14 "ErrrTypOfSnsrCannotBeDetermined" 8 "1101Reserved" 7 "OpticalSensor" 6 "LidarSensor" 5 "RadarSensor" 4 "FiberopticSensor" 3 "SonicSensor" 2 "RollrateSensor" 1 "PressSensor" 0 "AccelerationSensor";
VAL_ 2633832702 SdeCollisionSensorFrontLeftType 15 "NotAvailable" 14 "ErrrTypOfSnsrCannotBeDetermined" 8 "1101Reserved" 7 "OpticalSensor" 6 "LidarSensor" 5 "RadarSensor" 4 "FiberopticSensor" 3 "SonicSensor" 2 "RollrateSensor" 1 "PressSensor" 0 "AccelerationSensor";
VAL_ 2633832702 FrontalCollisionSensor4Type 15 "NotAvailable" 14 "ErrrTypOfSnsrCannotBeDetermined" 8 "1101Reserved" 7 "OpticalSensor" 6 "LidarSensor" 5 "RadarSensor" 4 "FiberopticSensor" 3 "SonicSensor" 2 "RollrateSensor" 1 "PressSensor" 0 "AccelerationSensor";
VAL_ 2633832702 FrontalCollisionSensor3Type 15 "NotAvailable" 14 "ErrrTypOfSnsrCannotBeDetermined" 8 "1101Reserved" 7 "OpticalSensor" 6 "LidarSensor" 5 "RadarSensor" 4 "FiberopticSensor" 3 "SonicSensor" 2 "RollrateSensor" 1 "PressSensor" 0 "AccelerationSensor";
VAL_ 2633832702 FrontalCollisionSensor2Type 15 "NotAvailable" 14 "ErrrTypOfSnsrCannotBeDetermined" 8 "1101Reserved" 7 "OpticalSensor" 6 "LidarSensor" 5 "RadarSensor" 4 "FiberopticSensor" 3 "SonicSensor" 2 "RollrateSensor" 1 "PressSensor" 0 "AccelerationSensor";
VAL_ 2633832702 FrontalCollisionSensor1Type 15 "NotAvailable" 14 "ErrrTypOfSnsrCannotBeDetermined" 8 "1101Reserved" 7 "OpticalSensor" 6 "LidarSensor" 5 "RadarSensor" 4 "FiberopticSensor" 3 "SonicSensor" 2 "RollrateSensor" 1 "PressSensor" 0 "AccelerationSensor";
VAL_ 2163223550 CrashType 16 "Rollover" 8 "SideCrash" 2 "RearCrash" 1 "FrontalCrash";
VAL_ 2365400830 Joystick9Button9PressedStatus 3 "NotAvailable" 2 "ErrorIndicator" 1 "ButtonPressed" 0 "ButtonNotPressed";
VAL_ 2365400830 Joystick9Button10PressedStatus 3 "NotAvailable" 2 "ErrorIndicator" 1 "ButtonPressed" 0 "ButtonNotPressed";
VAL_ 2365400830 Joystick9Button11PressedStatus 3 "NotAvailable" 2 "ErrorIndicator" 1 "ButtonPressed" 0 "ButtonNotPressed";
VAL_ 2365400830 Joystick9Button12PressedStatus 3 "NotAvailable" 2 "ErrorIndicator" 1 "ButtonPressed" 0 "ButtonNotPressed";
VAL_ 2365400830 Joystick9Button5PressedStatus 3 "NotAvailable" 2 "ErrorIndicator" 1 "ButtonPressed" 0 "ButtonNotPressed";
VAL_ 2365400830 Joystick9Button6PressedStatus 3 "NotAvailable" 2 "ErrorIndicator" 1 "ButtonPressed" 0 "ButtonNotPressed";
VAL_ 2365400830 Joystick9Button7PressedStatus 3 "NotAvailable" 2 "ErrorIndicator" 1 "ButtonPressed" 0 "ButtonNotPressed";
VAL_ 2365400830 Joystick9Button8PressedStatus 3 "NotAvailable" 2 "ErrorIndicator" 1 "ButtonPressed" 0 "ButtonNotPressed";
VAL_ 2365400830 Joystick9Button1PressedStatus 3 "NotAvailable" 2 "ErrorIndicator" 1 "ButtonPressed" 0 "ButtonNotPressed";
VAL_ 2365400830 Joystick9Button2PressedStatus 3 "NotAvailable" 2 "ErrorIndicator" 1 "ButtonPressed" 0 "ButtonNotPressed";
VAL_ 2365400830 Joystick9Button3PressedStatus 3 "NotAvailable" 2 "ErrorIndicator" 1 "ButtonPressed" 0 "ButtonNotPressed";
VAL_ 2365400830 Joystick9Button4PressedStatus 3 "NotAvailable" 2 "ErrorIndicator" 1 "ButtonPressed" 0 "ButtonNotPressed";
VAL_ 2365400830 Joystick9XAxisDetentPosStatus 3 "NotAvailable" 2 "ErrorIndicator" 1 "InDetentPos" 0 "NotInDetentPos";
VAL_ 2365400830 Joystick9YAxisDetentPosStatus 3 "NotAvailable" 2 "ErrorIndicator" 1 "InDetentPos" 0 "NotInDetentPos";
VAL_ 2365400830 Jystck9YAxsLvrFrwrdPstvPsStatus 3 "NotAvailable" 2 "ErrorIndicator" 1 "OnPositiveSideOfNeutral" 0 "NotOnPositiveSideOfNeutral";
VAL_ 2365400830 Jystck9YAxsLvrBckNgtvePosStatus 3 "NotAvailable" 2 "ErrorIndicator" 1 "OnNegativeSideOfNeutral" 0 "NotOnNegativeSideOfNeutral";
VAL_ 2365400830 Joystick9YAxisNeutralPosStatus 3 "NotAvailable" 2 "ErrorIndicator" 1 "InNeutralPos" 0 "NotInNeutralPos";
VAL_ 2365400830 Jystck9XAxsLvrRghtPstvPosStatus 3 "NotAvailable" 2 "ErrorIndicator" 1 "OnPositiveSideOfNeutral" 0 "NotOnPositiveSideOfNeutral";
VAL_ 2365400830 Jystck9XAxsLvrLftNgtvePosStatus 3 "NotAvailable" 2 "ErrorIndicator" 1 "OnNegativeSideOfNeutral" 0 "NotOnNegativeSideOfNeutral";
VAL_ 2365400830 Joystick9XAxisNeutralPosStatus 3 "NotAvailable" 2 "ErrorIndicator" 1 "InNeutralPos" 0 "NotInNeutralPos";
VAL_ 2365401342 Joystick8Button9PressedStatus 3 "NotAvailable" 2 "ErrorIndicator" 1 "ButtonPressed" 0 "ButtonNotPressed";
VAL_ 2365401342 Joystick8Button10PressedStatus 3 "NotAvailable" 2 "ErrorIndicator" 1 "ButtonPressed" 0 "ButtonNotPressed";
VAL_ 2365401342 Joystick8Button11PressedStatus 3 "NotAvailable" 2 "ErrorIndicator" 1 "ButtonPressed" 0 "ButtonNotPressed";
VAL_ 2365401342 Joystick8Button12PressedStatus 3 "NotAvailable" 2 "ErrorIndicator" 1 "ButtonPressed" 0 "ButtonNotPressed";
VAL_ 2365401342 Joystick8Button5PressedStatus 3 "NotAvailable" 2 "ErrorIndicator" 1 "ButtonPressed" 0 "ButtonNotPressed";
VAL_ 2365401342 Joystick8Button6PressedStatus 3 "NotAvailable" 2 "ErrorIndicator" 1 "ButtonPressed" 0 "ButtonNotPressed";
VAL_ 2365401342 Joystick8Button7PressedStatus 3 "NotAvailable" 2 "ErrorIndicator" 1 "ButtonPressed" 0 "ButtonNotPressed";
VAL_ 2365401342 Joystick8Button8PressedStatus 3 "NotAvailable" 2 "ErrorIndicator" 1 "ButtonPressed" 0 "ButtonNotPressed";
VAL_ 2365401342 Joystick8Button1PressedStatus 3 "NotAvailable" 2 "ErrorIndicator" 1 "ButtonPressed" 0 "ButtonNotPressed";
VAL_ 2365401342 Joystick8Button2PressedStatus 3 "NotAvailable" 2 "ErrorIndicator" 1 "ButtonPressed" 0 "ButtonNotPressed";
VAL_ 2365401342 Joystick8Button3PressedStatus 3 "NotAvailable" 2 "ErrorIndicator" 1 "ButtonPressed" 0 "ButtonNotPressed";
VAL_ 2365401342 Joystick8Button4PressedStatus 3 "NotAvailable" 2 "ErrorIndicator" 1 "ButtonPressed" 0 "ButtonNotPressed";
VAL_ 2365401342 Joystick8XAxisDetentPosStatus 3 "NotAvailable" 2 "ErrorIndicator" 1 "InDetentPos" 0 "NotInDetentPos";
VAL_ 2365401342 Joystick8YAxisDetentPosStatus 3 "NotAvailable" 2 "ErrorIndicator" 1 "InDetentPos" 0 "NotInDetentPos";
VAL_ 2365401342 Jystck8YAxsLvrFrwrdPstvPsStatus 3 "NotAvailable" 2 "ErrorIndicator" 1 "OnPositiveSideOfNeutral" 0 "NotOnPositiveSideOfNeutral";
VAL_ 2365401342 Jystck8YAxsLvrBckNgtvePosStatus 3 "NotAvailable" 2 "ErrorIndicator" 1 "OnNegativeSideOfNeutral" 0 "NotOnNegativeSideOfNeutral";
VAL_ 2365401342 Joystick8YAxisNeutralPosStatus 3 "NotAvailable" 2 "ErrorIndicator" 1 "InNeutralPos" 0 "NotInNeutralPos";
VAL_ 2365401342 Jystck8XAxsLvrRghtPstvPosStatus 3 "NotAvailable" 2 "ErrorIndicator" 1 "OnPositiveSideOfNeutral" 0 "NotOnPositiveSideOfNeutral";
VAL_ 2365401342 Jystck8XAxsLvrLftNgtvePosStatus 3 "NotAvailable" 2 "ErrorIndicator" 1 "OnNegativeSideOfNeutral" 0 "NotOnNegativeSideOfNeutral";
VAL_ 2365401342 Joystick8XAxisNeutralPosStatus 3 "NotAvailable" 2 "ErrorIndicator" 1 "InNeutralPos" 0 "NotInNeutralPos";
VAL_ 2365401854 Joystick7Button9PressedStatus 3 "NotAvailable" 2 "ErrorIndicator" 1 "ButtonPressed" 0 "ButtonNotPressed";
VAL_ 2365401854 Joystick7Button10PressedStatus 3 "NotAvailable" 2 "ErrorIndicator" 1 "ButtonPressed" 0 "ButtonNotPressed";
VAL_ 2365401854 Joystick7Button11PressedStatus 3 "NotAvailable" 2 "ErrorIndicator" 1 "ButtonPressed" 0 "ButtonNotPressed";
VAL_ 2365401854 Joystick7Button12PressedStatus 3 "NotAvailable" 2 "ErrorIndicator" 1 "ButtonPressed" 0 "ButtonNotPressed";
VAL_ 2365401854 Joystick7Button5PressedStatus 3 "NotAvailable" 2 "ErrorIndicator" 1 "ButtonPressed" 0 "ButtonNotPressed";
VAL_ 2365401854 Joystick7Button6PressedStatus 3 "NotAvailable" 2 "ErrorIndicator" 1 "ButtonPressed" 0 "ButtonNotPressed";
VAL_ 2365401854 Joystick7Button7PressedStatus 3 "NotAvailable" 2 "ErrorIndicator" 1 "ButtonPressed" 0 "ButtonNotPressed";
VAL_ 2365401854 Joystick7Button8PressedStatus 3 "NotAvailable" 2 "ErrorIndicator" 1 "ButtonPressed" 0 "ButtonNotPressed";
VAL_ 2365401854 Joystick7Button1PressedStatus 3 "NotAvailable" 2 "ErrorIndicator" 1 "ButtonPressed" 0 "ButtonNotPressed";
VAL_ 2365401854 Joystick7Button2PressedStatus 3 "NotAvailable" 2 "ErrorIndicator" 1 "ButtonPressed" 0 "ButtonNotPressed";
VAL_ 2365401854 Joystick7Button3PressedStatus 3 "NotAvailable" 2 "ErrorIndicator" 1 "ButtonPressed" 0 "ButtonNotPressed";
VAL_ 2365401854 Joystick7Button4PressedStatus 3 "NotAvailable" 2 "ErrorIndicator" 1 "ButtonPressed" 0 "ButtonNotPressed";
VAL_ 2365401854 Joystick7XAxisDetentPosStatus 3 "NotAvailable" 2 "ErrorIndicator" 1 "InDetentPos" 0 "NotInDetentPos";
VAL_ 2365401854 Joystick7YAxisDetentPosStatus 3 "NotAvailable" 2 "ErrorIndicator" 1 "InDetentPos" 0 "NotInDetentPos";
VAL_ 2365401854 Jystck7YAxsLvrFrwrdPstvPsStatus 3 "NotAvailable" 2 "ErrorIndicator" 1 "OnPositiveSideOfNeutral" 0 "NotOnPositiveSideOfNeutral";
VAL_ 2365401854 Jystck7YAxsLvrBckNgtvePosStatus 3 "NotAvailable" 2 "ErrorIndicator" 1 "OnNegativeSideOfNeutral" 0 "NotOnNegativeSideOfNeutral";
VAL_ 2365401854 Joystick7YAxisNeutralPosStatus 3 "NotAvailable" 2 "ErrorIndicator" 1 "InNeutralPos" 0 "NotInNeutralPos";
VAL_ 2365401854 Jystck7XAxsLvrRghtPstvPosStatus 3 "NotAvailable" 2 "ErrorIndicator" 1 "OnPositiveSideOfNeutral" 0 "NotOnPositiveSideOfNeutral";
VAL_ 2365401854 Jystck7XAxsLvrLftNgtvePosStatus 3 "NotAvailable" 2 "ErrorIndicator" 1 "OnNegativeSideOfNeutral" 0 "NotOnNegativeSideOfNeutral";
VAL_ 2365401854 Joystick7XAxisNeutralPosStatus 3 "NotAvailable" 2 "ErrorIndicator" 1 "InNeutralPos" 0 "NotInNeutralPos";
VAL_ 2365402366 Joystick6Button9PressedStatus 3 "NotAvailable" 2 "ErrorIndicator" 1 "ButtonPressed" 0 "ButtonNotPressed";
VAL_ 2365402366 Joystick6Button10PressedStatus 3 "NotAvailable" 2 "ErrorIndicator" 1 "ButtonPressed" 0 "ButtonNotPressed";
VAL_ 2365402366 Joystick6Button11PressedStatus 3 "NotAvailable" 2 "ErrorIndicator" 1 "ButtonPressed" 0 "ButtonNotPressed";
VAL_ 2365402366 Joystick6Button12PressedStatus 3 "NotAvailable" 2 "ErrorIndicator" 1 "ButtonPressed" 0 "ButtonNotPressed";
VAL_ 2365402366 Joystick6Button5PressedStatus 3 "NotAvailable" 2 "ErrorIndicator" 1 "ButtonPressed" 0 "ButtonNotPressed";
VAL_ 2365402366 Joystick6Button6PressedStatus 3 "NotAvailable" 2 "ErrorIndicator" 1 "ButtonPressed" 0 "ButtonNotPressed";
VAL_ 2365402366 Joystick6Button7PressedStatus 3 "NotAvailable" 2 "ErrorIndicator" 1 "ButtonPressed" 0 "ButtonNotPressed";
VAL_ 2365402366 Joystick6Button8PressedStatus 3 "NotAvailable" 2 "ErrorIndicator" 1 "ButtonPressed" 0 "ButtonNotPressed";
VAL_ 2365402366 Joystick6Button1PressedStatus 3 "NotAvailable" 2 "ErrorIndicator" 1 "ButtonPressed" 0 "ButtonNotPressed";
VAL_ 2365402366 Joystick6Button2PressedStatus 3 "NotAvailable" 2 "ErrorIndicator" 1 "ButtonPressed" 0 "ButtonNotPressed";
VAL_ 2365402366 Joystick6Button3PressedStatus 3 "NotAvailable" 2 "ErrorIndicator" 1 "ButtonPressed" 0 "ButtonNotPressed";
VAL_ 2365402366 Joystick6Button4PressedStatus 3 "NotAvailable" 2 "ErrorIndicator" 1 "ButtonPressed" 0 "ButtonNotPressed";
VAL_ 2365402366 Joystick6XAxisDetentPosStatus 3 "NotAvailable" 2 "ErrorIndicator" 1 "InDetentPos" 0 "NotInDetentPos";
VAL_ 2365402366 Joystick6YAxisDetentPosStatus 3 "NotAvailable" 2 "ErrorIndicator" 1 "InDetentPos" 0 "NotInDetentPos";
VAL_ 2365402366 Jystck6YAxsLvrFrwrdPstvPsStatus 3 "NotAvailable" 2 "ErrorIndicator" 1 "OnPositiveSideOfNeutral" 0 "NotOnPositiveSideOfNeutral";
VAL_ 2365402366 Jystck6YAxsLvrBckNgtvePosStatus 3 "NotAvailable" 2 "ErrorIndicator" 1 "OnNegativeSideOfNeutral" 0 "NotOnNegativeSideOfNeutral";
VAL_ 2365402366 Joystick6YAxisNeutralPosStatus 3 "NotAvailable" 2 "ErrorIndicator" 1 "InNeutralPos" 0 "NotInNeutralPos";
VAL_ 2365402366 Jystck6XAxsLvrRghtPstvPosStatus 3 "NotAvailable" 2 "ErrorIndicator" 1 "OnPositiveSideOfNeutral" 0 "NotOnPositiveSideOfNeutral";
VAL_ 2365402366 Jystck6XAxsLvrLftNgtvePosStatus 3 "NotAvailable" 2 "ErrorIndicator" 1 "OnNegativeSideOfNeutral" 0 "NotOnNegativeSideOfNeutral";
VAL_ 2365402366 Joystick6XAxisNeutralPosStatus 3 "NotAvailable" 2 "ErrorIndicator" 1 "InNeutralPos" 0 "NotInNeutralPos";
VAL_ 2365402878 Joystick5Button9PressedStatus 3 "NotAvailable" 2 "ErrorIndicator" 1 "ButtonPressed" 0 "ButtonNotPressed";
VAL_ 2365402878 Joystick5Button10PressedStatus 3 "NotAvailable" 2 "ErrorIndicator" 1 "ButtonPressed" 0 "ButtonNotPressed";
VAL_ 2365402878 Joystick5Button11PressedStatus 3 "NotAvailable" 2 "ErrorIndicator" 1 "ButtonPressed" 0 "ButtonNotPressed";
VAL_ 2365402878 Joystick5Button12PressedStatus 3 "NotAvailable" 2 "ErrorIndicator" 1 "ButtonPressed" 0 "ButtonNotPressed";
VAL_ 2365402878 Joystick5Button5PressedStatus 3 "NotAvailable" 2 "ErrorIndicator" 1 "ButtonPressed" 0 "ButtonNotPressed";
VAL_ 2365402878 Joystick5Button6PressedStatus 3 "NotAvailable" 2 "ErrorIndicator" 1 "ButtonPressed" 0 "ButtonNotPressed";
VAL_ 2365402878 Joystick5Button7PressedStatus 3 "NotAvailable" 2 "ErrorIndicator" 1 "ButtonPressed" 0 "ButtonNotPressed";
VAL_ 2365402878 Joystick5Button8PressedStatus 3 "NotAvailable" 2 "ErrorIndicator" 1 "ButtonPressed" 0 "ButtonNotPressed";
VAL_ 2365402878 Joystick5Button1PressedStatus 3 "NotAvailable" 2 "ErrorIndicator" 1 "ButtonPressed" 0 "ButtonNotPressed";
VAL_ 2365402878 Joystick5Button2PressedStatus 3 "NotAvailable" 2 "ErrorIndicator" 1 "ButtonPressed" 0 "ButtonNotPressed";
VAL_ 2365402878 Joystick5Button3PressedStatus 3 "NotAvailable" 2 "ErrorIndicator" 1 "ButtonPressed" 0 "ButtonNotPressed";
VAL_ 2365402878 Joystick5Button4PressedStatus 3 "NotAvailable" 2 "ErrorIndicator" 1 "ButtonPressed" 0 "ButtonNotPressed";
VAL_ 2365402878 Joystick5XAxisDetentPosStatus 3 "NotAvailable" 2 "ErrorIndicator" 1 "InDetentPos" 0 "NotInDetentPos";
VAL_ 2365402878 Joystick5YAxisDetentPosStatus 3 "NotAvailable" 2 "ErrorIndicator" 1 "InDetentPos" 0 "NotInDetentPos";
VAL_ 2365402878 Jystck5YAxsLvrFrwrdPstvPsStatus 3 "NotAvailable" 2 "ErrorIndicator" 1 "OnPositiveSideOfNeutral" 0 "NotOnPositiveSideOfNeutral";
VAL_ 2365402878 Jystck5YAxsLvrBckNgtvePosStatus 3 "NotAvailable" 2 "ErrorIndicator" 1 "OnNegativeSideOfNeutral" 0 "NotOnNegativeSideOfNeutral";
VAL_ 2365402878 Joystick5YAxisNeutralPosStatus 3 "NotAvailable" 2 "ErrorIndicator" 1 "InNeutralPos" 0 "NotInNeutralPos";
VAL_ 2365402878 Jystck5XAxsLvrRghtPstvPosStatus 3 "NotAvailable" 2 "ErrorIndicator" 1 "OnPositiveSideOfNeutral" 0 "NotOnPositiveSideOfNeutral";
VAL_ 2365402878 Jystck5XAxsLvrLftNgtvePosStatus 3 "NotAvailable" 2 "ErrorIndicator" 1 "OnNegativeSideOfNeutral" 0 "NotOnNegativeSideOfNeutral";
VAL_ 2365402878 Joystick5XAxisNeutralPosStatus 3 "NotAvailable" 2 "ErrorIndicator" 1 "InNeutralPos" 0 "NotInNeutralPos";
VAL_ 2365403390 Joystick4Button9PressedStatus 3 "NotAvailable" 2 "ErrorIndicator" 1 "ButtonPressed" 0 "ButtonNotPressed";
VAL_ 2365403390 Joystick4Button10PressedStatus 3 "NotAvailable" 2 "ErrorIndicator" 1 "ButtonPressed" 0 "ButtonNotPressed";
VAL_ 2365403390 Joystick4Button11PressedStatus 3 "NotAvailable" 2 "ErrorIndicator" 1 "ButtonPressed" 0 "ButtonNotPressed";
VAL_ 2365403390 Joystick4Button12PressedStatus 3 "NotAvailable" 2 "ErrorIndicator" 1 "ButtonPressed" 0 "ButtonNotPressed";
VAL_ 2365403390 Joystick4Button5PressedStatus 3 "NotAvailable" 2 "ErrorIndicator" 1 "ButtonPressed" 0 "ButtonNotPressed";
VAL_ 2365403390 Joystick4Button6PressedStatus 3 "NotAvailable" 2 "ErrorIndicator" 1 "ButtonPressed" 0 "ButtonNotPressed";
VAL_ 2365403390 Joystick4Button7PressedStatus 3 "NotAvailable" 2 "ErrorIndicator" 1 "ButtonPressed" 0 "ButtonNotPressed";
VAL_ 2365403390 Joystick4Button8PressedStatus 3 "NotAvailable" 2 "ErrorIndicator" 1 "ButtonPressed" 0 "ButtonNotPressed";
VAL_ 2365403390 Joystick4Button1PressedStatus 3 "NotAvailable" 2 "ErrorIndicator" 1 "ButtonPressed" 0 "ButtonNotPressed";
VAL_ 2365403390 Joystick4Button2PressedStatus 3 "NotAvailable" 2 "ErrorIndicator" 1 "ButtonPressed" 0 "ButtonNotPressed";
VAL_ 2365403390 Joystick4Button3PressedStatus 3 "NotAvailable" 2 "ErrorIndicator" 1 "ButtonPressed" 0 "ButtonNotPressed";
VAL_ 2365403390 Joystick4Button4PressedStatus 3 "NotAvailable" 2 "ErrorIndicator" 1 "ButtonPressed" 0 "ButtonNotPressed";
VAL_ 2365403390 Joystick4XAxisDetentPosStatus 3 "NotAvailable" 2 "ErrorIndicator" 1 "InDetentPos" 0 "NotInDetentPos";
VAL_ 2365403390 Joystick4YAxisDetentPosStatus 3 "NotAvailable" 2 "ErrorIndicator" 1 "InDetentPos" 0 "NotInDetentPos";
VAL_ 2365403390 Jystck4YAxsLvrFrwrdPstvPsStatus 3 "NotAvailable" 2 "ErrorIndicator" 1 "OnPositiveSideOfNeutral" 0 "NotOnPositiveSideOfNeutral";
VAL_ 2365403390 Jystck4YAxsLvrBckNgtvePosStatus 3 "NotAvailable" 2 "ErrorIndicator" 1 "OnNegativeSideOfNeutral" 0 "NotOnNegativeSideOfNeutral";
VAL_ 2365403390 Joystick4YAxisNeutralPosStatus 3 "NotAvailable" 2 "ErrorIndicator" 1 "InNeutralPos" 0 "NotInNeutralPos";
VAL_ 2365403390 Jystck4XAxsLvrRghtPstvPosStatus 3 "NotAvailable" 2 "ErrorIndicator" 1 "OnPositiveSideOfNeutral" 0 "NotOnPositiveSideOfNeutral";
VAL_ 2365403390 Jystck4XAxsLvrLftNgtvePosStatus 3 "NotAvailable" 2 "ErrorIndicator" 1 "OnNegativeSideOfNeutral" 0 "NotOnNegativeSideOfNeutral";
VAL_ 2365403390 Joystick4XAxisNeutralPosStatus 3 "NotAvailable" 2 "ErrorIndicator" 1 "InNeutralPos" 0 "NotInNeutralPos";
VAL_ 2365400318 Joystick10Button9PressedStatus 3 "NotAvailable" 2 "ErrorIndicator" 1 "ButtonPressed" 0 "ButtonNotPressed";
VAL_ 2365400318 Joystick10Button10PressedStatus 3 "NotAvailable" 2 "ErrorIndicator" 1 "ButtonPressed" 0 "ButtonNotPressed";
VAL_ 2365400318 Joystick10Button11PressedStatus 3 "NotAvailable" 2 "ErrorIndicator" 1 "ButtonPressed" 0 "ButtonNotPressed";
VAL_ 2365400318 Joystick10Button12PressedStatus 3 "NotAvailable" 2 "ErrorIndicator" 1 "ButtonPressed" 0 "ButtonNotPressed";
VAL_ 2365400318 Joystick10Button5PressedStatus 3 "NotAvailable" 2 "ErrorIndicator" 1 "ButtonPressed" 0 "ButtonNotPressed";
VAL_ 2365400318 Joystick10Button6PressedStatus 3 "NotAvailable" 2 "ErrorIndicator" 1 "ButtonPressed" 0 "ButtonNotPressed";
VAL_ 2365400318 Joystick10Button7PressedStatus 3 "NotAvailable" 2 "ErrorIndicator" 1 "ButtonPressed" 0 "ButtonNotPressed";
VAL_ 2365400318 Joystick10Button8PressedStatus 3 "NotAvailable" 2 "ErrorIndicator" 1 "ButtonPressed" 0 "ButtonNotPressed";
VAL_ 2365400318 Joystick10Button1PressedStatus 3 "NotAvailable" 2 "ErrorIndicator" 1 "ButtonPressed" 0 "ButtonNotPressed";
VAL_ 2365400318 Joystick10Button2PressedStatus 3 "NotAvailable" 2 "ErrorIndicator" 1 "ButtonPressed" 0 "ButtonNotPressed";
VAL_ 2365400318 Joystick10Button3PressedStatus 3 "NotAvailable" 2 "ErrorIndicator" 1 "ButtonPressed" 0 "ButtonNotPressed";
VAL_ 2365400318 Joystick10Button4PressedStatus 3 "NotAvailable" 2 "ErrorIndicator" 1 "ButtonPressed" 0 "ButtonNotPressed";
VAL_ 2365400318 Joystick10XAxisDetentPosStatus 3 "NotAvailable" 2 "ErrorIndicator" 1 "InDetentPos" 0 "NotInDetentPos";
VAL_ 2365400318 Joystick10YAxisDetentPosStatus 3 "NotAvailable" 2 "ErrorIndicator" 1 "InDetentPos" 0 "NotInDetentPos";
VAL_ 2365400318 Jystck10YAxsLvrFrwrdPstvPsSttus 3 "NotAvailable" 2 "ErrorIndicator" 1 "OnPositiveSideOfNeutral" 0 "NotOnPositiveSideOfNeutral";
VAL_ 2365400318 Jystck10YAxsLvrBckNgtvPosStatus 3 "NotAvailable" 2 "ErrorIndicator" 1 "OnNegativeSideOfNeutral" 0 "NotOnNegativeSideOfNeutral";
VAL_ 2365400318 Joystick10YAxisNeutralPosStatus 3 "NotAvailable" 2 "ErrorIndicator" 1 "InNeutralPos" 0 "NotInNeutralPos";
VAL_ 2365400318 Jystck10XAxsLvrRghtPstvPsStatus 3 "NotAvailable" 2 "ErrorIndicator" 1 "OnPositiveSideOfNeutral" 0 "NotOnPositiveSideOfNeutral";
VAL_ 2365400318 Jystck10XAxsLvrLftNgtvPosStatus 3 "NotAvailable" 2 "ErrorIndicator" 1 "OnNegativeSideOfNeutral" 0 "NotOnNegativeSideOfNeutral";
VAL_ 2365400318 Joystick10XAxisNeutralPosStatus 3 "NotAvailable" 2 "ErrorIndicator" 1 "InNeutralPos" 0 "NotInNeutralPos";
VAL_ 2499614718 PssngrArbgDctvationSwitchStatus 3 "NotAvailable" 2 "ErrrSttOfDctvtnSwtchCnntBDtrmnd" 1 "PassengerAirbagDeactivated" 0 "PassengerAirbagActivated";
VAL_ 2499614718 Beltlock10Status 3 "NotAvailable" 2 "ErrrBltlckSttCannotBeDetermined" 1 "Locked" 0 "Unlocked";
VAL_ 2499614718 Beltlock9Status 3 "NotAvailable" 2 "ErrrBltlckSttCannotBeDetermined" 1 "Locked" 0 "Unlocked";
VAL_ 2499614718 Beltlock8Status 3 "NotAvailable" 2 "ErrrBltlckSttCannotBeDetermined" 1 "Locked" 0 "Unlocked";
VAL_ 2499614718 Beltlock7Status 3 "NotAvailable" 2 "ErrrBltlckSttCannotBeDetermined" 1 "Locked" 0 "Unlocked";
VAL_ 2499614718 Beltlock6Status 3 "NotAvailable" 2 "ErrrBltlckSttCannotBeDetermined" 1 "Locked" 0 "Unlocked";
VAL_ 2499614718 Beltlock5Status 3 "NotAvailable" 2 "ErrrBltlckSttCannotBeDetermined" 1 "Locked" 0 "Unlocked";
VAL_ 2499614718 Beltlock4Status 3 "NotAvailable" 2 "ErrrBltlckSttCannotBeDetermined" 1 "Locked" 0 "Unlocked";
VAL_ 2499614718 Beltlock3Status 3 "NotAvailable" 2 "ErrrBltlckSttCannotBeDetermined" 1 "Locked" 0 "Unlocked";
VAL_ 2499614718 PassengerBeltlockStatus 3 "NotAvailable" 2 "ErrrBltlckSttCannotBeDetermined" 1 "Locked" 0 "Unlocked";
VAL_ 2499614718 DriverBeltlockStatus 3 "NotAvailable" 2 "ErrrBltlckSttCannotBeDetermined" 1 "Locked" 0 "Unlocked";
VAL_ 2566722814 BatteryCharger2PowerLineState 1 "CnnctdPwrLnIsCnnctdToTheCharger" 0 "DscnnctdPwrLnIsDscnnctdFrmThChr";
VAL_ 2566722814 BatteryCharger2State 1 "ChargingBattery" 0 "IdlngPwrLnThBttryIsDscnnctdFrmT";
VAL_ 2566723070 BatteryCharger1PowerLineState 1 "CnnctdPwrLnIsCnnctdToTheCharger" 0 "DscnnctdPwrLnIsDscnnctdFrmThChr";
VAL_ 2566723070 BatteryCharger1State 1 "ChargingBattery" 0 "IdlngPwrLnThBttryIsDscnnctdFrmT";
VAL_ 2566735102 Aftertreatment2FuelPress2Ctrl 4 "fullyOpen";
VAL_ 2566735102 Aftrtrtmnt2FlFlwDvrterValveCtrl 3 "notAvailable" 2 "reservedForSAEAssignment" 1 "on" 0 "off";
VAL_ 2566735102 Aftrtreatment2FuelPumpRelayCtrl 3 "notAvailable" 2 "reservedForSAEAssignment" 1 "on" 0 "off";
VAL_ 2566805246 AftrtrtmntSCROprtrIndcmntSvrity 7 "NotAvailable_NotSupported" 6 "Reserved" 5 "InducementLevel5" 4 "InducementLevel4" 3 "InducementLevel3" 2 "InducementLevel2" 1 "InducementLevel1" 0 "NoInducementActive";
VAL_ 2566805246 Aftrtrtmnt1DEFTnkLwLvlIndicator 7 "notAvailable" 4 "OnFastBlink" 6 "reservedForSAEAssignment" 1 "OnSolid" 0 "Off";
VAL_ 2566805246 Aftrtrtmnt1SCRCatalystTankLevel 4 "Full" 0 "Empty";
VAL_ 2566711806 ArmrestSwitchMatrix2Switch2 3 "DontCare_TakeNoAction" 2 "Reserved" 1 "On" 0 "Off";
VAL_ 2566711806 ArmrestSwitchMatrix2Switch1 3 "DontCare_TakeNoAction" 2 "Reserved" 1 "On" 0 "Off";
VAL_ 2566711806 ArmrestSwitchMatrixSwitch2 3 "DontCare_TakeNoAction" 2 "Reserved" 1 "On" 0 "Off";
VAL_ 2566711806 ArmrestSwitchMatrixSwitch1 3 "DontCare_TakeNoAction" 2 "Reserved" 1 "On" 0 "Off";
VAL_ 2364549886 YawRateExRangeFigureOfMerit 3 "NotAvailable" 2 "Error" 1 "YwRtDgrddDtIsSspctDTEnvrnmntlCn" 0 "YwRtFllyFnctnlDtIsWthnSnsrSpcfc";
VAL_ 2364549886 RollRateExRangeFigureOfMerit 3 "NotAvailable" 2 "Error" 1 "RllRtDgrddDtIsSspctDTEnvrnmntlC" 0 "RllRtFllyFnctnlDtIsWthnSnsrSpcf";
VAL_ 2364549886 PitchRateExRangeFigureOfMerit 3 "NotAvailable" 2 "Error" 1 "PtchRtDgrddDtIsSspctDTEnvrnmntl" 0 "PtchRtFllyFnctnlDtIsWthnSnsrSpc";
VAL_ 2566712318 Aftrtrtmnt2NOxAdsrbrDSOxRgnrtnSt 3 "NotAvailable" 2 "ErrorIndicator" 1 "Active" 0 "Inactive";
VAL_ 2566712318 Aftrtrtmnt2NOxAdsrbrDNOxRgnrtnSt 3 "NotAvailable" 2 "ErrorIndicator" 1 "Active" 0 "Inactive";
VAL_ 2566712574 Aftrtrtmnt1NOxAdsrbrDSOxRgnrtnSt 3 "NotAvailable" 2 "ErrorIndicator" 1 "Active" 0 "Inactive";
VAL_ 2566712574 Aftrtrtmnt1NOxAdsrbrDNOxRgnrtnSt 3 "NotAvailable" 2 "ErrorIndicator" 1 "Active" 0 "Inactive";
VAL_ 2566731262 Aftrtrtmnt2SCRCatalystTankLevel 4 "Full" 0 "Empty";
VAL_ 2566730750 Aftrtrtmnt2SCRCtlystRgntPmpStte 3 "notAvailable" 2 "reservedForSAEAssignment" 1 "pumpError" 0 "pumpOperational";
VAL_ 2566731518 Aftrtrtmnt2SCRCtlystReagentType 15 "NotAvailable" 14 "ErrrDtctdWthUrRgntTypeDetection" 13 "NtAblTDtrmneCatalystReagentType" 5 "to1100ReservedForSAEAssignment" 3 "CatalystReagentIsProperMixture" 2 "CatalystReagentIsDiesel" 1 "CtlystRgntIsUrCncntrationTooLow" 0 "CtlystRgntIsUrCncntrtionTooHigh";
VAL_ 2164079358 Aftrtrtmnt2SCRCtlystRgntLnHter4 3 "notAvailable" 2 "rservedForFutureAssignmentBySAE" 1 "RqForHeaterToBeActive" 0 "RqForHeaterToBeInactive";
VAL_ 2164079358 Aftrtrtmnt2SCRCtlystRgntLnHter3 3 "notAvailable" 2 "rservedForFutureAssignmentBySAE" 1 "RqForHeaterToBeActive" 0 "RqForHeaterToBeInactive";
VAL_ 2164079358 Aftrtrtmnt2SCRCtlystRgntLnHter2 3 "notAvailable" 2 "rservedForFutureAssignmentBySAE" 1 "RqForHeaterToBeActive" 0 "RqForHeaterToBeInactive";
VAL_ 2164079358 Aftrtrtmnt2SCRCtlystRgntLnHter1 3 "notAvailable" 2 "rservedForFutureAssignmentBySAE" 1 "RqForHeaterToBeActive" 0 "RqForHeaterToBeInactive";
VAL_ 2164079358 Aftrtrtmnt2SCRDserHeatingModeRq 7 "NotAvailable" 4 "110Reserved" 3 "HeaterOn" 2 "HeaterAutomaticMode" 1 "HeaterEconomyMode" 0 "HeaterOff";
VAL_ 2164079358 Aftrtrtmnt2SCRDsrFltSpprssionRq 3 "NotAvailable" 2 "Reserved" 1 "ErrorSuppressionOn" 0 "ErrorSuppressionOff";
VAL_ 2364549118 Aftrtratment2SCRSystemRqedState 15 "NotAvailable" 14 "Error" 11 "1101RsrvdFrFtureAssignmentBySAE" 10 "ServiceTestModeDosingNotAllowed" 9 "ServiceTestModeDosingAllowed" 8 "Diagnosis" 7 "Shutoff" 6 "ProtectModeAgainstCold" 5 "ProtectModeAgainstHeat" 4 "RservedForFutureAssignmentBySAE" 3 "SystemErrorPending" 2 "NormalDosingOperation" 1 "PreparingDosingReadiness" 0 "Dormant";
VAL_ 2566732798 Aftrtrtmnt2SCRCtlystRgntLnHtr4St 3 "notAvailable" 2 "error" 1 "heaterActive" 0 "heaterInactive";
VAL_ 2566732798 Aftrtrtmnt2SCRCtlystRgntLnHtr3St 3 "notAvailable" 2 "error" 1 "heaterActive" 0 "heaterInactive";
VAL_ 2566732798 Aftrtrtmnt2SCRCtlystRgntLnHtr2St 3 "notAvailable" 2 "error" 1 "heaterActive" 0 "heaterInactive";
VAL_ 2566732798 Aftrtrtmnt2SCRCtlystRgntLnHtr1St 3 "notAvailable" 2 "error" 1 "heaterActive" 0 "heaterInactive";
VAL_ 2566732798 Aftrtrtmnt2SCRFedbackCtrlStatus 7 "notAvailable" 6 "error" 5 "rservedForFutureAssignmentBySAE" 1 "closedLoopCtrlActive" 0 "openLoopCtrlActive";
VAL_ 2566732798 Aftrtrtmnt2SCRDsngVlvExhstTmpRdc 7 "NotAvailable" 6 "Error" 5 "RservedForFutureAssignmentBySAE" 2 "ReductionRqStage2" 1 "ReductionRqStage1" 0 "NoRq";
VAL_ 2364548862 Aftertreatment2SCRSystemState 15 "NotAvailable" 14 "Error" 11 "1101RsrvdFrFtureAssignmentBySAE" 10 "ServiceTestModeDosingNotAllowed" 9 "ServiceTestModeDosingAllowed" 8 "Diagnosis" 7 "Shutoff" 6 "ProtectModeAgainstCold" 5 "ProtectModeAgainstHeat" 4 "RservedForFutureAssignmentBySAE" 3 "SystemErrorPending" 2 "NormalDosingOperation" 1 "PreparingDosingReadiness" 0 "Dormant";
VAL_ 2364549374 Aftrtrtmnt2OtltNH3GsSnsrHtrCtrl 3 "HeaterOffNotAvailable" 2 "Preheat1" 1 "Preheat2" 0 "Automatic";
VAL_ 2566733054 Aftrtrtmnt1SCRCtlystRgntPmpStte 3 "notAvailable" 2 "reservedForSAEAssignment" 1 "pumpError" 0 "pumpOperational";
VAL_ 2566734078 Aftrtrtmnt1SCRCtlystRgntLnHter4 3 "notAvailable" 2 "rservedForFutureAssignmentBySAE" 1 "RqForHeaterToBeActive" 0 "RqForHeaterToBeInactive";
VAL_ 2566734078 Aftrtrtmnt1SCRCtlystRgntLnHter3 3 "notAvailable" 2 "rservedForFutureAssignmentBySAE" 1 "RqForHeaterToBeActive" 0 "RqForHeaterToBeInactive";
VAL_ 2566734078 Aftrtrtmnt1SCRCtlystRgntLnHter2 3 "notAvailable" 2 "rservedForFutureAssignmentBySAE" 1 "RqForHeaterToBeActive" 0 "RqForHeaterToBeInactive";
VAL_ 2566734078 Aftrtrtmnt1SCRCtlystRgntLnHter1 3 "notAvailable" 2 "rservedForFutureAssignmentBySAE" 1 "RqForHeaterToBeActive" 0 "RqForHeaterToBeInactive";
VAL_ 2566734078 Aftrtrtmnt1SCRDserHeatingModeRq 7 "NotAvailable" 4 "110Reserved" 3 "HeaterOn" 2 "HeaterAutomaticMode" 1 "HeaterEconomyMode" 0 "HeaterOff";
VAL_ 2566734078 Aftrtrtmnt1SCRDsrFltSpprssionRq 3 "NotAvailable" 2 "Reserved" 1 "ErrorSuppressionOn" 0 "ErrorSuppressionOff";
VAL_ 2364548350 Aftrtratment1SCRSystemRqedState 15 "NotAvailable" 14 "Error" 11 "1101RsrvdFrFtureAssignmentBySAE" 10 "ServiceTestModeDosingNotAllowed" 9 "ServiceTestModeDosingAllowed" 8 "Diagnosis" 7 "Shutoff" 6 "ProtectModeAgainstCold" 5 "ProtectModeAgainstHeat" 4 "RservedForFutureAssignmentBySAE" 3 "SystemErrorPending" 2 "NormalDosingOperation" 1 "PreparingDosingReadiness" 0 "Dormant";
VAL_ 2566734334 Aftrtrtmnt1SCRCtlystRgntLnHtr4St 3 "notAvailable" 2 "error" 1 "heaterActive" 0 "heaterInactive";
VAL_ 2566734334 Aftrtrtmnt1SCRCtlystRgntLnHtr3St 3 "notAvailable" 2 "error" 1 "heaterActive" 0 "heaterInactive";
VAL_ 2566734334 Aftrtrtmnt1SCRCtlystRgntLnHtr2St 3 "notAvailable" 2 "error" 1 "heaterActive" 0 "heaterInactive";
VAL_ 2566734334 Aftrtrtmnt1SCRCtlystRgntLnHtr1St 3 "notAvailable" 2 "error" 1 "heaterActive" 0 "heaterInactive";
VAL_ 2566734334 Aftrtrtmnt1SCRFedbackCtrlStatus 7 "notAvailable" 6 "error" 5 "rservedForFutureAssignmentBySAE" 1 "closedLoopCtrlActive" 0 "openLoopCtrlActive";
VAL_ 2566734334 Aftrtrtmnt1SCRDsngVlvExhstTmpRdc 7 "NotAvailable" 6 "Error" 5 "RservedForFutureAssignmentBySAE" 2 "ReductionRqStage2" 1 "ReductionRqStage1" 0 "NoRq";
VAL_ 2364548094 Aftertreatment1SCRSystemState 15 "NotAvailable" 14 "Error" 11 "1101RsrvdFrFtureAssignmentBySAE" 10 "ServiceTestModeDosingNotAllowed" 9 "ServiceTestModeDosingAllowed" 8 "Diagnosis" 7 "Shutoff" 6 "ProtectModeAgainstCold" 5 "ProtectModeAgainstHeat" 4 "RservedForFutureAssignmentBySAE" 3 "SystemErrorPending" 2 "NormalDosingOperation" 1 "PreparingDosingReadiness" 0 "Dormant";
VAL_ 2364548606 Aftrtrtmnt1OtltNH3GsSnsrHtrCtrl 3 "HeaterOffNotAvailable" 2 "Preheat1" 1 "Preheat2" 0 "Automatic";
